[part 9 of 23: package /Cluster]
AUTOSAR XML (schema 4-3-0)
package /Cluster  (continued)
  can cluster E3V_EVCANFD: baudrate=500000, protocol-name=CAN, protocol-version=2.0, bus-off-recovery={bor-counter-l-1-to-l-2=1, bor-time-l-1=0.05, bor-time-l-2=0.2}, can-fd-baudrate=2000000  (continued)
    can physical channel CHNL: comm-connectors=CN_E3V_EVCANFD  (continued)
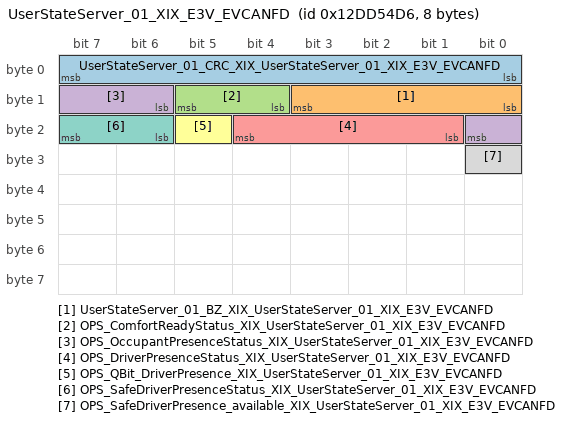
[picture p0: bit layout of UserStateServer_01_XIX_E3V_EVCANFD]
      frame UserStateServer_01_XIX_E3V_EVCANFD: id 0x12DD54D6, to Klima, frame-length=8, can-addressing-mode=EXTENDED, can-frame-rx-behavior=CAN-FD, can-frame-tx-behavior=CAN-FD
        pdu UserStateServer_01_XIX_E3V_EVCANFD: length=8, minimum-delay=0.01, transmission-mode-true-timing={cyclic-timing={time-offset=0.0, time-period=0.1}, event-controlled-timing={number-of-repetitions=5, repetition-period=0.01}}, unused-bit-pattern=0
          signal UserStateServer_01_CRC_XIX_UserStateServer_01_XIX_E3V_EVCANFD: start 0, 8 bit, little-endian, data-type-policy=OVERRIDE, i-signal-type=PRIMITIVE, base-type=BT_UserStateServer_01_CRC, compu {phys=raw for raw 0..255}, range phys 0..255, raw 0..255, transfer-property=PENDING  # Für MLB: Berechnung siehe Lastenheft "Kommunikationsabsicherung für FlexRay und CAN" Ab MQB und MLBevo: Berechnung siehe Lastenheft "End-to-End Kommunikationsabsicherung" Endwerte siehe Begleitdokument "S-PDU Kennungsfolgen"
          signal UserStateServer_01_BZ_XIX_UserStateServer_01_XIX_E3V_EVCANFD: start 8, 4 bit, little-endian, data-type-policy=OVERRIDE, i-signal-type=PRIMITIVE, base-type=BT_UserStateServer_01_BZ, compu {phys=raw for raw 0..15}, range phys 0..15, raw 0..15, transfer-property=PENDING  # 4bit Botschaftszähler, wird mit jeder Sendebotschaft inkrementiert
          signal OPS_ComfortReadyStatus_XIX_UserStateServer_01_XIX_E3V_EVCANFD: start 12, 2 bit, little-endian, data-type-policy=OVERRIDE, i-signal-type=PRIMITIVE, init-value=0, base-type=BT_OPS_ComfortReadyStatus, invalid-value=Invalid_OPS_ComfortReadyStatus_XIX_UserStateServer_01_XIX_E3V_EVCANFD:3, compu {0=Cx0_Init (CM_OPS_ComfortReadyStatus_Cx0_Init), 1=Cx1_aktiv (CM_OPS_ComfortReadyStatus_Cx1_aktiv), 2=Cx2_inaktiv (CM_OPS_ComfortReadyStatus_Cx2_inaktiv), 3=Cx3_Fehler (CM_OPS_ComfortReadyStatus_Cx3_Fehler)}, range raw 0..3, transfer-property=TRIGGERED-ON-CHANGE, to Klima(timeout 1 s)  # Das Signal wird durch den Basisdienst User State Server (Technikvariante: OccupantPresenceService) erzeugt und bildet einen neuen Zustand, bestehend aus einer Verknüpfung der Fahreranwesenheit (Fahrer abwesend / Fahrer anwesend) und der Klemmensteuerung (Klemme15/KlemmeS).Wird u.a. für das neue MEB Einstiegs-/Ausstiegskonzept verwendet.
          signal OPS_OccupantPresenceStatus_XIX_UserStateServer_01_XIX_E3V_EVCANFD: start 14, 3 bit, little-endian, data-type-policy=OVERRIDE, i-signal-type=PRIMITIVE, init-value=0, base-type=BT_OPS_OccupantPresenceStatus, invalid-value=Invalid_OPS_OccupantPresenceStatus_XIX_UserStateServer_01_XIX_E3V_EVCANFD:7, compu {0=Cx0_Init (CM_OPS_OccupantPresenceStatus_Cx0_Init), 1=Cx1_OccupantAbsent (CM_OPS_OccupantPresenceStatus_Cx1_OccupantAbsent), 2=Cx2_reserviert (CM_OPS_OccupantPresenceStatus_Cx2_reserviert), 3=Cx3_OccupantEntryExit (CM_OPS_OccupantPresenceStatus_Cx3_OccupantEntryExit), 4=Cx4_reserviert (CM_OPS_OccupantPresenceStatus_Cx4_reserviert), 5=Cx5_OccupantPresent (CM_OPS_OccupantPresenceStatus_Cx5_OccupantPresent), 6=Cx6_OccupantPresentVerified (CM_OPS_OccupantPresenceStatus_Cx6_OccupantPresentVerified), 7=Cx7_Fehler (CM_OPS_OccupantPresenceStatus_Cx7_Fehler)}, range raw 0..7, transfer-property=TRIGGERED-ON-CHANGE, to Klima(timeout 1 s)  # Das Signal wird durch den Basisdienst User State Server (Service: OccupantPresenceService) erzeugt und bildet die Anwesenheit und Abwesenheit aller Insassen im Fahrzeug ab.
          signal OPS_DriverPresenceStatus_XIX_UserStateServer_01_XIX_E3V_EVCANFD: start 17, 4 bit, little-endian, data-type-policy=OVERRIDE, i-signal-type=PRIMITIVE, init-value=0, base-type=BT_OPS_DriverPresenceStatus, invalid-value=Invalid_OPS_DriverPresenceStatus_XIX_UserStateServer_01_XIX_E3V_EVCANFD:15, compu {0=Cx0_Init (CM_OPS_DriverPresenceStatus_Cx0_Init), 1=Cx1_reserviert (CM_OPS_DriverPresenceStatus_Cx1_reserviert), 2=Cx2_DriverAbsent (CM_OPS_DriverPresenceStatus_Cx2_DriverAbsent), 3=Cx3_reserviert (CM_OPS_DriverPresenceStatus_Cx3_reserviert), 4=Cx4_DriverEntry (CM_OPS_DriverPresenceStatus_Cx4_DriverEntry), 5=Cx5_reserviert (CM_OPS_DriverPresenceStatus_Cx5_reserviert), 6=Cx6_DriverPresent (CM_OPS_DriverPresenceStatus_Cx6_DriverPresent), 7=Cx7_reserviert (CM_OPS_DriverPresenceStatus_Cx7_reserviert), 8=Cx8_DriverPresentVerified (CM_OPS_DriverPresenceStatus_Cx8_DriverPresentVerified), 9=Cx9_reserviert (CM_OPS_DriverPresenceStatus_Cx9_reserviert), 10=Cxa_reserviert (CM_OPS_DriverPresenceStatus_Cxa_reserviert), 11=Cxb_DriverExitIntent (CM_OPS_DriverPresenceStatus_Cxb_DriverExitIntent), 12=Cxc_reserviert (CM_OPS_DriverPresenceStatus_Cxc_reserviert), 13=Cxd_DriverExit (CM_OPS_DriverPresenceStatus_Cxd_DriverExit), 14=Cxe_reserviert (CM_OPS_DriverPresenceStatus_Cxe_reserviert), 15=Cxf_Fehler (CM_OPS_DriverPresenceStatus_Cxf_Fehler)}, range raw 0..15, transfer-property=TRIGGERED-ON-CHANGE, to Klima(timeout 1 s)  # Das Signal wird durch den Basisdienst User State Server (Service: OccupantPresenceService) erzeugt und bildet die Fahrerzustände im Fahrzeug ab.
          signal OPS_QBit_DriverPresence_XIX_UserStateServer_01_XIX_E3V_EVCANFD: start 21, 1 bit, little-endian, data-type-policy=OVERRIDE, i-signal-type=PRIMITIVE, init-value=1, base-type=BT_OPS_QBit_DriverPresence, compu {0=Cx0_gueltiger_Wert (CM_OPS_QBit_DriverPresence_Cx0_gueltiger_Wert), 1=Cx1_Ersatz_Init_oder_Fehlerwert (CM_OPS_QBit_DriverPresence_Cx1_Ersatz_Init_oder_Fehlerwert)}, range raw 0..1, transfer-property=TRIGGERED-ON-CHANGE, to Klima(timeout 1 s)  # Das Signal wird durch den Basisdienst User State Server (Service: OccupantPresenceService) erzeugt und signalisiert die Qualität der Fahrerzustände.
          signal OPS_SafeDriverPresenceStatus_XIX_UserStateServer_01_XIX_E3V_EVCANFD: start 22, 2 bit, little-endian, data-type-policy=OVERRIDE, i-signal-type=PRIMITIVE, init-value=0, base-type=BT_OPS_SafeDriverPresenceStatus, invalid-value=Invalid_OPS_SafeDriverPresenceStatus_XIX_UserStateServer_01_XIX_E3V_EVCANFD:3, compu {0=Cx0_Init (CM_OPS_SafeDriverPresenceStatus_Cx0_Init), 1=Cx1_Driver_Safe_Present (CM_OPS_SafeDriverPresenceStatus_Cx1_Driver_Safe_Present), 2=Cx2_Driver_Not_Safe_Present (CM_OPS_SafeDriverPresenceStatus_Cx2_Driver_Not_Safe_Present), 3=Cx3_Fehler (CM_OPS_SafeDriverPresenceStatus_Cx3_Fehler)}, range raw 0..3, transfer-property=TRIGGERED-ON-CHANGE  # Signalisierung einer sicheren Fahreranwesenheit nach ASIL B
          signal OPS_SafeDriverPresence_available_XIX_UserStateServer_01_XIX_E3V_EVCANFD: start 24, 1 bit, little-endian, data-type-policy=OVERRIDE, i-signal-type=PRIMITIVE, init-value=0, base-type=BT_OPS_SafeDriverPresence_available, compu {0=Cx0_Verfuegbar (CM_OPS_SafeDriverPresence_available_Cx0_Verfuegbar), 1=Cx1_Verfuegbar_eingeschr_Performance (CM_OPS_SafeDriverPresence_available_Cx1_Verfuegbar_eingeschr_Performance)}, range raw 0..1, transfer-property=TRIGGERED-ON-CHANGE  # Das Signal signalisiert inwiefern alle vorgesehene Sensoren für die Anwesenheit verwendet werden oder möglichweise bestimmte Sensoren nicht verfügbar sind. In beiden Fällen wird eine Anwesenheit berechnet, jedoch bei Ausfall bestimmter Sensoren kann zu bestimmten Einschränkungen führen. Das Signal wird funktional und ohne ASIL Güte bedient.
      frame VIN_01_XIX_E3V_EVCANFD: id 0x6B4, to Klima, frame-length=8, can-addressing-mode=STANDARD, can-frame-rx-behavior=CAN-FD, can-frame-tx-behavior=CAN-FD
        multiplexed i pdu VIN_01_XIX_E3V_EVCANFD:
          length=8
          dynamic-part{segment-position{segment-byte-order=little-endian, segment-length=64, segment-position=0}, dynamic-part-alternatives=[{i-pdu=VIN_01_Mx00_XIX_E3V_EVCANFD, initial-dynamic-part=true, selector-field-code=0}, {i-pdu=VIN_01_Mx01_XIX_E3V_EVCANFD, initial-dynamic-part=false, selector-field-code=1}, {i-pdu=VIN_01_Mx02_XIX_E3V_EVCANFD, initial-dynamic-part=false, selector-field-code=2}]}
          selector-field-byte-order=little-endian
          selector-field-length=2
          selector-field-start-position=0
          trigger-mode=DYNAMIC-PART-TRIGGER
          unused-bit-pattern=0
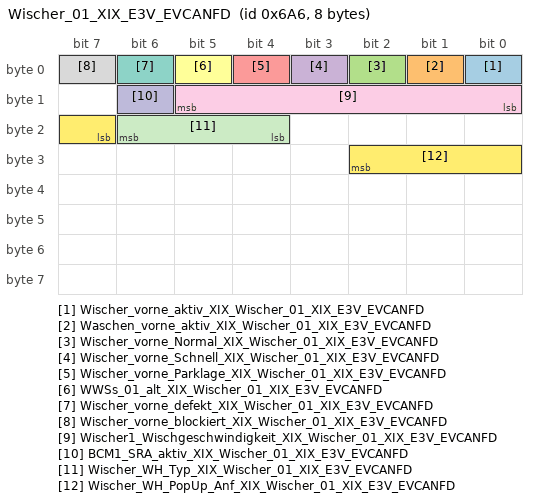
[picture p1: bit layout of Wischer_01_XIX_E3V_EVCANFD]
      frame Wischer_01_XIX_E3V_EVCANFD: id 0x6A6, to Klima, frame-length=8, can-addressing-mode=STANDARD, can-frame-rx-behavior=CAN-FD, can-frame-tx-behavior=CAN-FD
        pdu Wischer_01_XIX_E3V_EVCANFD: length=8, minimum-delay=0.05, transmission-mode-true-timing={cyclic-timing={time-offset=0.0, time-period=1.0}, event-controlled-timing={number-of-repetitions=0, repetition-period=0.0}}, unused-bit-pattern=0  # MLBevo
          signal Wischer_vorne_aktiv_XIX_Wischer_01_XIX_E3V_EVCANFD: start 0, 1 bit, little-endian, data-type-policy=OVERRIDE, i-signal-type=PRIMITIVE, init-value=0, base-type=BT_Wischer_vorne_aktiv, compu {0=Cx0_Init (CM_Wischer_vorne_aktiv_Cx0_Init), 1=Cx1_Wischer_vorne_laeuft (CM_Wischer_vorne_aktiv_Cx1_Wischer_vorne_laeuft)}, range raw 0..1, transfer-property=TRIGGERED-ON-CHANGE-WITHOUT-REPETITION, to Klima(timeout 5 s)  # Status: Wischer vorne
          signal Waschen_vorne_aktiv_XIX_Wischer_01_XIX_E3V_EVCANFD: start 1, 1 bit, little-endian, data-type-policy=OVERRIDE, i-signal-type=PRIMITIVE, init-value=0, base-type=BT_Waschen_vorne_aktiv, compu {0=Cx0_inaktiv (CM_Waschen_vorne_aktiv_Cx0_inaktiv), 1=Cx1_Waschen_aktiv (CM_Waschen_vorne_aktiv_Cx1_Waschen_aktiv)}, range raw 0..1, transfer-property=TRIGGERED-ON-CHANGE-WITHOUT-REPETITION, to Klima(timeout 5 s)  # Status: Waschen vorne aktiv
          signal Wischer_vorne_Normal_XIX_Wischer_01_XIX_E3V_EVCANFD: start 2, 1 bit, little-endian, data-type-policy=OVERRIDE, i-signal-type=PRIMITIVE, init-value=0, base-type=BT_Wischer_vorne_Normal, compu {1=Cx1_Wischer_Front_normal_aktiv (CM_Wischer_vorne_Normal_Cx1_Wischer_Front_normal_aktiv) (Wischer Front normal aktiv)}, range raw 1, transfer-property=TRIGGERED-ON-CHANGE-WITHOUT-REPETITION  # Wischer Front normal aktiv
          signal Wischer_vorne_Schnell_XIX_Wischer_01_XIX_E3V_EVCANFD: start 3, 1 bit, little-endian, data-type-policy=OVERRIDE, i-signal-type=PRIMITIVE, init-value=0, base-type=BT_Wischer_vorne_Schnell, compu {1=Cx1_Wischer_vorne_schnell_aktiv (CM_Wischer_vorne_Schnell_Cx1_Wischer_vorne_schnell_aktiv) (Wischer vorne schnell aktiv)}, range raw 1, transfer-property=TRIGGERED-ON-CHANGE-WITHOUT-REPETITION  # Wischer vorne schnell aktiv
          signal Wischer_vorne_Parklage_XIX_Wischer_01_XIX_E3V_EVCANFD: start 4, 1 bit, little-endian, data-type-policy=OVERRIDE, i-signal-type=PRIMITIVE, init-value=1, base-type=BT_Wischer_vorne_Parklage, compu {0=Cx0_Wischer_Front_nicht_in_Parklage (CM_Wischer_vorne_Parklage_Cx0_Wischer_Front_nicht_in_Parklage), 1=Cx1_Wischer_Front_in_Parklage_Initialzustand (CM_Wischer_vorne_Parklage_Cx1_Wischer_Front_in_Parklage_Initialzustand) (Wischer_Front_in_Parklage__Initialzustand)}, range raw 0..1, transfer-property=TRIGGERED-ON-CHANGE-WITHOUT-REPETITION  # Wischer Front in Parklage
          signal WWSs_01_alt_XIX_Wischer_01_XIX_E3V_EVCANFD: start 5, 1 bit, little-endian, data-type-policy=OVERRIDE, i-signal-type=PRIMITIVE, init-value=1, base-type=BT_WWSs_01_alt, compu {0=Cx0_aktuell (CM_WWSs_01_alt_Cx0_aktuell), 1=Cx1_veraltet (CM_WWSs_01_alt_Cx1_veraltet)}, range raw 0..1, transfer-property=PENDING  # Veraltet Bit für die LIN-Botschaft WWSs_01. Betroffene Signale: Wischer_vorne_aktiv
          signal Wischer_vorne_defekt_XIX_Wischer_01_XIX_E3V_EVCANFD: start 6, 1 bit, little-endian, data-type-policy=OVERRIDE, i-signal-type=PRIMITIVE, init-value=0, base-type=BT_Wischer_vorne_defekt, compu {0=Cx0_Init (CM_Wischer_vorne_defekt_Cx0_Init), 1=Cx1_Wischer_vorne_defekt (CM_Wischer_vorne_defekt_Cx1_Wischer_vorne_defekt) (Wischer vorne defekt)}, range raw 0..1, transfer-property=TRIGGERED-ON-CHANGE-WITHOUT-REPETITION, to Klima(timeout 5 s)  # Fehlerstatus Wischer vorne (Anzeige im Kombi)
          signal Wischer_vorne_blockiert_XIX_Wischer_01_XIX_E3V_EVCANFD: start 7, 1 bit, little-endian, data-type-policy=OVERRIDE, i-signal-type=PRIMITIVE, init-value=0, base-type=BT_Wischer_vorne_blockiert, compu {1=Cx1_Wischer_vorne_blockiert (CM_Wischer_vorne_blockiert_Cx1_Wischer_vorne_blockiert) (Wischer vorne blockiert)}, range raw 1, transfer-property=TRIGGERED-ON-CHANGE-WITHOUT-REPETITION  # Blockade Wischer vorne (z.B. durch Schnee)
          signal Wischer1_Wischgeschwindigkeit_XIX_Wischer_01_XIX_E3V_EVCANFD: start 8, 6 bit, little-endian, data-type-policy=OVERRIDE, i-signal-type=PRIMITIVE, init-value=62, base-type=BT_Wischer1_Wischgeschwindigkeit, invalid-value=Invalid_Wischer1_Wischgeschwindigkeit_XIX_Wischer_01_XIX_E3V_EVCANFD:63, compu {0=Cx0_0_U_min (CM_Wischer1_Wischgeschwindigkeit_Cx0_0_U_min) (0 U/min), phys=raw+9 for raw 1..61, 62=Cx3e_Init (CM_Wischer1_Wischgeschwindigkeit_Cx3e_Init), 63=Cx3f_Fehler (CM_Wischer1_Wischgeschwindigkeit_Cx3f_Fehler); unit Unit_MinutInver}, range phys 10..70 Unit_MinutInver, raw 0..63, unit=Unit_MinutInver, transfer-property=PENDING, to Klima(timeout 5 s)  # aktuelle, durch Sensorik gemessene Wischgeschwindigkeit
          signal BCM1_SRA_aktiv_XIX_Wischer_01_XIX_E3V_EVCANFD: start 14, 1 bit, little-endian, data-type-policy=OVERRIDE, i-signal-type=PRIMITIVE, init-value=0, base-type=BT_BCM1_SRA_aktiv, compu {0=Cx0_nicht_aktiv (CM_BCM1_SRA_aktiv_Cx0_nicht_aktiv) (nicht aktiv), 1=Cx1_aktiv (CM_BCM1_SRA_aktiv_Cx1_aktiv)}, range raw 0..1, transfer-property=TRIGGERED-ON-CHANGE-WITHOUT-REPETITION  # Status Scheinwerferreinigungsanlage
          signal Wischer_WH_Typ_XIX_Wischer_01_XIX_E3V_EVCANFD: start 20, 3 bit, little-endian, data-type-policy=OVERRIDE, i-signal-type=PRIMITIVE, init-value=0, base-type=BT_Wischer_WH_Typ, compu {0=Cx0_Lenkstockschalter_0_Int_Stufen (CM_Wischer_WH_Typ_Cx0_Lenkstockschalter_0_Int_Stufen), 1=Cx1_Lenkstockschalter_2_Int_Stufen (CM_Wischer_WH_Typ_Cx1_Lenkstockschalter_2_Int_Stufen), 2=Cx2_Lenkstockschalter_4_Int_Stufen (CM_Wischer_WH_Typ_Cx2_Lenkstockschalter_4_Int_Stufen)}, range raw 0..2, transfer-property=PENDING  # Signal beinhaltet Lenkstockschaltertyp für grafische Anzeige im Kombi zur Wischerfunktion
          signal Wischer_WH_PopUp_Anf_XIX_Wischer_01_XIX_E3V_EVCANFD: start 23, 4 bit, little-endian, data-type-policy=OVERRIDE, i-signal-type=PRIMITIVE, init-value=0, base-type=BT_Wischer_WH_PopUp_Anf, compu {0=Cx0_keine_Anzeige (CM_Wischer_WH_PopUp_Anf_Cx0_keine_Anzeige), 1=Cx1_Intervallstufe_1_aktiv (CM_Wischer_WH_PopUp_Anf_Cx1_Intervallstufe_1_aktiv), 2=Cx2_Intervallstufe_2_aktiv (CM_Wischer_WH_PopUp_Anf_Cx2_Intervallstufe_2_aktiv), 3=Cx3_Intervallstufe_3_aktiv (CM_Wischer_WH_PopUp_Anf_Cx3_Intervallstufe_3_aktiv), 4=Cx4_Intervallstufe_4_aktiv (CM_Wischer_WH_PopUp_Anf_Cx4_Intervallstufe_4_aktiv), 5=Cx5_Regensensorstufe_1_aktiv (CM_Wischer_WH_PopUp_Anf_Cx5_Regensensorstufe_1_aktiv), 6=Cx6_Regensensorstufe_2_aktiv (CM_Wischer_WH_PopUp_Anf_Cx6_Regensensorstufe_2_aktiv), 7=Cx7_Regensensorstufe_3_aktiv (CM_Wischer_WH_PopUp_Anf_Cx7_Regensensorstufe_3_aktiv), 8=Cx8_Regensensorstufe_4_aktiv (CM_Wischer_WH_PopUp_Anf_Cx8_Regensensorstufe_4_aktiv), 9=Cx9_Wischerstufe_1_aktiv (CM_Wischer_WH_PopUp_Anf_Cx9_Wischerstufe_1_aktiv), 10=Cxa_Wischerstufe_2_aktiv (CM_Wischer_WH_PopUp_Anf_Cxa_Wischerstufe_2_aktiv), 11=Cxb_Tippwischen_aktiv (CM_Wischer_WH_PopUp_Anf_Cxb_Tippwischen_aktiv), 12=Cxc_Heckwischen_aktiv (CM_Wischer_WH_PopUp_Anf_Cxc_Heckwischen_aktiv)}, range raw 0..12, transfer-property=TRIGGERED-ON-CHANGE-WITHOUT-REPETITION  # Anzeige von Wischerstufen im Kombi.
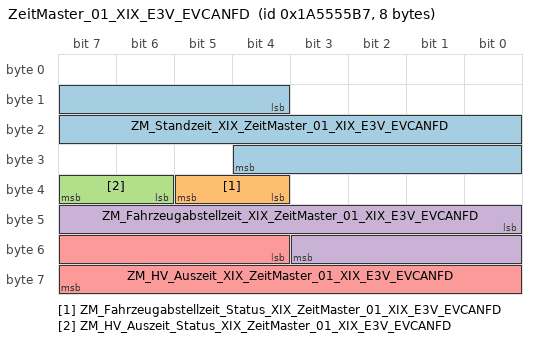
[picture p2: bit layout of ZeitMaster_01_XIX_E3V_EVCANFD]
      frame ZeitMaster_01_XIX_E3V_EVCANFD: id 0x1A5555B7, to Klima, frame-length=8, can-addressing-mode=EXTENDED, can-frame-rx-behavior=CAN-FD, can-frame-tx-behavior=CAN-FD
        pdu ZeitMaster_01_XIX_E3V_EVCANFD: length=8, transmission-mode-true-timing=cyclic-timing={time-offset=0.0, time-period=1.0}, unused-bit-pattern=0
          signal ZM_Standzeit_XIX_ZeitMaster_01_XIX_E3V_EVCANFD: start 12, 17 bit, little-endian, data-type-policy=OVERRIDE, i-signal-type=PRIMITIVE, init-value=131070, base-type=BT_ZM_Standzeit, invalid-value=Invalid_ZM_Standzeit_XIX_ZeitMaster_01_XIX_E3V_EVCANFD:131071, compu {phys=raw for raw 0..131068, 131069=Cx1fffd_nicht_verfuegbar (CM_ZM_Standzeit_Cx1fffd_nicht_verfuegbar), 131070=Cx1fffe_Init (CM_ZM_Standzeit_Cx1fffe_Init), 131071=Cx1ffff_Fehler (CM_ZM_Standzeit_Cx1ffff_Fehler); unit Unit_Secon}, range phys 0..131068 Unit_Secon, raw 0..131071, unit=Unit_Secon, transfer-property=PENDING, to Klima(timeout 5 s)  # Standzeit des Fahrzeugs
          signal ZM_Fahrzeugabstellzeit_Status_XIX_ZeitMaster_01_XIX_E3V_EVCANFD: start 36, 2 bit, little-endian, data-type-policy=OVERRIDE, i-signal-type=PRIMITIVE, init-value=0, base-type=BT_ZM_Fahrzeugabstellzeit_Status, compu {0=Cx0_Abstellzeit_nicht_berechnet (CM_ZM_Fahrzeugabstellzeit_Status_Cx0_Abstellzeit_nicht_berechnet), 1=Cx1_Abstellzeit_berechnet (CM_ZM_Fahrzeugabstellzeit_Status_Cx1_Abstellzeit_berechnet), 2=Cx2_Abstellzeit_Minimalwert (CM_ZM_Fahrzeugabstellzeit_Status_Cx2_Abstellzeit_Minimalwert), 3=Cx3_Abstellzeit_ungueltig (CM_ZM_Fahrzeugabstellzeit_Status_Cx3_Abstellzeit_ungueltig)}, range raw 0..3, transfer-property=PENDING  # Status Fahrzeugabstellzeit
          signal ZM_HV_Auszeit_Status_XIX_ZeitMaster_01_XIX_E3V_EVCANFD: start 38, 2 bit, little-endian, data-type-policy=OVERRIDE, i-signal-type=PRIMITIVE, init-value=0, base-type=BT_ZM_HV_Auszeit_Status, compu {0=Cx0_nicht_berechnet (CM_ZM_HV_Auszeit_Status_Cx0_nicht_berechnet), 1=Cx1_berechnet (CM_ZM_HV_Auszeit_Status_Cx1_berechnet), 2=Cx2_Minimalwert (CM_ZM_HV_Auszeit_Status_Cx2_Minimalwert), 3=Cx3_ungueltig (CM_ZM_HV_Auszeit_Status_Cx3_ungueltig)}, range raw 0..3, transfer-property=PENDING  # Status HV-Auszeit
          signal ZM_Fahrzeugabstellzeit_XIX_ZeitMaster_01_XIX_E3V_EVCANFD: start 40, 12 bit, little-endian, data-type-policy=OVERRIDE, i-signal-type=PRIMITIVE, init-value=4094, base-type=BT_ZM_Fahrzeugabstellzeit, invalid-value=Invalid_ZM_Fahrzeugabstellzeit_XIX_ZeitMaster_01_XIX_E3V_EVCANFD:4095, compu {phys=raw*4 for raw 0..4093, 4094=Cxffe_Init (CM_ZM_Fahrzeugabstellzeit_Cxffe_Init), 4095=Cxfff_Fehler (CM_ZM_Fahrzeugabstellzeit_Cxfff_Fehler); unit Unit_Minut}, range phys 0..16372 Unit_Minut, raw 0..4095, unit=Unit_Minut, transfer-property=PENDING  # Zeit seit letzter Fahrbereitschaft
          signal ZM_HV_Auszeit_XIX_ZeitMaster_01_XIX_E3V_EVCANFD: start 52, 12 bit, little-endian, data-type-policy=OVERRIDE, i-signal-type=PRIMITIVE, init-value=4094, base-type=BT_ZM_HV_Auszeit, invalid-value=Invalid_ZM_HV_Auszeit_XIX_ZeitMaster_01_XIX_E3V_EVCANFD:4095, compu {phys=raw*4 for raw 0..4093, 4094=Cxffe_Init (CM_ZM_HV_Auszeit_Cxffe_Init), 4095=Cxfff_Fehler (CM_ZM_HV_Auszeit_Cxfff_Fehler); unit Unit_Minut}, range phys 0..16372 Unit_Minut, raw 0..4095, unit=Unit_Minut, transfer-property=PENDING  # Zeit seit letzter Hochvoltaktivität
      frame ZV_02_XIX_E3V_EVCANFD: id 0x583, to Klima, frame-length=8, can-addressing-mode=STANDARD, can-frame-rx-behavior=CAN-FD, can-frame-tx-behavior=CAN-FD
        pdu ZV_02_XIX_E3V_EVCANFD: length=8, minimum-delay=0.02, transmission-mode-false-timing={cyclic-timing={time-offset=0.0, time-period=0.2}, event-controlled-timing={number-of-repetitions=3, repetition-period=0.05}}, transmission-mode-true-timing={cyclic-timing={time-offset=0.0, time-period=0.05}, event-controlled-timing={number-of-repetitions=0, repetition-period=0.0}}, unused-bit-pattern=0
          transmission-mode-conditions:
            {data-filter={data-filter-type=MASKED-NEW-DIFFERS-X, mask=1, x=0}, i-signal-in-i-pdu=ZV_verriegeln_Anf}
            {data-filter={data-filter-type=MASKED-NEW-DIFFERS-X, mask=1, x=0}, i-signal-in-i-pdu=ZV_Anf_Challenge_Auth}
            {data-filter={data-filter-type=MASKED-NEW-DIFFERS-X, mask=1, x=0}, i-signal-in-i-pdu=ZV_eRWK_Umfeld_Pruefung}
            {data-filter={data-filter-type=MASKED-NEW-DIFFERS-X, mask=1, x=0}, i-signal-in-i-pdu=VIP_Sensor_STSG_HFS_betaetigt}
            {data-filter={data-filter-type=MASKED-NEW-DIFFERS-X, mask=1, x=0}, i-signal-in-i-pdu=VIP_Sensor_STSG_HBFS_betaetigt}
            {data-filter={data-filter-type=MASKED-NEW-DIFFERS-X, mask=1, x=0}, i-signal-in-i-pdu=FFB_HDF_Taste}
            {data-filter={data-filter-type=MASKED-NEW-DIFFERS-X, mask=1, x=0}, i-signal-in-i-pdu=FFB_Panik_Taste}
            {data-filter={data-filter-type=MASKED-NEW-DIFFERS-X, mask=1, x=0}, i-signal-in-i-pdu=FFB_Auf_Taste}
            {data-filter={data-filter-type=MASKED-NEW-DIFFERS-X, mask=1, x=0}, i-signal-in-i-pdu=FFB_Zu_Taste}
            {data-filter={data-filter-type=MASKED-NEW-DIFFERS-X, mask=1, x=0}, i-signal-in-i-pdu=FFB_CarFinder}
            {data-filter={data-filter-type=MASKED-NEW-DIFFERS-X, mask=1, x=0}, i-signal-in-i-pdu=FFB_Komfortoeffnen}
            {data-filter={data-filter-type=MASKED-NEW-DIFFERS-X, mask=1, x=0}, i-signal-in-i-pdu=FFB_Komfortschliessen}
            {data-filter={data-filter-type=MASKED-NEW-DIFFERS-X, mask=1, x=0}, i-signal-in-i-pdu=FBS_IDG_in_Reichweite}
          signal ZV_verriegeln_Anf_XIX_ZV_02_XIX_E3V_EVCANFD: start 0, 1 bit, little-endian, data-type-policy=OVERRIDE, i-signal-type=PRIMITIVE, init-value=0, base-type=BT_ZV_verriegeln_Anf, compu {0=Cx0_nicht_betaetigt (CM_ZV_verriegeln_Anf_Cx0_nicht_betaetigt), 1=Cx1_betaetigt (CM_ZV_verriegeln_Anf_Cx1_betaetigt)}, range raw 0..1, transfer-property=PENDING  # Gesammelte externe ZV-Verriegelungsanforderung des Kunden (z. B. zur Aktivierung der Anzeige des Ladezustands über Aussenlicht).
          signal ZV_STSG_HFS_Anf_XIX_ZV_02_XIX_E3V_EVCANFD: start 1, 1 bit, little-endian, data-type-policy=OVERRIDE, i-signal-type=PRIMITIVE, init-value=0, base-type=BT_ZV_STSG_HFS_Anf, compu {0=Cx0_keine_Anforderung (CM_ZV_STSG_HFS_Anf_Cx0_keine_Anforderung), 1=Cx1_Anforderung (CM_ZV_STSG_HFS_Anf_Cx1_Anforderung)}, range raw 0..1, transfer-property=TRIGGERED-ON-CHANGE-WITHOUT-REPETITION  # Die ZV fordert einen Lauf bzw. Stopp der Schiebetür an.
          signal ZV_STSG_HBFS_Anf_XIX_ZV_02_XIX_E3V_EVCANFD: start 2, 1 bit, little-endian, data-type-policy=OVERRIDE, i-signal-type=PRIMITIVE, init-value=0, base-type=BT_ZV_STSG_HBFS_Anf, compu {0=Cx0_keine_Anforderung (CM_ZV_STSG_HBFS_Anf_Cx0_keine_Anforderung), 1=Cx1_Anforderung (CM_ZV_STSG_HBFS_Anf_Cx1_Anforderung)}, range raw 0..1, transfer-property=TRIGGERED-ON-CHANGE-WITHOUT-REPETITION  # Die ZV fordert einen Lauf bzw. Stopp der Schiebetür an.
          signal ZV_Anf_Challenge_Auth_XIX_ZV_02_XIX_E3V_EVCANFD: start 3, 1 bit, little-endian, data-type-policy=OVERRIDE, i-signal-type=PRIMITIVE, init-value=0, base-type=BT_ZV_Anf_Challenge_Auth, compu {0=Cx0_nicht_aktiv (CM_ZV_Anf_Challenge_Auth_Cx0_nicht_aktiv), 1=Cx1_aktiv (CM_ZV_Anf_Challenge_Auth_Cx1_aktiv)}, range raw 0..1, transfer-property=PENDING  # Anforderung an alle beteiligten Steuergeräte die Challenge an den ZV-Master zu senden.
          signal ZV_eRWK_Umfeld_Pruefung_XIX_ZV_02_XIX_E3V_EVCANFD: start 6, 1 bit, little-endian, data-type-policy=OVERRIDE, i-signal-type=PRIMITIVE, init-value=0, base-type=BT_ZV_eRWK_Umfeld_Pruefung, compu {0=Cx0_nicht_aktiv (CM_ZV_eRWK_Umfeld_Pruefung_Cx0_nicht_aktiv), 1=Cx1_aktiv (CM_ZV_eRWK_Umfeld_Pruefung_Cx1_aktiv)}, range raw 0..1, transfer-property=PENDING  # Anforderung an PDC/PLA im eRWK-Modus eine Umfeldprüfung durchzuführen
          signal VIP_Sensor_STSG_HFS_betaetigt_XIX_ZV_02_XIX_E3V_EVCANFD: start 10, 1 bit, little-endian, data-type-policy=OVERRIDE, i-signal-type=PRIMITIVE, init-value=0, base-type=BT_VIP_Sensor_STSG_HFS_betaetigt, compu {0=Cx0_keine_VIP_Anforderung_STSG_HFS (CM_VIP_Sensor_STSG_HFS_betaetigt_Cx0_keine_VIP_Anforderung_STSG_HFS), 1=Cx1_VIP_Anforderung_STSG_HFS (CM_VIP_Sensor_STSG_HFS_betaetigt_Cx1_VIP_Anforderung_STSG_HFS)}, range raw 0..1, transfer-property=PENDING  # Schiebetürlauf HFS wurde durch VIP angefordert und als berechtigt eingestuft.
          signal VIP_Sensor_STSG_HBFS_betaetigt_XIX_ZV_02_XIX_E3V_EVCANFD: start 11, 1 bit, little-endian, data-type-policy=OVERRIDE, i-signal-type=PRIMITIVE, init-value=0, base-type=BT_VIP_Sensor_STSG_HBFS_betaetigt, compu {0=Cx0_keine_VIP_Anforderung_STSG_HBFS (CM_VIP_Sensor_STSG_HBFS_betaetigt_Cx0_keine_VIP_Anforderung_STSG_HBFS), 1=Cx1_VIP_Anforderung_STSG_HBFS (CM_VIP_Sensor_STSG_HBFS_betaetigt_Cx1_VIP_Anforderung_STSG_HBFS)}, range raw 0..1, transfer-property=PENDING  # Schiebetürlauf HBFS wurde durch VIP angefordert und als berechtigt eingestuft.
          signal BCM_FH_Freigabe_XIX_ZV_02_XIX_E3V_EVCANFD: start 12, 1 bit, little-endian, data-type-policy=OVERRIDE, i-signal-type=PRIMITIVE, init-value=0, base-type=BT_BCM_FH_Freigabe, compu {1=Cx1_Funktionsfreigabe_Fensterheber (CM_BCM_FH_Freigabe_Cx1_Funktionsfreigabe_Fensterheber) (Funktionsfreigabe Fensterheber)}, range raw 1, transfer-property=TRIGGERED-ON-CHANGE-WITHOUT-REPETITION  # Funktionsfreigabe Fensterheber
          signal BCM_Komfortfkt_Freigabe_XIX_ZV_02_XIX_E3V_EVCANFD: start 13, 1 bit, little-endian, data-type-policy=OVERRIDE, i-signal-type=PRIMITIVE, init-value=0, base-type=BT_BCM_Komfortfkt_Freigabe, compu {0=Cx0_Komfortfunktion_gesperrt (CM_BCM_Komfortfkt_Freigabe_Cx0_Komfortfunktion_gesperrt) (Komfortfunktion gesperrt), 1=Cx1_globale_Freigabe_der_Komfortfunktion_erteilt (CM_BCM_Komfortfkt_Freigabe_Cx1_globale_Freigabe_der_Komfortfunktion_erteilt) (globale Freigabe der Komfortfunktion erteilt)}, range raw 0..1, transfer-property=TRIGGERED-ON-CHANGE-WITHOUT-REPETITION  # globale Freigabe der Komfortfunktion
          signal BCM_HSK_Freigabe_XIX_ZV_02_XIX_E3V_EVCANFD: start 14, 1 bit, little-endian, data-type-policy=OVERRIDE, i-signal-type=PRIMITIVE, init-value=0, base-type=BT_BCM_HSK_Freigabe, compu {0=Cx0_erlauben (CM_BCM_HSK_Freigabe_Cx0_erlauben), 1=Cx1_sperren (CM_BCM_HSK_Freigabe_Cx1_sperren)}, range raw 0..1, transfer-property=TRIGGERED-ON-CHANGE-WITHOUT-REPETITION  # Handschuhkastenfreigabe
          signal BCM_Verdeck_Freigabe_XIX_ZV_02_XIX_E3V_EVCANFD: start 15, 1 bit, little-endian, data-type-policy=OVERRIDE, i-signal-type=PRIMITIVE, init-value=0, base-type=BT_BCM_Verdeck_Freigabe, compu {0=Cx0_Verdeckbetrieb_nicht_erlaubt (CM_BCM_Verdeck_Freigabe_Cx0_Verdeckbetrieb_nicht_erlaubt) (Verdeckbetrieb nicht erlaubt), 1=Cx1_Verdeckbetrieb_erlaubt (CM_BCM_Verdeck_Freigabe_Cx1_Verdeckbetrieb_erlaubt) (Verdeckbetrieb erlaubt)}, range raw 0..1, transfer-property=TRIGGERED-ON-CHANGE-WITHOUT-REPETITION  # Freigabe Verdeckbetrieb
          signal ZV_verriegelt_intern_ist_XIX_ZV_02_XIX_E3V_EVCANFD: start 16, 1 bit, little-endian, data-type-policy=OVERRIDE, i-signal-type=PRIMITIVE, init-value=0, base-type=BT_ZV_verriegelt_intern_ist, compu {1=Cx1_Fahrzeug_innen_verriegelt_Istzustand (CM_ZV_verriegelt_intern_ist_Cx1_Fahrzeug_innen_verriegelt_Istzustand) (Fahrzeug innen verriegelt; Istzustand)}, range raw 1, transfer-property=TRIGGERED-ON-CHANGE-WITHOUT-REPETITION, to Klima(timeout 2 s)  # Istzustand: Verriegelung Fahrzeug innen
          signal ZV_verriegelt_extern_ist_XIX_ZV_02_XIX_E3V_EVCANFD: start 17, 1 bit, little-endian, data-type-policy=OVERRIDE, i-signal-type=PRIMITIVE, init-value=0, base-type=BT_ZV_verriegelt_extern_ist, compu {1=Cx1_Fahrzeug_aussen_verriegelt_Istzustand (CM_ZV_verriegelt_extern_ist_Cx1_Fahrzeug_aussen_verriegelt_Istzustand)}, range raw 1, transfer-property=TRIGGERED-ON-CHANGE-WITHOUT-REPETITION, to Klima(timeout 2 s)  # Istzustand: Verriegelung Fahrzeug aussen
          signal ZV_verriegelt_intern_soll_XIX_ZV_02_XIX_E3V_EVCANFD: start 18, 1 bit, little-endian, data-type-policy=OVERRIDE, i-signal-type=PRIMITIVE, init-value=0, base-type=BT_ZV_verriegelt_intern_soll, compu {1=Cx1_Fahrzeug_verriegelt_intern_Sollzusstand (CM_ZV_verriegelt_intern_soll_Cx1_Fahrzeug_verriegelt_intern_Sollzusstand) (Fahrzeug verriegelt intern; Sollzusstand)}, range raw 1, transfer-property=TRIGGERED-ON-CHANGE-WITHOUT-REPETITION, to Klima(timeout 2 s)  # Sollzustand: Verriegelung Fahrzeug innen
          signal ZV_verriegelt_extern_soll_XIX_ZV_02_XIX_E3V_EVCANFD: start 19, 1 bit, little-endian, data-type-policy=OVERRIDE, i-signal-type=PRIMITIVE, init-value=0, base-type=BT_ZV_verriegelt_extern_soll, compu {1=Cx1_Fahrzeug_verriegelt_extern_Sollzusstand (CM_ZV_verriegelt_extern_soll_Cx1_Fahrzeug_verriegelt_extern_Sollzusstand) (Fahrzeug verriegelt extern; Sollzusstand)}, range raw 1, transfer-property=TRIGGERED-ON-CHANGE-WITHOUT-REPETITION, to Klima(timeout 2 s)  # Sollzustand: Verriegelung Fahrzeug aussen
          signal ZV_gesafet_extern_ist_XIX_ZV_02_XIX_E3V_EVCANFD: start 20, 1 bit, little-endian, data-type-policy=OVERRIDE, i-signal-type=PRIMITIVE, init-value=0, base-type=BT_ZV_gesafet_extern_ist, compu {1=Cx1_Fahrzeug_aussen_gesafet_Istzustand (CM_ZV_gesafet_extern_ist_Cx1_Fahrzeug_aussen_gesafet_Istzustand) (Fahrzeug aussen gesafet; Istzustand)}, range raw 1, transfer-property=TRIGGERED-ON-CHANGE-WITHOUT-REPETITION, to Klima(timeout 2 s)  # Istzustand: Fahrzeug aussen gesafet
          signal ZV_gesafet_extern_soll_XIX_ZV_02_XIX_E3V_EVCANFD: start 21, 1 bit, little-endian, data-type-policy=OVERRIDE, i-signal-type=PRIMITIVE, init-value=0, base-type=BT_ZV_gesafet_extern_soll, compu {1=Cx1_Fahrzeug_aussen_gesafet_Sollzustand (CM_ZV_gesafet_extern_soll_Cx1_Fahrzeug_aussen_gesafet_Sollzustand)}, range raw 1, transfer-property=TRIGGERED-ON-CHANGE-WITHOUT-REPETITION  # Sollzustand: Fahrzeug gesafet extern
          signal ZV_Einzeltuerentriegelung_XIX_ZV_02_XIX_E3V_EVCANFD: start 22, 1 bit, little-endian, data-type-policy=OVERRIDE, i-signal-type=PRIMITIVE, init-value=0, base-type=BT_ZV_Einzeltuerentriegelung, compu {1=Cx1_Fahrzeug_an_Einzeltuer_entriegelt (CM_ZV_Einzeltuerentriegelung_Cx1_Fahrzeug_an_Einzeltuer_entriegelt) (Fahrzeug an Einzeltuer entriegelt)}, range raw 1, transfer-property=TRIGGERED-ON-CHANGE-WITHOUT-REPETITION  # Einzeltürentriegelung ZV
          signal ZV_Heckeinzelentriegelung_XIX_ZV_02_XIX_E3V_EVCANFD: start 23, 1 bit, little-endian, data-type-policy=OVERRIDE, i-signal-type=PRIMITIVE, init-value=0, base-type=BT_ZV_Heckeinzelentriegelung, compu {1=Cx1_Heckdeckeleinzelentriegelung (CM_ZV_Heckeinzelentriegelung_Cx1_Heckdeckeleinzelentriegelung)}, range raw 1, transfer-property=TRIGGERED-ON-CHANGE-WITHOUT-REPETITION  # Heckdeckeleinzelentriegelung
          signal ZV_FT_offen_XIX_ZV_02_XIX_E3V_EVCANFD: start 24, 1 bit, little-endian, data-type-policy=OVERRIDE, i-signal-type=PRIMITIVE, init-value=0, base-type=BT_ZV_FT_offen, compu {0=Cx0_FT_geschlossen (CM_ZV_FT_offen_Cx0_FT_geschlossen), 1=Cx1_FT_geoeffnet (CM_ZV_FT_offen_Cx1_FT_geoeffnet)}, range raw 0..1, transfer-property=TRIGGERED-ON-CHANGE-WITHOUT-REPETITION, to Klima(timeout 2 s)  # gespiegeltes Bit FT_Tuer_geoeffnet TSG_FT_1 Botschaft
          signal ZV_BT_offen_XIX_ZV_02_XIX_E3V_EVCANFD: start 25, 1 bit, little-endian, data-type-policy=OVERRIDE, i-signal-type=PRIMITIVE, init-value=0, base-type=BT_ZV_BT_offen, compu {0=Cx0_BT_geschlossen (CM_ZV_BT_offen_Cx0_BT_geschlossen), 1=Cx1_BT_geoeffnet (CM_ZV_BT_offen_Cx1_BT_geoeffnet)}, range raw 0..1, transfer-property=TRIGGERED-ON-CHANGE-WITHOUT-REPETITION, to Klima(timeout 2 s)  # gespiegeltes Bit BT_Tuer_geoeffnet TSG_BT_1 Botschaft
          signal ZV_HFS_offen_XIX_ZV_02_XIX_E3V_EVCANFD: start 26, 1 bit, little-endian, data-type-policy=OVERRIDE, i-signal-type=PRIMITIVE, init-value=0, base-type=BT_ZV_HFS_offen, compu {0=Cx0_geschlossen (CM_ZV_HFS_offen_Cx0_geschlossen), 1=Cx1_offen (CM_ZV_HFS_offen_Cx1_offen)}, range raw 0..1, transfer-property=TRIGGERED-ON-CHANGE-WITHOUT-REPETITION, to Klima(timeout 2 s)  # gespiegeltes Bit HFS_Tuer_geoeffnet TSG_HFS_1 Botschaft
          signal ZV_HBFS_offen_XIX_ZV_02_XIX_E3V_EVCANFD: start 27, 1 bit, little-endian, data-type-policy=OVERRIDE, i-signal-type=PRIMITIVE, init-value=0, base-type=BT_ZV_HBFS_offen, compu {0=Cx0_geschlossen (CM_ZV_HBFS_offen_Cx0_geschlossen), 1=Cx1_offen (CM_ZV_HBFS_offen_Cx1_offen)}, range raw 0..1, transfer-property=TRIGGERED-ON-CHANGE-WITHOUT-REPETITION, to Klima(timeout 2 s)  # gespiegeltes Bit HBFS_Tuer_geoeffnet TSG_HBFS_1 Botschaft
          signal ZV_HD_offen_XIX_ZV_02_XIX_E3V_EVCANFD: start 28, 1 bit, little-endian, data-type-policy=OVERRIDE, i-signal-type=PRIMITIVE, init-value=0, base-type=BT_ZV_HD_offen, compu {1=Cx1_Heckdeckel_auf (CM_ZV_HD_offen_Cx1_Heckdeckel_auf)}, range raw 1, transfer-property=TRIGGERED-ON-CHANGE-WITHOUT-REPETITION, to Klima(timeout 2 s)  # Status Heckdeckel
          signal ZV_HS_offen_XIX_ZV_02_XIX_E3V_EVCANFD: start 29, 1 bit, little-endian, data-type-policy=OVERRIDE, i-signal-type=PRIMITIVE, init-value=0, base-type=BT_ZV_HS_offen, compu {0=Cx0_Heckscheibe_geschlossen (CM_ZV_HS_offen_Cx0_Heckscheibe_geschlossen), 1=Cx1_Heckscheibe_auf (CM_ZV_HS_offen_Cx1_Heckscheibe_auf) (Heckscheibe auf)}, range raw 0..1, transfer-property=TRIGGERED-ON-CHANGE-WITHOUT-REPETITION  # Status Heckscheibe
          signal IRUE_aktiv_XIX_ZV_02_XIX_E3V_EVCANFD: start 30, 1 bit, little-endian, data-type-policy=OVERRIDE, i-signal-type=PRIMITIVE, init-value=0, base-type=BT_IRUE_aktiv, compu {0=Cx0_unscharf (CM_IRUE_aktiv_Cx0_unscharf), 1=Cx1_scharf (CM_IRUE_aktiv_Cx1_scharf)}, range raw 0..1, transfer-property=TRIGGERED-ON-CHANGE-WITHOUT-REPETITION  # Status Innenraumüberwachung
          signal DWA_aktiv_XIX_ZV_02_XIX_E3V_EVCANFD: start 31, 1 bit, little-endian, data-type-policy=OVERRIDE, i-signal-type=PRIMITIVE, init-value=0, base-type=BT_DWA_aktiv, compu {0=Cx0_unscharf (CM_DWA_aktiv_Cx0_unscharf), 1=Cx1_scharf (CM_DWA_aktiv_Cx1_scharf)}, range raw 0..1, transfer-property=TRIGGERED-ON-CHANGE-WITHOUT-REPETITION  # Status DWA aktiv
          signal FFB_HDF_Taste_XIX_ZV_02_XIX_E3V_EVCANFD: start 34, 1 bit, little-endian, data-type-policy=OVERRIDE, i-signal-type=PRIMITIVE, init-value=0, base-type=BT_FFB_HDF_Taste, compu {0=Cx0_Taste_nicht_betaetigt (CM_FFB_HDF_Taste_Cx0_Taste_nicht_betaetigt), 1=Cx1_HDF_Taste_am_Funkschluessel_betaetigt (CM_FFB_HDF_Taste_Cx1_HDF_Taste_am_Funkschluessel_betaetigt)}, range raw 0..1, transfer-property=PENDING  # HDF Taste am Funkschluessel
          signal FFB_Panik_Taste_XIX_ZV_02_XIX_E3V_EVCANFD: start 35, 1 bit, little-endian, data-type-policy=OVERRIDE, i-signal-type=PRIMITIVE, init-value=0, base-type=BT_FFB_Panik_Taste, compu {0=Cx0_Taste_nicht_betaetigt (CM_FFB_Panik_Taste_Cx0_Taste_nicht_betaetigt), 1=Cx1_Panik_Taste_am_Funkschluessel_betaetigt (CM_FFB_Panik_Taste_Cx1_Panik_Taste_am_Funkschluessel_betaetigt)}, range raw 0..1, transfer-property=PENDING  # Panik Taste Funkschluessel
          signal FFB_Auf_Taste_XIX_ZV_02_XIX_E3V_EVCANFD: start 36, 1 bit, little-endian, data-type-policy=OVERRIDE, i-signal-type=PRIMITIVE, init-value=0, base-type=BT_FFB_Auf_Taste, compu {0=Cx0_Taste_nicht_betaetigt (CM_FFB_Auf_Taste_Cx0_Taste_nicht_betaetigt), 1=Cx1_Oeffnentaste_betaetigt (CM_FFB_Auf_Taste_Cx1_Oeffnentaste_betaetigt)}, range raw 0..1, transfer-property=PENDING  # Auf-Taste Funkschluessel
          signal FFB_Zu_Taste_XIX_ZV_02_XIX_E3V_EVCANFD: start 37, 1 bit, little-endian, data-type-policy=OVERRIDE, i-signal-type=PRIMITIVE, init-value=0, base-type=BT_FFB_Zu_Taste, compu {0=Cx0_Taste_nicht_betaetigt (CM_FFB_Zu_Taste_Cx0_Taste_nicht_betaetigt), 1=Cx1_Zu_Taste_am_Funkschluessel_betaetigt (CM_FFB_Zu_Taste_Cx1_Zu_Taste_am_Funkschluessel_betaetigt)}, range raw 0..1, transfer-property=PENDING  # Zu-Taste Funkschluessel
          signal FFB_CarFinder_XIX_ZV_02_XIX_E3V_EVCANFD: start 38, 1 bit, little-endian, data-type-policy=OVERRIDE, i-signal-type=PRIMITIVE, init-value=0, base-type=BT_FFB_CarFinder, compu {0=Cx0_nicht_aktiv (CM_FFB_CarFinder_Cx0_nicht_aktiv) (nicht aktiv), 1=Cx1_aktiv (CM_FFB_CarFinder_Cx1_aktiv)}, range raw 0..1, transfer-property=PENDING  # Car Finder Funktion (Blinken ohne zu entriegeln)
          signal FFB_Komfortoeffnen_XIX_ZV_02_XIX_E3V_EVCANFD: start 39, 1 bit, little-endian, data-type-policy=OVERRIDE, i-signal-type=PRIMITIVE, init-value=0, base-type=BT_FFB_Komfortoeffnen, compu {0=Cx0_kein_Komfortoeffnen_empfangen (CM_FFB_Komfortoeffnen_Cx0_kein_Komfortoeffnen_empfangen), 1=Cx1_Komfortoeffnen_ueber_Funk_empfangen (CM_FFB_Komfortoeffnen_Cx1_Komfortoeffnen_ueber_Funk_empfangen) (Komfortoeffnen ueber Funk empfangen)}, range raw 0..1, transfer-property=PENDING  # Komfortoeffnen Funk
          signal FFB_Komfortschliessen_XIX_ZV_02_XIX_E3V_EVCANFD: start 40, 1 bit, little-endian, data-type-policy=OVERRIDE, i-signal-type=PRIMITIVE, init-value=0, base-type=BT_FFB_Komfortschliessen, compu {0=Cx0_kein_Komfortschliessen_empfangen (CM_FFB_Komfortschliessen_Cx0_kein_Komfortschliessen_empfangen), 1=Cx1_Komfortschliessen_ueber_Funk_empfangen (CM_FFB_Komfortschliessen_Cx1_Komfortschliessen_ueber_Funk_empfangen) (Komfortschliessen ueber Funk empfangen)}, range raw 0..1, transfer-property=PENDING  # Komfortschliessen Funk
          signal FBS_IDG_in_Reichweite_XIX_ZV_02_XIX_E3V_EVCANFD: start 41, 1 bit, little-endian, data-type-policy=OVERRIDE, i-signal-type=PRIMITIVE, init-value=0, base-type=BT_FBS_IDG_in_Reichweite, compu {0=Cx0_ausser_Reichweite_bzw_nicht_ermittelbar (CM_FBS_IDG_in_Reichweite_Cx0_ausser_Reichweite_bzw_nicht_ermittelbar), 1=Cx1_innerhalb_Reichweite (CM_FBS_IDG_in_Reichweite_Cx1_innerhalb_Reichweite)}, range raw 0..1, transfer-property=PENDING  # Für elektrisch betätigte Türen und Klappen muss für eine Betätigung über Funk eine Reichweitenbegrenzung eingeführt werden. Diese Bit zeigt an, dass sich der Funkschlüssel innerhalb der geforderten Reichweite befindet
          signal ZV_Schluessel_Zugang_XIX_ZV_02_XIX_E3V_EVCANFD: start 42, 4 bit, little-endian, data-type-policy=OVERRIDE, i-signal-type=PRIMITIVE, init-value=0, base-type=BT_ZV_Schluessel_Zugang, compu {0=Cx0_kein_auth_Schluessel_erkannt (CM_ZV_Schluessel_Zugang_Cx0_kein_auth_Schluessel_erkannt), 1=Cx1_aktive_Funkschluessel_Nr_01 (CM_ZV_Schluessel_Zugang_Cx1_aktive_Funkschluessel_Nr_01), 2=Cx2_aktive_Funkschluessel_Nr_02 (CM_ZV_Schluessel_Zugang_Cx2_aktive_Funkschluessel_Nr_02), 3=Cx3_aktive_Funkschluessel_Nr_03 (CM_ZV_Schluessel_Zugang_Cx3_aktive_Funkschluessel_Nr_03), 4=Cx4_aktive_Funkschluessel_Nr_04 (CM_ZV_Schluessel_Zugang_Cx4_aktive_Funkschluessel_Nr_04), 5=Cx5_aktive_Funkschluessel_Nr_05 (CM_ZV_Schluessel_Zugang_Cx5_aktive_Funkschluessel_Nr_05), 6=Cx6_aktive_Funkschluessel_Nr_06 (CM_ZV_Schluessel_Zugang_Cx6_aktive_Funkschluessel_Nr_06), 7=Cx7_aktive_Funkschluessel_Nr_07 (CM_ZV_Schluessel_Zugang_Cx7_aktive_Funkschluessel_Nr_07), 8=Cx8_aktive_Funkschluessel_Nr_08 (CM_ZV_Schluessel_Zugang_Cx8_aktive_Funkschluessel_Nr_08), 9=Cx9_aktive_SmartDevice_Nr_09 (CM_ZV_Schluessel_Zugang_Cx9_aktive_SmartDevice_Nr_09), 10=Cxa_ungueltig_10 (CM_ZV_Schluessel_Zugang_Cxa_ungueltig_10), 11=Cxb_ungueltig_11 (CM_ZV_Schluessel_Zugang_Cxb_ungueltig_11), 12=Cxc_ungueltig_12 (CM_ZV_Schluessel_Zugang_Cxc_ungueltig_12), 13=Cxd_ungueltig_13 (CM_ZV_Schluessel_Zugang_Cxd_ungueltig_13), 14=Cxe_ungueltig_14 (CM_ZV_Schluessel_Zugang_Cxe_ungueltig_14), 15=Cxf_ungueltig_15 (CM_ZV_Schluessel_Zugang_Cxf_ungueltig_15)}, range raw 0..15, transfer-property=TRIGGERED-ON-CHANGE-WITHOUT-REPETITION, to Klima(timeout 2 s)  # aktuelle Funkschlüsselnummer
          signal ZV_SafeFunktion_aktiv_XIX_ZV_02_XIX_E3V_EVCANFD: start 46, 1 bit, little-endian, data-type-policy=OVERRIDE, i-signal-type=PRIMITIVE, init-value=0, base-type=BT_ZV_SafeFunktion_aktiv, compu {0=Cx0_inaktiv (CM_ZV_SafeFunktion_aktiv_Cx0_inaktiv), 1=Cx1_aktiv (CM_ZV_SafeFunktion_aktiv_Cx1_aktiv)}, range raw 0..1, transfer-property=TRIGGERED-ON-CHANGE-WITHOUT-REPETITION  # Statusübermittlung ob die Safe Funktion im Fzg. aktiv ist. Das Kombi benötigt das Signal, um den Text Safelock aktiv anzuzeigen.
          signal FBS_Warn_Schluessel_Batt_XIX_ZV_02_XIX_E3V_EVCANFD: start 47, 1 bit, little-endian, data-type-policy=OVERRIDE, i-signal-type=PRIMITIVE, init-value=0, base-type=BT_FBS_Warn_Schluessel_Batt, compu {0=Cx0_i_O (CM_FBS_Warn_Schluessel_Batt_Cx0_i_O) (i.O.), 1=Cx1_defekt (CM_FBS_Warn_Schluessel_Batt_Cx1_defekt)}, range raw 0..1, transfer-property=TRIGGERED-ON-CHANGE-WITHOUT-REPETITION  # Kombi Prio Warnung Schluessel Batterie "Bitte Schlüsselbatterie wechseln!"
          signal ZV_Oeffnungsmodus_XIX_ZV_02_XIX_E3V_EVCANFD: start 48, 2 bit, little-endian, data-type-policy=OVERRIDE, i-signal-type=PRIMITIVE, init-value=0, base-type=BT_ZV_Oeffnungsmodus, compu {0=Cx0_globale_Oeffnung (CM_ZV_Oeffnungsmodus_Cx0_globale_Oeffnung), 1=Cx1_ZV_mit_Einzeltuerentr (CM_ZV_Oeffnungsmodus_Cx1_ZV_mit_Einzeltuerentr), 2=Cx2_ZV_individuell_selektiv (CM_ZV_Oeffnungsmodus_Cx2_ZV_individuell_selektiv), 3=Cx3_ZV_seitenselektiv (CM_ZV_Oeffnungsmodus_Cx3_ZV_seitenselektiv)}, range raw 0..3, transfer-property=TRIGGERED-ON-CHANGE-WITHOUT-REPETITION  # Konfigurierter Oeffnungsmodus fuer ZV: 0 = globale Oeffnung (alle Tueren) 1 = ZV mit Einzeltuerentriegelung (FFB - nur Fahrertuer, Kessy - nur bediente Tuer) 2 = ZV individuell selektive Oeffnung (FFB - Fahrerseite, Kessy - bediente Tuer + Fahrertuer) 3 = ZV seitenselektive Oeffnung
          signal ZV_ist_Zustand_verfuegbar_XIX_ZV_02_XIX_E3V_EVCANFD: start 54, 1 bit, little-endian, data-type-policy=OVERRIDE, i-signal-type=PRIMITIVE, init-value=0, base-type=BT_ZV_ist_Zustand_verfuegbar, compu {0=Cx0_nicht_verfuegbar (CM_ZV_ist_Zustand_verfuegbar_Cx0_nicht_verfuegbar), 1=Cx1_verfuegbar_alle_TSGs_am_Bus (CM_ZV_ist_Zustand_verfuegbar_Cx1_verfuegbar_alle_TSGs_am_Bus)}, range raw 0..1, transfer-property=TRIGGERED-ON-CHANGE-WITHOUT-REPETITION  # Verfügbarkeit IST-Zustand ZV
          signal IRUE_Taster_Fkts_LED_XIX_ZV_02_XIX_E3V_EVCANFD: start 55, 1 bit, little-endian, data-type-policy=OVERRIDE, i-signal-type=PRIMITIVE, init-value=0, base-type=BT_IRUE_Taster_Fkts_LED, compu {0=Cx0_LED_aus (CM_IRUE_Taster_Fkts_LED_Cx0_LED_aus), 1=Cx1_LED_ein (CM_IRUE_Taster_Fkts_LED_Cx1_LED_ein)}, range raw 0..1, transfer-property=TRIGGERED-ON-CHANGE-WITHOUT-REPETITION  # Anforderung Funktions-LED IRUE-Taster (LED wird vom TSG angesteuert) MQB: Bei Verbau eines einzelnen Taster zur Deaktivierung von IRUE und NGS wird dieses Signal zur Ansteuerung der Funktions-LED gesendet.
          signal ZV_Tankklappe_offen_XIX_ZV_02_XIX_E3V_EVCANFD: start 56, 1 bit, little-endian, data-type-policy=OVERRIDE, i-signal-type=PRIMITIVE, init-value=0, base-type=BT_ZV_Tankklappe_offen, compu {0=Cx0_Tankklappe_geschlossen (CM_ZV_Tankklappe_offen_Cx0_Tankklappe_geschlossen), 1=Cx1_Tankklappe_offen (CM_ZV_Tankklappe_offen_Cx1_Tankklappe_offen)}, range raw 0..1, transfer-property=PENDING  # Öffnungsstatus der Tankklappe
          signal ZV_Rollo_auf_XIX_ZV_02_XIX_E3V_EVCANFD: start 57, 1 bit, little-endian, data-type-policy=OVERRIDE, i-signal-type=PRIMITIVE, init-value=0, base-type=BT_ZV_Rollo_auf, compu {0=Cx0_inaktiv (CM_ZV_Rollo_auf_Cx0_inaktiv), 1=Cx1_aktiv (CM_ZV_Rollo_auf_Cx1_aktiv)}, range raw 0..1, transfer-property=TRIGGERED-ON-CHANGE-WITHOUT-REPETITION  # Komfortöffnen des Dachrollos
          signal ZV_Rollo_zu_XIX_ZV_02_XIX_E3V_EVCANFD: start 58, 1 bit, little-endian, data-type-policy=OVERRIDE, i-signal-type=PRIMITIVE, init-value=0, base-type=BT_ZV_Rollo_zu, compu {0=Cx0_inaktiv (CM_ZV_Rollo_zu_Cx0_inaktiv), 1=Cx1_aktiv (CM_ZV_Rollo_zu_Cx1_aktiv)}, range raw 0..1, transfer-property=TRIGGERED-ON-CHANGE-WITHOUT-REPETITION  # Komfortschließen des Dachrollos
          signal ZV_SAD_auf_XIX_ZV_02_XIX_E3V_EVCANFD: start 59, 1 bit, little-endian, data-type-policy=OVERRIDE, i-signal-type=PRIMITIVE, init-value=0, base-type=BT_ZV_SAD_auf, compu {0=Cx0_inaktiv (CM_ZV_SAD_auf_Cx0_inaktiv), 1=Cx1_aktiv (CM_ZV_SAD_auf_Cx1_aktiv)}, range raw 0..1, transfer-property=TRIGGERED-ON-CHANGE-WITHOUT-REPETITION  # Komfortöffnen des Schiebeausstelldaches
          signal ZV_SAD_zu_XIX_ZV_02_XIX_E3V_EVCANFD: start 60, 1 bit, little-endian, data-type-policy=OVERRIDE, i-signal-type=PRIMITIVE, init-value=0, base-type=BT_ZV_SAD_zu, compu {0=Cx0_inaktiv (CM_ZV_SAD_zu_Cx0_inaktiv), 1=Cx1_aktiv (CM_ZV_SAD_zu_Cx1_aktiv)}, range raw 0..1, transfer-property=TRIGGERED-ON-CHANGE-WITHOUT-REPETITION  # Komfortschließen des Schiebeausstelldaches
          signal ZV_verriegelt_soll_XIX_ZV_02_XIX_E3V_EVCANFD: start 62, 2 bit, little-endian, data-type-policy=OVERRIDE, i-signal-type=PRIMITIVE, init-value=0, base-type=BT_ZV_verriegelt_soll, compu {0=Cx0_Init (CM_ZV_verriegelt_soll_Cx0_Init), 1=Cx1_nicht_verriegelt (CM_ZV_verriegelt_soll_Cx1_nicht_verriegelt), 2=Cx2_verriegelt (CM_ZV_verriegelt_soll_Cx2_verriegelt)}, range raw 0..2, transfer-property=TRIGGERED-ON-CHANGE-WITHOUT-REPETITION  # Fahrzeug Gesamtverriegelungsstatus Sollzustand für Ladestecker- und Ladeklappenverriegelung.
      pdu triggering PT_E3V_EVCANFD_XIX_TPCHType_CANFD_ISO_Diagnose_XIX_0x1C400046_XIX_0x1C420046_XIX_Physical: pdu=DCM_E3V_EVCANFD_XIX_TPCHType_CANFD_ISO_Diagnose_XIX_0x1C400046_XIX_0x1C420046_XIX_Physical, to Klima
      pdu triggering PT_E3V_EVCANFD_XIX_TPCHType_CANFD_ISO_Diagnose_XIX_0x1C410000_XIX_Functional: pdu=DCM_E3V_EVCANFD_XIX_TPCHType_CANFD_ISO_Diagnose_XIX_0x1C410000_XIX_Functional, to Klima
      pdu triggering PT_E3V_EVCANFD_XIX_TPCHType_CANFD_ISO_Diagnose_XIX_0x1C420046_XIX_0x1C400046_XIX_Physical: pdu=DCM_E3V_EVCANFD_XIX_TPCHType_CANFD_ISO_Diagnose_XIX_0x1C420046_XIX_0x1C400046_XIX_Physical, from Klima
      pdu triggering PT_E3V_EVCANFD_XIX_TPCHType_CANFD_OBDC_Diagnose_XIX_0x1C400246_XIX_0x1C420246_XIX_Physical: pdu=DCM_E3V_EVCANFD_XIX_TPCHType_CANFD_OBDC_Diagnose_XIX_0x1C400246_XIX_0x1C420246_XIX_Physical, to Klima
      pdu triggering PT_E3V_EVCANFD_XIX_TPCHType_CANFD_OBDC_Diagnose_XIX_0x1C410200_XIX_Functional: pdu=DCM_E3V_EVCANFD_XIX_TPCHType_CANFD_OBDC_Diagnose_XIX_0x1C410200_XIX_Functional, to Klima
      pdu triggering PT_E3V_EVCANFD_XIX_TPCHType_CANFD_OBDC_Diagnose_XIX_0x1C420246_XIX_0x1C400246_XIX_Physical: pdu=DCM_E3V_EVCANFD_XIX_TPCHType_CANFD_OBDC_Diagnose_XIX_0x1C420246_XIX_0x1C400246_XIX_Physical, from Klima
      pdu triggering PT_E3V_EVCANFD_XIX_TPCHType_CANHS_FoD_Master_XIX_0x17FC0346_XIX_0x17FE0346_XIX_Physical: pdu=CDD_E3V_EVCANFD_XIX_TPCHType_CANHS_FoD_Master_XIX_0x17FC0346_XIX_0x17FE0346_XIX_Physical, to Klima
      pdu triggering PT_E3V_EVCANFD_XIX_TPCHType_CANHS_FoD_Master_XIX_0x17FE0346_XIX_0x17FC0346_XIX_Physical: pdu=CDD_E3V_EVCANFD_XIX_TPCHType_CANHS_FoD_Master_XIX_0x17FE0346_XIX_0x17FC0346_XIX_Physical, from Klima
      pdu triggering PT_E3V_EVCANFD_XIX_TPCHType_CANHS_ISO_Diagnose_XIX_0x700_XIX_Functional: pdu=DCM_E3V_EVCANFD_XIX_TPCHType_CANHS_ISO_Diagnose_XIX_0x700_XIX_Functional, to Klima
      pdu triggering PT_E3V_EVCANFD_XIX_TPCHType_CANHS_ISO_Diagnose_XIX_0x746_XIX_0x7B0_XIX_Physical: pdu=DCM_E3V_EVCANFD_XIX_TPCHType_CANHS_ISO_Diagnose_XIX_0x746_XIX_0x7B0_XIX_Physical, to Klima
      pdu triggering PT_E3V_EVCANFD_XIX_TPCHType_CANHS_ISO_Diagnose_XIX_0x7B0_XIX_0x746_XIX_Physical: pdu=DCM_E3V_EVCANFD_XIX_TPCHType_CANHS_ISO_Diagnose_XIX_0x7B0_XIX_0x746_XIX_Physical, from Klima
      pdu triggering PT_E3V_EVCANFD_XIX_TPCHType_CANHS_OBDx_XIX_0x18DA0AF1_XIX_0x18DAF10A_XIX_Physical: pdu=DCM_E3V_EVCANFD_XIX_TPCHType_CANHS_OBDx_XIX_0x18DA0AF1_XIX_0x18DAF10A_XIX_Physical, to Klima
      pdu triggering PT_E3V_EVCANFD_XIX_TPCHType_CANHS_OBDx_XIX_0x18DAF10A_XIX_0x18DA0AF1_XIX_Physical: pdu=DCM_E3V_EVCANFD_XIX_TPCHType_CANHS_OBDx_XIX_0x18DAF10A_XIX_0x18DA0AF1_XIX_Physical, from Klima
      pdu triggering PT_E3V_EVCANFD_XIX_TPCHType_CANHS_OBDx_XIX_0x18DB33F1_XIX_Functional: pdu=DCM_E3V_EVCANFD_XIX_TPCHType_CANHS_OBDx_XIX_0x18DB33F1_XIX_Functional, to Klima
      pdu triggering PT_Klima_EV_10: pdu=Klima_EV_10_XIX_E3V_EVCANFD, from Klima
      pdu triggering PT_Motor_26_Mx00: pdu=Motor_26_Mx00_XIX_E3V_EVCANFD, to Klima
      pdu triggering PT_Motor_26_Mx01: pdu=Motor_26_Mx01_XIX_E3V_EVCANFD, to Klima
      pdu triggering PT_Motor_26_MxStatic: pdu=Motor_26_MxStatic_XIX_E3V_EVCANFD, to Klima
      pdu triggering PT_PSD_06_Mx{00..04}: pdu=PSD_06_Mx{00..04}_XIX_E3V_EVCANFD, to Klima
      pdu triggering PT_PSD_LR_01_Mx{00..03}: pdu=PSD_LR_01_Mx{00..03}_XIX_E3V_EVCANFD, to Klima
      pdu triggering PT_PSD_LR_01_MxStatic: pdu=PSD_LR_01_MxStatic_XIX_E3V_EVCANFD, to Klima
      pdu triggering PT_SOK_E3V_EVCANFD_XIX_TPCHType_CANHS_FoD_Master_XIX_0x17FC0346_XIX_0x17FE0346_XIX_Physical: pdu=SOK_E3V_EVCANFD_XIX_TPCHType_CANHS_FoD_Master_XIX_0x17FC0346_XIX_0x17FE0346_XIX_Physical, to Klima
      pdu triggering PT_SOK_E3V_EVCANFD_XIX_TPCHType_CANHS_FoD_Master_XIX_0x17FE0346_XIX_0x17FC0346_XIX_Physical: pdu=SOK_E3V_EVCANFD_XIX_TPCHType_CANHS_FoD_Master_XIX_0x17FE0346_XIX_0x17FC0346_XIX_Physical, from Klima
      pdu triggering PT_VIN_01_Mx{00..02}: pdu=VIN_01_Mx{00..02}_XIX_E3V_EVCANFD, to Klima
  7 x lin cluster, all with baudrate=19200, protocol-name=LIN, protocol-version=2.0:
    Klima_LIN2
      lin physical channel CHNL: comm-connectors=CN_Klima_LIN2
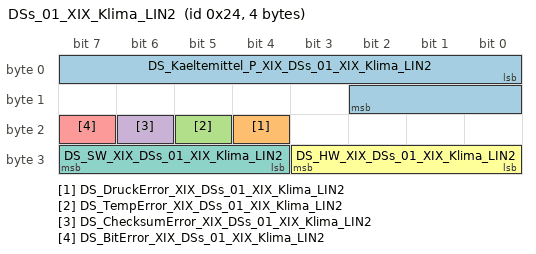
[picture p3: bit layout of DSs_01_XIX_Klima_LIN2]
        frame DSs_01_XIX_Klima_LIN2: id 0x24, to Klima, frame-length=4, lin-checksum=CLASSIC
          pdu DSs_01_XIX_Klima_LIN2: length=4, unused-bit-pattern=0
            signal DS_Kaeltemittel_P_XIX_DSs_01_XIX_Klima_LIN2: start 0, 11 bit, little-endian, data-type-policy=OVERRIDE, i-signal-type=PRIMITIVE, init-value=2046, base-type=BT_DS_Kaeltemittel_P, invalid-value=Invalid_DS_Kaeltemittel_P_XIX_DSs_01_XIX_Klima_LIN2:2047, compu {phys=raw*0.0161 for raw 0..2045, 2046=Cx7fe_Init (CM_DS_Kaeltemittel_P_Cx7fe_Init), 2047=Cx7ff_Fehler (CM_DS_Kaeltemittel_P_Cx7ff_Fehler); unit Unit_Bar}, range phys 0..32.9245 Unit_Bar, raw 0..2047, unit=Unit_Bar, transfer-property=PENDING, to Klima(timeout 3.5 s)  # Drucksensor Kältemittel Druck, das Signal wird bei Kl.15 AUS mit dem letzten empfangenen Wert gesendet
            signal DS_DruckError_XIX_DSs_01_XIX_Klima_LIN2: start 20, 1 bit, little-endian, data-type-policy=OVERRIDE, i-signal-type=PRIMITIVE, init-value=0, base-type=BT_DS_DruckError, invalid-value=Invalid_DS_DruckError_XIX_DSs_01_XIX_Klima_LIN2:1, compu {0=Cx0_normal (CM_DS_DruckError_Cx0_normal), 1=Cx1_Fehler (CM_DS_DruckError_Cx1_Fehler)}, range raw 0..1, transfer-property=PENDING, to Klima(timeout 3.5 s)
            signal DS_TempError_XIX_DSs_01_XIX_Klima_LIN2: start 21, 1 bit, little-endian, data-type-policy=OVERRIDE, i-signal-type=PRIMITIVE, init-value=0, base-type=BT_DS_TempError, invalid-value=Invalid_DS_TempError_XIX_DSs_01_XIX_Klima_LIN2:1, compu {0=Cx0_normal (CM_DS_TempError_Cx0_normal), 1=Cx1_Fehler (CM_DS_TempError_Cx1_Fehler)}, range raw 0..1, transfer-property=PENDING, to Klima(timeout 3.5 s)  # Wird dieser LIN1.3-Slave auf LIN2.0 umgestellt, so ist dieses Bit als ResponseError zu verwenden!
            signal DS_ChecksumError_XIX_DSs_01_XIX_Klima_LIN2: start 22, 1 bit, little-endian, data-type-policy=OVERRIDE, i-signal-type=PRIMITIVE, init-value=0, base-type=BT_DS_ChecksumError, invalid-value=Invalid_DS_ChecksumError_XIX_DSs_01_XIX_Klima_LIN2:1, compu {0=Cx0_normal (CM_DS_ChecksumError_Cx0_normal), 1=Cx1_Fehler (CM_DS_ChecksumError_Cx1_Fehler)}, range raw 0..1, transfer-property=PENDING, to Klima(timeout 3.5 s)
            signal DS_BitError_XIX_DSs_01_XIX_Klima_LIN2: start 23, 1 bit, little-endian, data-type-policy=OVERRIDE, i-signal-type=PRIMITIVE, init-value=0, base-type=BT_DS_BitError, invalid-value=Invalid_DS_BitError_XIX_DSs_01_XIX_Klima_LIN2:1, compu {0=Cx0_normal (CM_DS_BitError_Cx0_normal), 1=Cx1_Fehler (CM_DS_BitError_Cx1_Fehler)}, range raw 0..1, transfer-property=PENDING, to Klima(timeout 3.5 s)
            signal DS_HW_XIX_DSs_01_XIX_Klima_LIN2: start 24, 4 bit, little-endian, data-type-policy=OVERRIDE, i-signal-type=PRIMITIVE, init-value=0, base-type=BT_DS_HW, compu {phys=raw for raw 0..15}, range phys 0..15, raw 0..15, transfer-property=PENDING, to Klima(timeout 3.5 s)  # Drucksensor Hardware Version
            signal DS_SW_XIX_DSs_01_XIX_Klima_LIN2: start 28, 4 bit, little-endian, data-type-policy=OVERRIDE, i-signal-type=PRIMITIVE, init-value=0, base-type=BT_DS_SW, compu {phys=raw for raw 0..15}, range phys 0..15, raw 0..15, transfer-property=PENDING, to Klima(timeout 3.5 s)  # Drucksensor Sortware Version
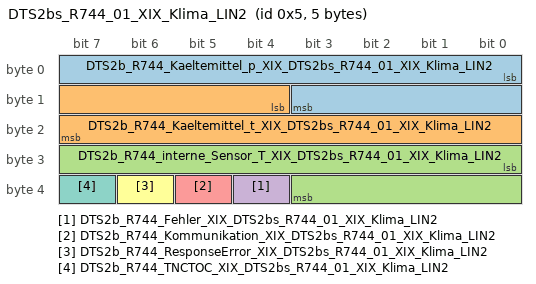
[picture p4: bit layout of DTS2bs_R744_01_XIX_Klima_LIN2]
        frame DTS2bs_R744_01_XIX_Klima_LIN2: id 0x5, to Klima, frame-length=5, lin-checksum=ENHANCED
          pdu DTS2bs_R744_01_XIX_Klima_LIN2: length=5, unused-bit-pattern=0
            signal DTS2b_R744_Kaeltemittel_p_XIX_DTS2bs_R744_01_XIX_Klima_LIN2: start 0, 12 bit, little-endian, data-type-policy=OVERRIDE, i-signal-type=PRIMITIVE, init-value=4094, base-type=BT_DTS2b_R744_Kaeltemittel_p, invalid-value=Invalid_DTS2b_R744_Kaeltemittel_p_XIX_DTS2bs_R744_01_XIX_Klima_LIN2:4095, compu {phys=raw*0.05000000075 for raw 0..3400, 4094=Cxffe_Init (CM_DTS2b_R744_Kaeltemittel_p_Cxffe_Init), 4095=Cxfff_Fehler (CM_DTS2b_R744_Kaeltemittel_p_Cxfff_Fehler); unit Unit_Bar}, range phys 0..170.0000025331974 Unit_Bar, raw 0..4095, unit=Unit_Bar, transfer-property=PENDING, to Klima(timeout 3.5 s)  # Kaeltemitteldruck absolut
            signal DTS2b_R744_Kaeltemittel_t_XIX_DTS2bs_R744_01_XIX_Klima_LIN2: start 12, 12 bit, little-endian, data-type-policy=OVERRIDE, i-signal-type=PRIMITIVE, init-value=4094, base-type=BT_DTS2b_R744_Kaeltemittel_t, invalid-value=Invalid_DTS2b_R744_Kaeltemittel_t_XIX_DTS2bs_R744_01_XIX_Klima_LIN2:4095, compu {phys=raw*0.1000000015-40 for raw 0..2200, 4094=Cxffe_Init (CM_DTS2b_R744_Kaeltemittel_t_Cxffe_Init), 4095=Cxfff_Fehler (CM_DTS2b_R744_Kaeltemittel_t_Cxfff_Fehler); unit Unit_DegreCelsi}, range phys -40..180.00000327825546 Unit_DegreCelsi, raw 0..4095, unit=Unit_DegreCelsi, transfer-property=PENDING, to Klima(timeout 3.5 s)  # Kältemitteltemperatur
            signal DTS2b_R744_interne_Sensor_T_XIX_DTS2bs_R744_01_XIX_Klima_LIN2: start 24, 12 bit, little-endian, data-type-policy=OVERRIDE, i-signal-type=PRIMITIVE, init-value=4094, base-type=BT_DTS2b_R744_interne_Sensor_T, invalid-value=Invalid_DTS2b_R744_interne_Sensor_T_XIX_DTS2bs_R744_01_XIX_Klima_LIN2:4095, compu {phys=raw*0.1000000015-40 for raw 0..1800, 4094=Cxffe_Init (CM_DTS2b_R744_interne_Sensor_T_Cxffe_Init), 4095=Cxfff_Fehler (CM_DTS2b_R744_interne_Sensor_T_Cxfff_Fehler); unit Unit_DegreCelsi}, range phys -40..140.00000268220901 Unit_DegreCelsi, raw 0..4095, unit=Unit_DegreCelsi, transfer-property=PENDING, to Klima(timeout 3.5 s)  # interne Sensor-Temperatur
            signal DTS2b_R744_Fehler_XIX_DTS2bs_R744_01_XIX_Klima_LIN2: start 36, 1 bit, little-endian, data-type-policy=OVERRIDE, i-signal-type=PRIMITIVE, init-value=0, base-type=BT_DTS2b_R744_Fehler, invalid-value=Invalid_DTS2b_R744_Fehler_XIX_DTS2bs_R744_01_XIX_Klima_LIN2:1, compu {0=Cx0_kein_Fehler (CM_DTS2b_R744_Fehler_Cx0_kein_Fehler), 1=Cx1_Fehler (CM_DTS2b_R744_Fehler_Cx1_Fehler)}, range raw 0..1, transfer-property=PENDING, to Klima(timeout 3.5 s)  # Interner Sensorfehler
            signal DTS2b_R744_Kommunikation_XIX_DTS2bs_R744_01_XIX_Klima_LIN2: start 37, 1 bit, little-endian, data-type-policy=OVERRIDE, i-signal-type=PRIMITIVE, init-value=0, base-type=BT_DTS2b_R744_Kommunikation, invalid-value=Invalid_DTS2b_R744_Kommunikation_XIX_DTS2bs_R744_01_XIX_Klima_LIN2:1, compu {0=Cx0_kein_Fehler (CM_DTS2b_R744_Kommunikation_Cx0_kein_Fehler), 1=Cx1_Fehler (CM_DTS2b_R744_Kommunikation_Cx1_Fehler)}, range raw 0..1, transfer-property=PENDING, to Klima(timeout 3.5 s)  # Checksummenfehler
            signal DTS2b_R744_ResponseError_XIX_DTS2bs_R744_01_XIX_Klima_LIN2: start 38, 1 bit, little-endian, data-type-policy=OVERRIDE, i-signal-type=PRIMITIVE, init-value=0, base-type=BT_DTS2b_R744_ResponseError, invalid-value=Invalid_DTS2b_R744_ResponseError_XIX_DTS2bs_R744_01_XIX_Klima_LIN2:1, compu {0=Cx0_normal (CM_DTS2b_R744_ResponseError_Cx0_normal), 1=Cx1_Fehler (CM_DTS2b_R744_ResponseError_Cx1_Fehler)}, range raw 0..1, transfer-property=PENDING, to Klima(timeout 3.5 s)  # siehe LIN2.0-Specification (Darf nicht über ein Fehlergueltigkeitsbit abgesichtert werden!)
            signal DTS2b_R744_TNCTOC_XIX_DTS2bs_R744_01_XIX_Klima_LIN2: start 39, 1 bit, little-endian, data-type-policy=OVERRIDE, i-signal-type=PRIMITIVE, init-value=1, base-type=BT_DTS2b_R744_TNCTOC, compu {0=Cx0_DTC_test_completed_this_operation_cylce (CM_DTS2b_R744_TNCTOC_Cx0_DTC_test_completed_this_operation_cylce), 1=Cx1_DTC_test_not_completed_this_operation_cylce (CM_DTS2b_R744_TNCTOC_Cx1_DTC_test_not_completed_this_operation_cylce)}, range raw 0..1, transfer-property=PENDING, to Klima(timeout 3.5 s)  # testNotCompletedThisOperationCycle (TNCTOC)
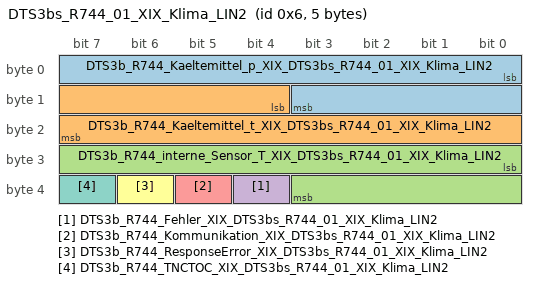
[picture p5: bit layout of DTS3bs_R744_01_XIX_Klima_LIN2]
        frame DTS3bs_R744_01_XIX_Klima_LIN2: id 0x6, to Klima, frame-length=5, lin-checksum=ENHANCED
          pdu DTS3bs_R744_01_XIX_Klima_LIN2: length=5, unused-bit-pattern=0
            signal DTS3b_R744_Kaeltemittel_p_XIX_DTS3bs_R744_01_XIX_Klima_LIN2: start 0, 12 bit, little-endian, data-type-policy=OVERRIDE, i-signal-type=PRIMITIVE, init-value=4094, base-type=BT_DTS3b_R744_Kaeltemittel_p, invalid-value=Invalid_DTS3b_R744_Kaeltemittel_p_XIX_DTS3bs_R744_01_XIX_Klima_LIN2:4095, compu {phys=raw*0.05000000075 for raw 0..3400, 4094=Cxffe_Init (CM_DTS3b_R744_Kaeltemittel_p_Cxffe_Init), 4095=Cxfff_Fehler (CM_DTS3b_R744_Kaeltemittel_p_Cxfff_Fehler); unit Unit_Bar}, range phys 0..170.0000025331974 Unit_Bar, raw 0..4095, unit=Unit_Bar, transfer-property=PENDING, to Klima(timeout 3.5 s)  # Kaeltemitteldruck absolut
            signal DTS3b_R744_Kaeltemittel_t_XIX_DTS3bs_R744_01_XIX_Klima_LIN2: start 12, 12 bit, little-endian, data-type-policy=OVERRIDE, i-signal-type=PRIMITIVE, init-value=4094, base-type=BT_DTS3b_R744_Kaeltemittel_t, invalid-value=Invalid_DTS3b_R744_Kaeltemittel_t_XIX_DTS3bs_R744_01_XIX_Klima_LIN2:4095, compu {phys=raw*0.1000000015-40 for raw 0..2200, 4094=Cxffe_Init (CM_DTS3b_R744_Kaeltemittel_t_Cxffe_Init), 4095=Cxfff_Fehler (CM_DTS3b_R744_Kaeltemittel_t_Cxfff_Fehler); unit Unit_DegreCelsi}, range phys -40..180.00000327825546 Unit_DegreCelsi, raw 0..4095, unit=Unit_DegreCelsi, transfer-property=PENDING, to Klima(timeout 3.5 s)  # Kältemitteltemperatur
            signal DTS3b_R744_interne_Sensor_T_XIX_DTS3bs_R744_01_XIX_Klima_LIN2: start 24, 12 bit, little-endian, data-type-policy=OVERRIDE, i-signal-type=PRIMITIVE, init-value=4094, base-type=BT_DTS3b_R744_interne_Sensor_T, invalid-value=Invalid_DTS3b_R744_interne_Sensor_T_XIX_DTS3bs_R744_01_XIX_Klima_LIN2:4095, compu {phys=raw*0.1000000015-40 for raw 0..1800, 4094=Cxffe_Init (CM_DTS3b_R744_interne_Sensor_T_Cxffe_Init), 4095=Cxfff_Fehler (CM_DTS3b_R744_interne_Sensor_T_Cxfff_Fehler); unit Unit_DegreCelsi}, range phys -40..140.00000268220901 Unit_DegreCelsi, raw 0..4095, unit=Unit_DegreCelsi, transfer-property=PENDING, to Klima(timeout 3.5 s)  # interne Sensor-Temperatur
            signal DTS3b_R744_Fehler_XIX_DTS3bs_R744_01_XIX_Klima_LIN2: start 36, 1 bit, little-endian, data-type-policy=OVERRIDE, i-signal-type=PRIMITIVE, init-value=0, base-type=BT_DTS3b_R744_Fehler, invalid-value=Invalid_DTS3b_R744_Fehler_XIX_DTS3bs_R744_01_XIX_Klima_LIN2:1, compu {0=Cx0_kein_Fehler (CM_DTS3b_R744_Fehler_Cx0_kein_Fehler), 1=Cx1_Fehler (CM_DTS3b_R744_Fehler_Cx1_Fehler)}, range raw 0..1, transfer-property=PENDING, to Klima(timeout 3.5 s)  # Interner Sensorfehler
            signal DTS3b_R744_Kommunikation_XIX_DTS3bs_R744_01_XIX_Klima_LIN2: start 37, 1 bit, little-endian, data-type-policy=OVERRIDE, i-signal-type=PRIMITIVE, init-value=0, base-type=BT_DTS3b_R744_Kommunikation, invalid-value=Invalid_DTS3b_R744_Kommunikation_XIX_DTS3bs_R744_01_XIX_Klima_LIN2:1, compu {0=Cx0_kein_Fehler (CM_DTS3b_R744_Kommunikation_Cx0_kein_Fehler), 1=Cx1_Fehler (CM_DTS3b_R744_Kommunikation_Cx1_Fehler)}, range raw 0..1, transfer-property=PENDING, to Klima(timeout 3.5 s)  # Checksummenfehler
            signal DTS3b_R744_ResponseError_XIX_DTS3bs_R744_01_XIX_Klima_LIN2: start 38, 1 bit, little-endian, data-type-policy=OVERRIDE, i-signal-type=PRIMITIVE, init-value=0, base-type=BT_DTS3b_R744_ResponseError, invalid-value=Invalid_DTS3b_R744_ResponseError_XIX_DTS3bs_R744_01_XIX_Klima_LIN2:1, compu {0=Cx0_normal (CM_DTS3b_R744_ResponseError_Cx0_normal), 1=Cx1_Fehler (CM_DTS3b_R744_ResponseError_Cx1_Fehler)}, range raw 0..1, transfer-property=PENDING, to Klima(timeout 3.5 s)  # siehe LIN2.0-Specification (Darf nicht über ein Fehlergueltigkeitsbit abgesichtert werden!)
            signal DTS3b_R744_TNCTOC_XIX_DTS3bs_R744_01_XIX_Klima_LIN2: start 39, 1 bit, little-endian, data-type-policy=OVERRIDE, i-signal-type=PRIMITIVE, init-value=1, base-type=BT_DTS3b_R744_TNCTOC, compu {0=Cx0_DTC_test_completed_this_operation_cylce (CM_DTS3b_R744_TNCTOC_Cx0_DTC_test_completed_this_operation_cylce), 1=Cx1_DTC_test_not_completed_this_operation_cylce (CM_DTS3b_R744_TNCTOC_Cx1_DTC_test_not_completed_this_operation_cylce)}, range raw 0..1, transfer-property=PENDING, to Klima(timeout 3.5 s)  # testNotCompletedThisOperationCycle (TNCTOC)
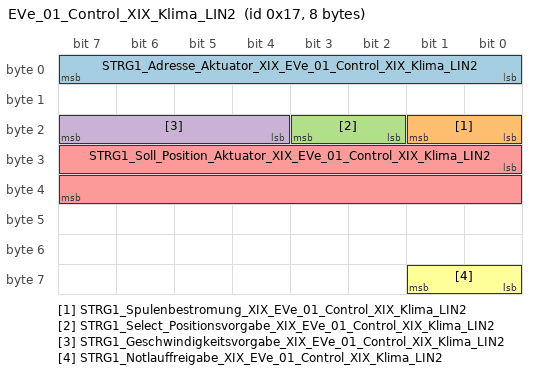
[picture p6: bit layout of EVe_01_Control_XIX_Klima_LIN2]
        frame EVe_01_Control_XIX_Klima_LIN2: id 0x17, from Klima, frame-length=8, lin-checksum=ENHANCED
          pdu EVe_01_Control_XIX_Klima_LIN2: length=8, unused-bit-pattern=0
            signal STRG1_Adresse_Aktuator_XIX_EVe_01_Control_XIX_Klima_LIN2: start 0, 8 bit, little-endian, data-type-policy=OVERRIDE, i-signal-type=PRIMITIVE, base-type=BT_STRG1_Adresse_Aktuator, invalid-value=Invalid_STRG1_Adresse_Aktuator_XIX_EVe_01_Control_XIX_Klima_LIN2:255, compu {phys=raw for raw 0..254, 127=Cx7f_Broadcast (CM_STRG1_Adresse_Aktuator_Cx7f_Broadcast), 255=Cxff_Fehler (CM_STRG1_Adresse_Aktuator_Cxff_Fehler); unit Unit_None}, range phys 0..254 Unit_None, raw 0..255, unit=Unit_None, transfer-property=PENDING  # Zielempfängerauswahl, Steuerungsbotschaft für Aktuatoren
            signal STRG1_Spulenbestromung_XIX_EVe_01_Control_XIX_Klima_LIN2: start 16, 2 bit, little-endian, data-type-policy=OVERRIDE, i-signal-type=PRIMITIVE, base-type=BT_STRG1_Spulenbestromung, invalid-value=Invalid_STRG1_Spulenbestromung_XIX_EVe_01_Control_XIX_Klima_LIN2:3, compu {0=Cx0_Motorspulen_unbestromt (CM_STRG1_Spulenbestromung_Cx0_Motorspulen_unbestromt), 1=Cx1_Motorspulen_bestromt (CM_STRG1_Spulenbestromung_Cx1_Motorspulen_bestromt), 2=Cx2_reserviert (CM_STRG1_Spulenbestromung_Cx2_reserviert), 3=Cx3_Fehler (CM_STRG1_Spulenbestromung_Cx3_Fehler)}, range raw 0..3, transfer-property=PENDING  # Spulenbestromungszustandsvorgabe, Steuerungsbotschaft für Aktuatoren
            signal STRG1_Select_Positionsvorgabe_XIX_EVe_01_Control_XIX_Klima_LIN2: start 18, 2 bit, little-endian, data-type-policy=OVERRIDE, i-signal-type=PRIMITIVE, init-value=2, base-type=BT_STRG1_Select_Positionsvorgabe, invalid-value=Invalid_STRG1_Select_Positionsvorgabe_XIX_EVe_01_Control_XIX_Klima_LIN2:3, compu {0=Cx0_Soll_Position_gueltig (CM_STRG1_Select_Positionsvorgabe_Cx0_Soll_Position_gueltig), 1=Cx1_Start_Position_gueltig (CM_STRG1_Select_Positionsvorgabe_Cx1_Start_Position_gueltig), 2=Cx2_keine_Positionsvorgabe_gueltig (CM_STRG1_Select_Positionsvorgabe_Cx2_keine_Positionsvorgabe_gueltig), 3=Cx3_Fehler (CM_STRG1_Select_Positionsvorgabe_Cx3_Fehler)}, range raw 0..3, transfer-property=PENDING  # Vorgabe der Gültigkeit der Positionsvorgaben, Steuerungsbotschaft für Aktuatoren
            signal STRG1_Geschwindigkeitsvorgabe_XIX_EVe_01_Control_XIX_Klima_LIN2: start 20, 4 bit, little-endian, data-type-policy=OVERRIDE, i-signal-type=PRIMITIVE, base-type=BT_STRG1_Geschwindigkeitsvorgabe, invalid-value=Invalid_STRG1_Geschwindigkeitsvorgabe_XIX_EVe_01_Control_XIX_Klima_LIN2:15, compu {0=Cx0_reserviert (CM_STRG1_Geschwindigkeitsvorgabe_Cx0_reserviert), 1=Cx1_Geschwindigkeitsstufe_1 (CM_STRG1_Geschwindigkeitsvorgabe_Cx1_Geschwindigkeitsstufe_1), 2=Cx2_Geschwindigkeitsstufe_2 (CM_STRG1_Geschwindigkeitsvorgabe_Cx2_Geschwindigkeitsstufe_2), 3=Cx3_Geschwindigkeitsstufe_3 (CM_STRG1_Geschwindigkeitsvorgabe_Cx3_Geschwindigkeitsstufe_3), 4=Cx4_Geschwindigkeitsstufe_4 (CM_STRG1_Geschwindigkeitsvorgabe_Cx4_Geschwindigkeitsstufe_4), 5=Cx5_Autospeed (CM_STRG1_Geschwindigkeitsvorgabe_Cx5_Autospeed), 15=Cxf_Fehler (CM_STRG1_Geschwindigkeitsvorgabe_Cxf_Fehler)}, range raw 0..15, transfer-property=PENDING  # Vorgabe der Geschwindigkeit, Steuerungsbotschaft für Aktuatoren
            signal STRG1_Soll_Position_Aktuator_XIX_EVe_01_Control_XIX_Klima_LIN2: start 24, 16 bit, little-endian, data-type-policy=OVERRIDE, i-signal-type=PRIMITIVE, base-type=BT_STRG1_Soll_Position_Aktuator, invalid-value=Invalid_STRG1_Soll_Position_Aktuator_XIX_EVe_01_Control_XIX_Klima_LIN2:65535, compu {phys=raw for raw 0..65534, 65535=Cxffff_Fehler (CM_STRG1_Soll_Position_Aktuator_Cxffff_Fehler); unit Unit_None}, range phys 0..65534 Unit_None, raw 0..65535, unit=Unit_None, transfer-property=PENDING  # Vorgabe der Sollposition, Steuerungsbotschaft für die Aktuatoren
            signal STRG1_Notlauffreigabe_XIX_EVe_01_Control_XIX_Klima_LIN2: start 56, 2 bit, little-endian, data-type-policy=OVERRIDE, i-signal-type=PRIMITIVE, base-type=BT_STRG1_Notlauffreigabe, invalid-value=Invalid_STRG1_Notlauffreigabe_XIX_EVe_01_Control_XIX_Klima_LIN2:3, compu {0=Cx0_Notlauf_aus (CM_STRG1_Notlauffreigabe_Cx0_Notlauf_aus), 1=Cx1_Notlauf_ein (CM_STRG1_Notlauffreigabe_Cx1_Notlauf_ein), 2=Cx2_reserviert (CM_STRG1_Notlauffreigabe_Cx2_reserviert), 3=Cx3_Fehler (CM_STRG1_Notlauffreigabe_Cx3_Fehler)}, range raw 0..3, transfer-property=PENDING  # Freigabe der Notlaufeigenschaft, Steuerungsbotschaft für Aktuatoren
        frame EXV1s_01_XIX_Klima_LIN2: id 0x18, to Klima, frame-length=8, lin-checksum=ENHANCED
          pdu EXV1s_01_XIX_Klima_LIN2: length=8, unused-bit-pattern=0
            signal EXV1_Ist_Position_Aktuator_XIX_EXV1s_01_XIX_Klima_LIN2: start 0, 16 bit, little-endian, data-type-policy=OVERRIDE, i-signal-type=PRIMITIVE, init-value=65534, base-type=BT_EXV1_Ist_Position_Aktuator, invalid-value=Invalid_EXV1_Ist_Position_Aktuator_XIX_EXV1s_01_XIX_Klima_LIN2:65535, compu {phys=raw for raw 0..65533, 65534=Cxfffe_Init (CM_EXV1_Ist_Position_Aktuator_Cxfffe_Init), 65535=Cxffff_Fehler (CM_EXV1_Ist_Position_Aktuator_Cxffff_Fehler); unit Unit_None}, range phys 0..65533 Unit_None, raw 0..65535, unit=Unit_None, transfer-property=PENDING, to Klima(timeout 3.5 s)  # Statusbotschaft für die elektrischen Kältemittelexpansionsventile
            signal EXV1_Geschwindigkeitsstatus_XIX_EXV1s_01_XIX_Klima_LIN2: start 16, 4 bit, little-endian, data-type-policy=OVERRIDE, i-signal-type=PRIMITIVE, base-type=BT_EXV1_Geschwindigkeitsstatus, invalid-value=Invalid_EXV1_Geschwindigkeitsstatus_XIX_EXV1s_01_XIX_Klima_LIN2:15, compu {0=Cx0_Motor_steht (CM_EXV1_Geschwindigkeitsstatus_Cx0_Motor_steht), 1=Cx1_Geschwindigkeitsstufe_1 (CM_EXV1_Geschwindigkeitsstatus_Cx1_Geschwindigkeitsstufe_1), 2=Cx2_Geschwindigkeitsstufe_2 (CM_EXV1_Geschwindigkeitsstatus_Cx2_Geschwindigkeitsstufe_2), 3=Cx3_Geschwindigkeitsstufe_3 (CM_EXV1_Geschwindigkeitsstatus_Cx3_Geschwindigkeitsstufe_3), 4=Cx4_Geschwindigkeitsstufe_4 (CM_EXV1_Geschwindigkeitsstatus_Cx4_Geschwindigkeitsstufe_4), 5=Cx5_Autospeed (CM_EXV1_Geschwindigkeitsstatus_Cx5_Autospeed), 15=Cxf_Fehler (CM_EXV1_Geschwindigkeitsstatus_Cxf_Fehler)}, range raw 0..15, transfer-property=PENDING, to Klima(timeout 3.5 s)  # Statusbotschaft für die elektrischen Kältemittelexpansionsventile
            signal EXV1_Temp_Warning_XIX_EXV1s_01_XIX_Klima_LIN2: start 20, 1 bit, little-endian, data-type-policy=OVERRIDE, i-signal-type=PRIMITIVE, base-type=BT_EXV1_Temp_Warning, compu {0=Cx0_keine_Warnschwelle (CM_EXV1_Temp_Warning_Cx0_keine_Warnschwelle), 1=Cx1_Warnschwelle_erreicht (CM_EXV1_Temp_Warning_Cx1_Warnschwelle_erreicht)}, range raw 0..1, transfer-property=PENDING, to Klima(timeout 3.5 s)  # Statusbotschaft für die elektrischen Kältemittelexpansionsventile
            signal EXV1_Temp_XIX_EXV1s_01_XIX_Klima_LIN2: start 24, 8 bit, little-endian, data-type-policy=OVERRIDE, i-signal-type=PRIMITIVE, init-value=254, base-type=BT_EXV1_Temp, invalid-value=Invalid_EXV1_Temp_XIX_EXV1s_01_XIX_Klima_LIN2:255, compu {phys=raw-50 for raw 0..253, 254=Cxfe_Init (CM_EXV1_Temp_Cxfe_Init), 255=Cxff_Fehler (CM_EXV1_Temp_Cxff_Fehler); unit Unit_DegreCelsi}, range phys -50..203 Unit_DegreCelsi, raw 0..255, unit=Unit_DegreCelsi, transfer-property=PENDING, to Klima(timeout 3.5 s)  # Platinentemperatur, Statusbotschaft für die elektrischen Kältemittelexpansionsventile
            signal EXV1_Spulenbestromung_XIX_EXV1s_01_XIX_Klima_LIN2: start 32, 2 bit, little-endian, data-type-policy=OVERRIDE, i-signal-type=PRIMITIVE, base-type=BT_EXV1_Spulenbestromung, invalid-value=Invalid_EXV1_Spulenbestromung_XIX_EXV1s_01_XIX_Klima_LIN2:3, compu {0=Cx0_Motorspulen_unbestromt (CM_EXV1_Spulenbestromung_Cx0_Motorspulen_unbestromt), 1=Cx1_Motorspulen_bestromt (CM_EXV1_Spulenbestromung_Cx1_Motorspulen_bestromt), 2=Cx2_reserviert (CM_EXV1_Spulenbestromung_Cx2_reserviert), 3=Cx3_Fehler (CM_EXV1_Spulenbestromung_Cx3_Fehler)}, range raw 0..3, transfer-property=PENDING, to Klima(timeout 3.5 s)  # Statusbotschaft für die elektrischen Kältemittelexpansionsventile
            signal EXV1_ErrMem_State_XIX_EXV1s_01_XIX_Klima_LIN2: start 38, 2 bit, little-endian, data-type-policy=OVERRIDE, i-signal-type=PRIMITIVE, init-value=2, base-type=BT_EXV1_ErrMem_State, compu {0=Cx0_Init_Default (CM_EXV1_ErrMem_State_Cx0_Init_Default), 1=Cx1_ErrMem_Active_State (CM_EXV1_ErrMem_State_Cx1_ErrMem_Active_State), 2=Cx2_ErrMem_InitProgress (CM_EXV1_ErrMem_State_Cx2_ErrMem_InitProgress), 3=Cx3_ErrMem_Init_done (CM_EXV1_ErrMem_State_Cx3_ErrMem_Init_done)}, range raw 0..3, transfer-property=PENDING, to Klima(timeout 3.5 s)  # OBD Signal, Statusbotschaft für die elektrischen Kältemittelexpansionsventile
            signal EXV1_ResponseError_XIX_EXV1s_01_XIX_Klima_LIN2: start 40, 1 bit, little-endian, data-type-policy=OVERRIDE, i-signal-type=PRIMITIVE, init-value=0, base-type=BT_EXV1_ResponseError, invalid-value=Invalid_EXV1_ResponseError_XIX_EXV1s_01_XIX_Klima_LIN2:1, compu {0=Cx0_normal (CM_EXV1_ResponseError_Cx0_normal), 1=Cx1_Fehler (CM_EXV1_ResponseError_Cx1_Fehler)}, range raw 0..1, transfer-property=PENDING, to Klima(timeout 3.5 s)  # siehe LIN2.0-Specification (Darf nicht über ein Fehlergueltigkeitsbit abgesichtert werden!)
            signal EXV1_ResponseError_TNCTOC_XIX_EXV1s_01_XIX_Klima_LIN2: start 41, 1 bit, little-endian, data-type-policy=OVERRIDE, i-signal-type=PRIMITIVE, init-value=1, base-type=BT_EXV1_ResponseError_TNCTOC, compu {0=Cx0_DTC_test_completed_this_operation_cylce (CM_EXV1_ResponseError_TNCTOC_Cx0_DTC_test_completed_this_operation_cylce), 1=Cx1_DTC_test_not_completed_this_operation_cylce (CM_EXV1_ResponseError_TNCTOC_Cx1_DTC_test_not_completed_this_operation_cylce)}, range raw 0..1, transfer-property=PENDING, to Klima(timeout 3.5 s)  # OBD TestFailed Flag, Statusbotschaft für die elektrischen Kältemittelexpansionsventile
            signal EXV1_Err_EDefekt_MoKomp_TF_XIX_EXV1s_01_XIX_Klima_LIN2: start 42, 1 bit, little-endian, data-type-policy=OVERRIDE, i-signal-type=PRIMITIVE, base-type=BT_EXV1_Err_EDefekt_MoKomp_TF, compu {0=Cx0_passive (CM_EXV1_Err_EDefekt_MoKomp_TF_Cx0_passive), 1=Cx1_active (CM_EXV1_Err_EDefekt_MoKomp_TF_Cx1_active)}, range raw 0..1, transfer-property=PENDING, to Klima(timeout 3.5 s)  # OBD TestFailed Flag, Statusbotschaft für die elektrischen Kältemittelexpansionsventile
            signal EXV1_Err_EDefekt_MoKomp_TNCTOC_XIX_EXV1s_01_XIX_Klima_LIN2: start 43, 1 bit, little-endian, data-type-policy=OVERRIDE, i-signal-type=PRIMITIVE, init-value=1, base-type=BT_EXV1_Err_EDefekt_MoKomp_TNCTOC, compu {0=Cx0_DTC_test_completed_this_operation_cylce (CM_EXV1_Err_EDefekt_MoKomp_TNCTOC_Cx0_DTC_test_completed_this_operation_cylce), 1=Cx1_DTC_test_not_completed_this_operation_cylce (CM_EXV1_Err_EDefekt_MoKomp_TNCTOC_Cx1_DTC_test_not_completed_this_operation_cylce)}, range raw 0..1, transfer-property=PENDING, to Klima(timeout 3.5 s)  # OBD TestFailed Flag, Statusbotschaft für die elektrischen Kältemittelexpansionsventile
            signal EXV1_Err_EDefekt_TSens_TF_XIX_EXV1s_01_XIX_Klima_LIN2: start 44, 1 bit, little-endian, data-type-policy=OVERRIDE, i-signal-type=PRIMITIVE, base-type=BT_EXV1_Err_EDefekt_TSens_TF, compu {0=Cx0_passive (CM_EXV1_Err_EDefekt_TSens_TF_Cx0_passive), 1=Cx1_active (CM_EXV1_Err_EDefekt_TSens_TF_Cx1_active)}, range raw 0..1, transfer-property=PENDING, to Klima(timeout 3.5 s)  # OBD TestFailed Flag, Statusbotschaft für die elektrischen Kältemittelexpansionsventile Fehlermeldung für Temperatursensor
            signal EXV1_Err_EDefekt_TSens_TNCTOC_XIX_EXV1s_01_XIX_Klima_LIN2: start 45, 1 bit, little-endian, data-type-policy=OVERRIDE, i-signal-type=PRIMITIVE, init-value=1, base-type=BT_EXV1_Err_EDefekt_TSens_TNCTOC, compu {0=Cx0_DTC_test_completed_this_operation_cylce (CM_EXV1_Err_EDefekt_TSens_TNCTOC_Cx0_DTC_test_completed_this_operation_cylce), 1=Cx1_DTC_test_not_completed_this_operation_cylce (CM_EXV1_Err_EDefekt_TSens_TNCTOC_Cx1_DTC_test_not_completed_this_operation_cylce)}, range raw 0..1, transfer-property=PENDING, to Klima(timeout 3.5 s)  # OBD TestFailed Flag, Statusbotschaft für die elektrischen Kältemittelexpansionsventile
            signal EXV1_Err_Uebertemperatur_TF_XIX_EXV1s_01_XIX_Klima_LIN2: start 46, 1 bit, little-endian, data-type-policy=OVERRIDE, i-signal-type=PRIMITIVE, base-type=BT_EXV1_Err_Uebertemperatur_TF, compu {0=Cx0_passive (CM_EXV1_Err_Uebertemperatur_TF_Cx0_passive), 1=Cx1_active (CM_EXV1_Err_Uebertemperatur_TF_Cx1_active)}, range raw 0..1, transfer-property=PENDING, to Klima(timeout 3.5 s)  # OBD TestFailed Flag, Statusbotschaft für die elektrischen Kältemittelexpansionsventile
            signal EXV1_Err_Uebertemperatur_TNCTOC_XIX_EXV1s_01_XIX_Klima_LIN2: start 47, 1 bit, little-endian, data-type-policy=OVERRIDE, i-signal-type=PRIMITIVE, init-value=1, base-type=BT_EXV1_Err_Uebertemperatur_TNCTOC, compu {0=Cx0_DTC_test_completed_this_operation_cylce (CM_EXV1_Err_Uebertemperatur_TNCTOC_Cx0_DTC_test_completed_this_operation_cylce), 1=Cx1_DTC_test_not_completed_this_operation_cylce (CM_EXV1_Err_Uebertemperatur_TNCTOC_Cx1_DTC_test_not_completed_this_operation_cylce)}, range raw 0..1, transfer-property=PENDING, to Klima(timeout 3.5 s)  # OBD TestFailed Flag, Statusbotschaft für die elektrischen Kältemittelexpansionsventile
            signal EXV1_Err_Ueberspannung_TF_XIX_EXV1s_01_XIX_Klima_LIN2: start 48, 1 bit, little-endian, data-type-policy=OVERRIDE, i-signal-type=PRIMITIVE, base-type=BT_EXV1_Err_Ueberspannung_TF, compu {0=Cx0_passive (CM_EXV1_Err_Ueberspannung_TF_Cx0_passive), 1=Cx1_active (CM_EXV1_Err_Ueberspannung_TF_Cx1_active)}, range raw 0..1, transfer-property=PENDING, to Klima(timeout 3.5 s)  # OBD TestFailed Flag, Statusbotschaft für die elektrischen Kältemittelexpansionsventile Fehlermeldung für Ueberspannung
            signal EXV1_Err_Ueberspannung_TNCTOC_XIX_EXV1s_01_XIX_Klima_LIN2: start 49, 1 bit, little-endian, data-type-policy=OVERRIDE, i-signal-type=PRIMITIVE, init-value=1, base-type=BT_EXV1_Err_Ueberspannung_TNCTOC, compu {0=Cx0_DTC_test_completed_this_operation_cylce (CM_EXV1_Err_Ueberspannung_TNCTOC_Cx0_DTC_test_completed_this_operation_cylce), 1=Cx1_DTC_test_not_completed_this_operation_cylce (CM_EXV1_Err_Ueberspannung_TNCTOC_Cx1_DTC_test_not_completed_this_operation_cylce)}, range raw 0..1, transfer-property=PENDING, to Klima(timeout 3.5 s)  # OBD TestFailed Flag, Statusbotschaft für die elektrischen Kältemittelexpansionsventile
            signal EXV1_Err_Unterspannung_TF_XIX_EXV1s_01_XIX_Klima_LIN2: start 50, 1 bit, little-endian, data-type-policy=OVERRIDE, i-signal-type=PRIMITIVE, base-type=BT_EXV1_Err_Unterspannung_TF, compu {0=Cx0_passive (CM_EXV1_Err_Unterspannung_TF_Cx0_passive), 1=Cx1_active (CM_EXV1_Err_Unterspannung_TF_Cx1_active)}, range raw 0..1, transfer-property=PENDING, to Klima(timeout 3.5 s)  # OBD TestFailed Flag, Statusbotschaft für die elektrischen Kältemittelexpansionsventile Fehlermeldung für Unterspannung
            signal EXV1_Err_Unterspannung_TNCTOC_XIX_EXV1s_01_XIX_Klima_LIN2: start 51, 1 bit, little-endian, data-type-policy=OVERRIDE, i-signal-type=PRIMITIVE, init-value=1, base-type=BT_EXV1_Err_Unterspannung_TNCTOC, compu {0=Cx0_DTC_test_completed_this_operation_cylce (CM_EXV1_Err_Unterspannung_TNCTOC_Cx0_DTC_test_completed_this_operation_cylce), 1=Cx1_DTC_test_not_completed_this_operation_cylce (CM_EXV1_Err_Unterspannung_TNCTOC_Cx1_DTC_test_not_completed_this_operation_cylce)}, range raw 0..1, transfer-property=PENDING, to Klima(timeout 3.5 s)  # OBD TestFailed Flag, Statusbotschaft für die elektrischen Kältemittelexpansionsventile
            signal EXV1_Err_Blockierung_TF_XIX_EXV1s_01_XIX_Klima_LIN2: start 52, 1 bit, little-endian, data-type-policy=OVERRIDE, i-signal-type=PRIMITIVE, base-type=BT_EXV1_Err_Blockierung_TF, compu {0=Cx0_passive (CM_EXV1_Err_Blockierung_TF_Cx0_passive), 1=Cx1_active (CM_EXV1_Err_Blockierung_TF_Cx1_active)}, range raw 0..1, transfer-property=PENDING, to Klima(timeout 3.5 s)  # OBD TestFailed Flag, Statusbotschaft für die elektrischen Kältemittelexpansionsventile
            signal EXV1_Err_Blockierung_TNCTOC_XIX_EXV1s_01_XIX_Klima_LIN2: start 53, 1 bit, little-endian, data-type-policy=OVERRIDE, i-signal-type=PRIMITIVE, init-value=1, base-type=BT_EXV1_Err_Blockierung_TNCTOC, compu {0=Cx0_DTC_test_completed_this_operation_cylce (CM_EXV1_Err_Blockierung_TNCTOC_Cx0_DTC_test_completed_this_operation_cylce), 1=Cx1_DTC_test_not_completed_this_operation_cylce (CM_EXV1_Err_Blockierung_TNCTOC_Cx1_DTC_test_not_completed_this_operation_cylce)}, range raw 0..1, transfer-property=PENDING, to Klima(timeout 3.5 s)  # OBD TestFailed Flag, Statusbotschaft für die elektrischen Kältemittelexpansionsventile
            signal EXV1_Err_RAMROMNADChange_TF_XIX_EXV1s_01_XIX_Klima_LIN2: start 54, 1 bit, little-endian, data-type-policy=OVERRIDE, i-signal-type=PRIMITIVE, base-type=BT_EXV1_Err_RAMROMNADChange_TF, compu {0=Cx0_passive (CM_EXV1_Err_RAMROMNADChange_TF_Cx0_passive), 1=Cx1_active (CM_EXV1_Err_RAMROMNADChange_TF_Cx1_active)}, range raw 0..1, transfer-property=PENDING, to Klima(timeout 3.5 s)  # OBD TestFailed Flag, Statusbotschaft für die elektrischen Kältemittelexpansionsventile
            signal EXV1_Err_RAMROMNADChange_TNCTOC_XIX_EXV1s_01_XIX_Klima_LIN2: start 55, 1 bit, little-endian, data-type-policy=OVERRIDE, i-signal-type=PRIMITIVE, init-value=1, base-type=BT_EXV1_Err_RAMROMNADChange_TNCTOC, compu {0=Cx0_DTC_test_completed_this_operation_cylce (CM_EXV1_Err_RAMROMNADChange_TNCTOC_Cx0_DTC_test_completed_this_operation_cylce), 1=Cx1_DTC_test_not_completed_this_operation_cylce (CM_EXV1_Err_RAMROMNADChange_TNCTOC_Cx1_DTC_test_not_completed_this_operation_cylce)}, range raw 0..1, transfer-property=PENDING, to Klima(timeout 3.5 s)  # OBD TestFailed Flag, Statusbotschaft für die elektrischen Kältemittelexpansionsventile
            signal EXV1_Err_Notlaufpos_TF_XIX_EXV1s_01_XIX_Klima_LIN2: start 56, 1 bit, little-endian, data-type-policy=OVERRIDE, i-signal-type=PRIMITIVE, base-type=BT_EXV1_Err_Notlaufpos_TF, compu {0=Cx0_passive (CM_EXV1_Err_Notlaufpos_TF_Cx0_passive), 1=Cx1_active (CM_EXV1_Err_Notlaufpos_TF_Cx1_active)}, range raw 0..1, transfer-property=PENDING, to Klima(timeout 3.5 s)  # OBD TestFailed Flag, Statusbotschaft für die elektrischen Kältemittelexpansionsventile
            signal EXV1_Err_Notlaufpos_TNCTOC_XIX_EXV1s_01_XIX_Klima_LIN2: start 57, 1 bit, little-endian, data-type-policy=OVERRIDE, i-signal-type=PRIMITIVE, init-value=1, base-type=BT_EXV1_Err_Notlaufpos_TNCTOC, compu {0=Cx0_DTC_test_completed_this_operation_cylce (CM_EXV1_Err_Notlaufpos_TNCTOC_Cx0_DTC_test_completed_this_operation_cylce), 1=Cx1_DTC_test_not_completed_this_operation_cylce (CM_EXV1_Err_Notlaufpos_TNCTOC_Cx1_DTC_test_not_completed_this_operation_cylce)}, range raw 0..1, transfer-property=PENDING, to Klima(timeout 3.5 s)  # OBD TestFailed Flag, Statusbotschaft für die elektrischen Kältemittelexpansionsventile
        frame EXV2s_01_XIX_Klima_LIN2: id 0x19, to Klima, frame-length=8, lin-checksum=ENHANCED
          pdu EXV2s_01_XIX_Klima_LIN2: length=8, unused-bit-pattern=0
            signal EXV2_Ist_Position_Aktuator_XIX_EXV2s_01_XIX_Klima_LIN2: start 0, 16 bit, little-endian, data-type-policy=OVERRIDE, i-signal-type=PRIMITIVE, init-value=65534, base-type=BT_EXV2_Ist_Position_Aktuator, invalid-value=Invalid_EXV2_Ist_Position_Aktuator_XIX_EXV2s_01_XIX_Klima_LIN2:65535, compu {phys=raw for raw 0..65533, 65534=Cxfffe_Init (CM_EXV2_Ist_Position_Aktuator_Cxfffe_Init), 65535=Cxffff_Fehler (CM_EXV2_Ist_Position_Aktuator_Cxffff_Fehler); unit Unit_None}, range phys 0..65533 Unit_None, raw 0..65535, unit=Unit_None, transfer-property=PENDING, to Klima(timeout 3.5 s)  # Statusbotschaft für die elektrischen Kältemittelexpansionsventile
            signal EXV2_Geschwindigkeitsstatus_XIX_EXV2s_01_XIX_Klima_LIN2: start 16, 4 bit, little-endian, data-type-policy=OVERRIDE, i-signal-type=PRIMITIVE, base-type=BT_EXV2_Geschwindigkeitsstatus, invalid-value=Invalid_EXV2_Geschwindigkeitsstatus_XIX_EXV2s_01_XIX_Klima_LIN2:15, compu {0=Cx0_Motor_steht (CM_EXV2_Geschwindigkeitsstatus_Cx0_Motor_steht), 1=Cx1_Geschwindigkeitsstufe_1 (CM_EXV2_Geschwindigkeitsstatus_Cx1_Geschwindigkeitsstufe_1), 2=Cx2_Geschwindigkeitsstufe_2 (CM_EXV2_Geschwindigkeitsstatus_Cx2_Geschwindigkeitsstufe_2), 3=Cx3_Geschwindigkeitsstufe_3 (CM_EXV2_Geschwindigkeitsstatus_Cx3_Geschwindigkeitsstufe_3), 4=Cx4_Geschwindigkeitsstufe_4 (CM_EXV2_Geschwindigkeitsstatus_Cx4_Geschwindigkeitsstufe_4), 5=Cx5_Autospeed (CM_EXV2_Geschwindigkeitsstatus_Cx5_Autospeed), 15=Cxf_Fehler (CM_EXV2_Geschwindigkeitsstatus_Cxf_Fehler)}, range raw 0..15, transfer-property=PENDING, to Klima(timeout 3.5 s)  # Statusbotschaft für die elektrischen Kältemittelexpansionsventile
            signal EXV2_Temp_Warning_XIX_EXV2s_01_XIX_Klima_LIN2: start 20, 1 bit, little-endian, data-type-policy=OVERRIDE, i-signal-type=PRIMITIVE, base-type=BT_EXV2_Temp_Warning, compu {0=Cx0_keine_Warnschwelle (CM_EXV2_Temp_Warning_Cx0_keine_Warnschwelle), 1=Cx1_Warnschwelle_erreicht (CM_EXV2_Temp_Warning_Cx1_Warnschwelle_erreicht)}, range raw 0..1, transfer-property=PENDING, to Klima(timeout 3.5 s)  # Statusbotschaft für die elektrischen Kältemittelexpansionsventile
            signal EXV2_Temp_XIX_EXV2s_01_XIX_Klima_LIN2: start 24, 8 bit, little-endian, data-type-policy=OVERRIDE, i-signal-type=PRIMITIVE, init-value=254, base-type=BT_EXV2_Temp, invalid-value=Invalid_EXV2_Temp_XIX_EXV2s_01_XIX_Klima_LIN2:255, compu {phys=raw-50 for raw 0..253, 254=Cxfe_Init (CM_EXV2_Temp_Cxfe_Init), 255=Cxff_Fehler (CM_EXV2_Temp_Cxff_Fehler); unit Unit_DegreCelsi}, range phys -50..203 Unit_DegreCelsi, raw 0..255, unit=Unit_DegreCelsi, transfer-property=PENDING, to Klima(timeout 3.5 s)  # Platinentemperatur, Statusbotschaft für die elektrischen Kältemittelexpansionsventile
            signal EXV2_Spulenbestromung_XIX_EXV2s_01_XIX_Klima_LIN2: start 32, 2 bit, little-endian, data-type-policy=OVERRIDE, i-signal-type=PRIMITIVE, base-type=BT_EXV2_Spulenbestromung, invalid-value=Invalid_EXV2_Spulenbestromung_XIX_EXV2s_01_XIX_Klima_LIN2:3, compu {0=Cx0_Motorspulen_unbestromt (CM_EXV2_Spulenbestromung_Cx0_Motorspulen_unbestromt), 1=Cx1_Motorspulen_bestromt (CM_EXV2_Spulenbestromung_Cx1_Motorspulen_bestromt), 2=Cx2_reserviert (CM_EXV2_Spulenbestromung_Cx2_reserviert), 3=Cx3_Fehler (CM_EXV2_Spulenbestromung_Cx3_Fehler)}, range raw 0..3, transfer-property=PENDING, to Klima(timeout 3.5 s)  # Statusbotschaft für die elektrischen Kältemittelexpansionsventile
            signal EXV2_ErrMem_State_XIX_EXV2s_01_XIX_Klima_LIN2: start 38, 2 bit, little-endian, data-type-policy=OVERRIDE, i-signal-type=PRIMITIVE, init-value=2, base-type=BT_EXV2_ErrMem_State, compu {1=Cx1_ErrMem_Active (CM_EXV2_ErrMem_State_Cx1_ErrMem_Active), 2=Cx2_ErrMem_Init_Progress (CM_EXV2_ErrMem_State_Cx2_ErrMem_Init_Progress), 3=Cx3_ErrMem_Init_Done (CM_EXV2_ErrMem_State_Cx3_ErrMem_Init_Done)}, range raw 1..3, transfer-property=PENDING, to Klima(timeout 3.5 s)  # Error Memory State
            signal EXV2_ResponseError_XIX_EXV2s_01_XIX_Klima_LIN2: start 40, 1 bit, little-endian, data-type-policy=OVERRIDE, i-signal-type=PRIMITIVE, init-value=0, base-type=BT_EXV2_ResponseError, invalid-value=Invalid_EXV2_ResponseError_XIX_EXV2s_01_XIX_Klima_LIN2:1, compu {0=Cx0_normal (CM_EXV2_ResponseError_Cx0_normal), 1=Cx1_Fehler (CM_EXV2_ResponseError_Cx1_Fehler)}, range raw 0..1, transfer-property=PENDING, to Klima(timeout 3.5 s)  # siehe LIN2.0-Specification (Darf nicht über ein Fehlergueltigkeitsbit abgesichtert werden!)
            signal EXV2_ResponseError_TNCTOC_XIX_EXV2s_01_XIX_Klima_LIN2: start 41, 1 bit, little-endian, data-type-policy=OVERRIDE, i-signal-type=PRIMITIVE, init-value=1, base-type=BT_EXV2_ResponseError_TNCTOC, compu {0=Cx0_DTC_test_completed_this_operation_cylce (CM_EXV2_ResponseError_TNCTOC_Cx0_DTC_test_completed_this_operation_cylce), 1=Cx1_DTC_test_not_completed_this_operation_cylce (CM_EXV2_ResponseError_TNCTOC_Cx1_DTC_test_not_completed_this_operation_cylce)}, range raw 0..1, transfer-property=PENDING, to Klima(timeout 3.5 s)  # OBD TestFailed Flag, Statusbotschaft für die elektrischen Kältemittelexpansionsventile
            signal EXV2_Err_EDefekt_MoKomp_TF_XIX_EXV2s_01_XIX_Klima_LIN2: start 42, 1 bit, little-endian, data-type-policy=OVERRIDE, i-signal-type=PRIMITIVE, base-type=BT_EXV2_Err_EDefekt_MoKomp_TF, compu {0=Cx0_passive (CM_EXV2_Err_EDefekt_MoKomp_TF_Cx0_passive), 1=Cx1_active (CM_EXV2_Err_EDefekt_MoKomp_TF_Cx1_active)}, range raw 0..1, transfer-property=PENDING, to Klima(timeout 3.5 s)  # OBD TestFailed Flag, Statusbotschaft für die elektrischen Kältemittelexpansionsventile
            signal EXV2_Err_EDefekt_MoKomp_TNCTOC_XIX_EXV2s_01_XIX_Klima_LIN2: start 43, 1 bit, little-endian, data-type-policy=OVERRIDE, i-signal-type=PRIMITIVE, init-value=1, base-type=BT_EXV2_Err_EDefekt_MoKomp_TNCTOC, compu {0=Cx0_DTC_test_completed_this_operation_cylce (CM_EXV2_Err_EDefekt_MoKomp_TNCTOC_Cx0_DTC_test_completed_this_operation_cylce), 1=Cx1_DTC_test_not_completed_this_operation_cylce (CM_EXV2_Err_EDefekt_MoKomp_TNCTOC_Cx1_DTC_test_not_completed_this_operation_cylce)}, range raw 0..1, transfer-property=PENDING, to Klima(timeout 3.5 s)  # OBD TestFailed Flag, Statusbotschaft für die elektrischen Kältemittelexpansionsventile
            signal EXV2_Err_EDefekt_TSens_TF_XIX_EXV2s_01_XIX_Klima_LIN2: start 44, 1 bit, little-endian, data-type-policy=OVERRIDE, i-signal-type=PRIMITIVE, base-type=BT_EXV2_Err_EDefekt_TSens_TF, compu {0=Cx0_passive (CM_EXV2_Err_EDefekt_TSens_TF_Cx0_passive), 1=Cx1_active (CM_EXV2_Err_EDefekt_TSens_TF_Cx1_active)}, range raw 0..1, transfer-property=PENDING, to Klima(timeout 3.5 s)  # OBD TestFailed Flag, Statusbotschaft für die elektrischen Kältemittelexpansionsventile
            signal EXV2_Err_EDefekt_TSens_TNCTOC_XIX_EXV2s_01_XIX_Klima_LIN2: start 45, 1 bit, little-endian, data-type-policy=OVERRIDE, i-signal-type=PRIMITIVE, init-value=1, base-type=BT_EXV2_Err_EDefekt_TSens_TNCTOC, compu {0=Cx0_DTC_test_completed_this_operation_cylce (CM_EXV2_Err_EDefekt_TSens_TNCTOC_Cx0_DTC_test_completed_this_operation_cylce), 1=Cx1_DTC_test_not_completed_this_operation_cylce (CM_EXV2_Err_EDefekt_TSens_TNCTOC_Cx1_DTC_test_not_completed_this_operation_cylce)}, range raw 0..1, transfer-property=PENDING, to Klima(timeout 3.5 s)  # OBD TestFailed Flag, Statusbotschaft für die elektrischen Kältemittelexpansionsventile
            signal EXV2_Err_Uebertemperatur_TF_XIX_EXV2s_01_XIX_Klima_LIN2: start 46, 1 bit, little-endian, data-type-policy=OVERRIDE, i-signal-type=PRIMITIVE, base-type=BT_EXV2_Err_Uebertemperatur_TF, compu {0=Cx0_passive (CM_EXV2_Err_Uebertemperatur_TF_Cx0_passive), 1=Cx1_active (CM_EXV2_Err_Uebertemperatur_TF_Cx1_active)}, range raw 0..1, transfer-property=PENDING, to Klima(timeout 3.5 s)  # OBD TestFailed Flag, Statusbotschaft für die elektrischen Kältemittelexpansionsventile
            signal EXV2_Err_Uebertemperatur_TNCTOC_XIX_EXV2s_01_XIX_Klima_LIN2: start 47, 1 bit, little-endian, data-type-policy=OVERRIDE, i-signal-type=PRIMITIVE, init-value=1, base-type=BT_EXV2_Err_Uebertemperatur_TNCTOC, compu {0=Cx0_DTC_test_completed_this_operation_cylce (CM_EXV2_Err_Uebertemperatur_TNCTOC_Cx0_DTC_test_completed_this_operation_cylce), 1=Cx1_DTC_test_not_completed_this_operation_cylce (CM_EXV2_Err_Uebertemperatur_TNCTOC_Cx1_DTC_test_not_completed_this_operation_cylce)}, range raw 0..1, transfer-property=PENDING, to Klima(timeout 3.5 s)  # OBD TestFailed Flag, Statusbotschaft für die elektrischen Kältemittelexpansionsventile
            signal EXV2_Err_Ueberspannung_TF_XIX_EXV2s_01_XIX_Klima_LIN2: start 48, 1 bit, little-endian, data-type-policy=OVERRIDE, i-signal-type=PRIMITIVE, base-type=BT_EXV2_Err_Ueberspannung_TF, compu {0=Cx0_passive (CM_EXV2_Err_Ueberspannung_TF_Cx0_passive), 1=Cx1_active (CM_EXV2_Err_Ueberspannung_TF_Cx1_active)}, range raw 0..1, transfer-property=PENDING, to Klima(timeout 3.5 s)  # OBD TestFailed Flag, Statusbotschaft für die elektrischen Kältemittelexpansionsventile
            signal EXV2_Err_Ueberspannung_TNCTOC_XIX_EXV2s_01_XIX_Klima_LIN2: start 49, 1 bit, little-endian, data-type-policy=OVERRIDE, i-signal-type=PRIMITIVE, init-value=1, base-type=BT_EXV2_Err_Ueberspannung_TNCTOC, compu {0=Cx0_DTC_test_completed_this_operation_cylce (CM_EXV2_Err_Ueberspannung_TNCTOC_Cx0_DTC_test_completed_this_operation_cylce), 1=Cx1_DTC_test_not_completed_this_operation_cylce (CM_EXV2_Err_Ueberspannung_TNCTOC_Cx1_DTC_test_not_completed_this_operation_cylce)}, range raw 0..1, transfer-property=PENDING, to Klima(timeout 3.5 s)  # OBD TestFailed Flag, Statusbotschaft für die elektrischen Kältemittelexpansionsventile
            signal EXV2_Err_Unterspannung_TF_XIX_EXV2s_01_XIX_Klima_LIN2: start 50, 1 bit, little-endian, data-type-policy=OVERRIDE, i-signal-type=PRIMITIVE, base-type=BT_EXV2_Err_Unterspannung_TF, compu {0=Cx0_passive (CM_EXV2_Err_Unterspannung_TF_Cx0_passive), 1=Cx1_active (CM_EXV2_Err_Unterspannung_TF_Cx1_active)}, range raw 0..1, transfer-property=PENDING, to Klima(timeout 3.5 s)  # OBD TestFailed Flag, Statusbotschaft für die elektrischen Kältemittelexpansionsventile
            signal EXV2_Err_Unterspannung_TNCTOC_XIX_EXV2s_01_XIX_Klima_LIN2: start 51, 1 bit, little-endian, data-type-policy=OVERRIDE, i-signal-type=PRIMITIVE, init-value=1, base-type=BT_EXV2_Err_Unterspannung_TNCTOC, compu {0=Cx0_DTC_test_completed_this_operation_cylce (CM_EXV2_Err_Unterspannung_TNCTOC_Cx0_DTC_test_completed_this_operation_cylce), 1=Cx1_DTC_test_not_completed_this_operation_cylce (CM_EXV2_Err_Unterspannung_TNCTOC_Cx1_DTC_test_not_completed_this_operation_cylce)}, range raw 0..1, transfer-property=PENDING, to Klima(timeout 3.5 s)  # OBD TestFailed Flag, Statusbotschaft für die elektrischen Kältemittelexpansionsventile
            signal EXV2_Err_Blockierung_TF_XIX_EXV2s_01_XIX_Klima_LIN2: start 52, 1 bit, little-endian, data-type-policy=OVERRIDE, i-signal-type=PRIMITIVE, base-type=BT_EXV2_Err_Blockierung_TF, compu {0=Cx0_passive (CM_EXV2_Err_Blockierung_TF_Cx0_passive), 1=Cx1_active (CM_EXV2_Err_Blockierung_TF_Cx1_active)}, range raw 0..1, transfer-property=PENDING, to Klima(timeout 3.5 s)  # OBD TestFailed Flag, Statusbotschaft für die elektrischen Kältemittelexpansionsventile
            signal EXV2_Err_Blockierung_TNCTOC_XIX_EXV2s_01_XIX_Klima_LIN2: start 53, 1 bit, little-endian, data-type-policy=OVERRIDE, i-signal-type=PRIMITIVE, init-value=1, base-type=BT_EXV2_Err_Blockierung_TNCTOC, compu {0=Cx0_DTC_test_completed_this_operation_cylce (CM_EXV2_Err_Blockierung_TNCTOC_Cx0_DTC_test_completed_this_operation_cylce), 1=Cx1_DTC_test_not_completed_this_operation_cylce (CM_EXV2_Err_Blockierung_TNCTOC_Cx1_DTC_test_not_completed_this_operation_cylce)}, range raw 0..1, transfer-property=PENDING, to Klima(timeout 3.5 s)  # OBD TestFailed Flag, Statusbotschaft für die elektrischen Kältemittelexpansionsventile
            signal EXV2_Err_RAMROMNADChange_TF_XIX_EXV2s_01_XIX_Klima_LIN2: start 54, 1 bit, little-endian, data-type-policy=OVERRIDE, i-signal-type=PRIMITIVE, base-type=BT_EXV2_Err_RAMROMNADChange_TF, compu {0=Cx0_passive (CM_EXV2_Err_RAMROMNADChange_TF_Cx0_passive), 1=Cx1_active (CM_EXV2_Err_RAMROMNADChange_TF_Cx1_active)}, range raw 0..1, transfer-property=PENDING, to Klima(timeout 3.5 s)  # OBD TestFailed Flag, Statusbotschaft für die elektrischen Kältemittelexpansionsventile
            signal EXV2_Err_RAMROMNADChange_TNCTOC_XIX_EXV2s_01_XIX_Klima_LIN2: start 55, 1 bit, little-endian, data-type-policy=OVERRIDE, i-signal-type=PRIMITIVE, init-value=1, base-type=BT_EXV2_Err_RAMROMNADChange_TNCTOC, compu {0=Cx0_DTC_test_completed_this_operation_cylce (CM_EXV2_Err_RAMROMNADChange_TNCTOC_Cx0_DTC_test_completed_this_operation_cylce), 1=Cx1_DTC_test_not_completed_this_operation_cylce (CM_EXV2_Err_RAMROMNADChange_TNCTOC_Cx1_DTC_test_not_completed_this_operation_cylce)}, range raw 0..1, transfer-property=PENDING, to Klima(timeout 3.5 s)  # OBD TestFailed Flag, Statusbotschaft für die elektrischen Kältemittelexpansionsventile
            signal EXV2_Err_Notlaufpos_TF_XIX_EXV2s_01_XIX_Klima_LIN2: start 56, 1 bit, little-endian, data-type-policy=OVERRIDE, i-signal-type=PRIMITIVE, base-type=BT_EXV2_Err_Notlaufpos_TF, compu {0=Cx0_passive (CM_EXV2_Err_Notlaufpos_TF_Cx0_passive), 1=Cx1_active (CM_EXV2_Err_Notlaufpos_TF_Cx1_active)}, range raw 0..1, transfer-property=PENDING, to Klima(timeout 3.5 s)  # OBD TestFailed Flag, Statusbotschaft für die elektrischen Kältemittelexpansionsventile
            signal EXV2_Err_Notlaufpos_TNCTOC_XIX_EXV2s_01_XIX_Klima_LIN2: start 57, 1 bit, little-endian, data-type-policy=OVERRIDE, i-signal-type=PRIMITIVE, init-value=1, base-type=BT_EXV2_Err_Notlaufpos_TNCTOC, compu {0=Cx0_DTC_test_completed_this_operation_cylce (CM_EXV2_Err_Notlaufpos_TNCTOC_Cx0_DTC_test_completed_this_operation_cylce), 1=Cx1_DTC_test_not_completed_this_operation_cylce (CM_EXV2_Err_Notlaufpos_TNCTOC_Cx1_DTC_test_not_completed_this_operation_cylce)}, range raw 0..1, transfer-property=PENDING, to Klima(timeout 3.5 s)  # OBD TestFailed Flag, Statusbotschaft für die elektrischen Kältemittelexpansionsventile
        frame EXV3s_01_XIX_Klima_LIN2: id 0x2F, to Klima, frame-length=8, lin-checksum=ENHANCED
          pdu EXV3s_01_XIX_Klima_LIN2: length=8, unused-bit-pattern=0
            signal EXV3_Ist_Position_Aktuator_XIX_EXV3s_01_XIX_Klima_LIN2: start 0, 16 bit, little-endian, data-type-policy=OVERRIDE, i-signal-type=PRIMITIVE, init-value=65534, base-type=BT_EXV3_Ist_Position_Aktuator, invalid-value=Invalid_EXV3_Ist_Position_Aktuator_XIX_EXV3s_01_XIX_Klima_LIN2:65535, compu {phys=raw for raw 0..65533, 65534=Cxfffe_Init (CM_EXV3_Ist_Position_Aktuator_Cxfffe_Init), 65535=Cxffff_Fehler (CM_EXV3_Ist_Position_Aktuator_Cxffff_Fehler); unit Unit_None}, range phys 0..65533 Unit_None, raw 0..65535, unit=Unit_None, transfer-property=PENDING, to Klima(timeout 3.5 s)  # Statusbotschaft für die elektrischen Kältemittelexpansionsventile
            signal EXV3_Geschwindigkeitsstatus_XIX_EXV3s_01_XIX_Klima_LIN2: start 16, 4 bit, little-endian, data-type-policy=OVERRIDE, i-signal-type=PRIMITIVE, base-type=BT_EXV3_Geschwindigkeitsstatus, invalid-value=Invalid_EXV3_Geschwindigkeitsstatus_XIX_EXV3s_01_XIX_Klima_LIN2:15, compu {0=Cx0_Motor_steht (CM_EXV3_Geschwindigkeitsstatus_Cx0_Motor_steht), 1=Cx1_Geschwindigkeitsstufe_1 (CM_EXV3_Geschwindigkeitsstatus_Cx1_Geschwindigkeitsstufe_1), 2=Cx2_Geschwindigkeitsstufe_2 (CM_EXV3_Geschwindigkeitsstatus_Cx2_Geschwindigkeitsstufe_2), 3=Cx3_Geschwindigkeitsstufe_3 (CM_EXV3_Geschwindigkeitsstatus_Cx3_Geschwindigkeitsstufe_3), 4=Cx4_Geschwindigkeitsstufe_4 (CM_EXV3_Geschwindigkeitsstatus_Cx4_Geschwindigkeitsstufe_4), 5=Cx5_Autospeed (CM_EXV3_Geschwindigkeitsstatus_Cx5_Autospeed), 15=Cxf_Fehler (CM_EXV3_Geschwindigkeitsstatus_Cxf_Fehler)}, range raw 0..15, transfer-property=PENDING, to Klima(timeout 3.5 s)  # Statusbotschaft für die elektrischen Kältemittelexpansionsventile
            signal EXV3_Temp_Warning_XIX_EXV3s_01_XIX_Klima_LIN2: start 20, 1 bit, little-endian, data-type-policy=OVERRIDE, i-signal-type=PRIMITIVE, base-type=BT_EXV3_Temp_Warning, compu {0=Cx0_keine_Warnschwelle (CM_EXV3_Temp_Warning_Cx0_keine_Warnschwelle), 1=Cx1_Warnschwelle_erreicht (CM_EXV3_Temp_Warning_Cx1_Warnschwelle_erreicht)}, range raw 0..1, transfer-property=PENDING, to Klima(timeout 3.5 s)  # Statusbotschaft für die elektrischen Kältemittelexpansionsventile
            signal EXV3_Temp_XIX_EXV3s_01_XIX_Klima_LIN2: start 24, 8 bit, little-endian, data-type-policy=OVERRIDE, i-signal-type=PRIMITIVE, init-value=254, base-type=BT_EXV3_Temp, invalid-value=Invalid_EXV3_Temp_XIX_EXV3s_01_XIX_Klima_LIN2:255, compu {phys=raw-50 for raw 0..253, 254=Cxfe_Init (CM_EXV3_Temp_Cxfe_Init), 255=Cxff_Fehler (CM_EXV3_Temp_Cxff_Fehler); unit Unit_DegreCelsi}, range phys -50..203 Unit_DegreCelsi, raw 0..255, unit=Unit_DegreCelsi, transfer-property=PENDING, to Klima(timeout 3.5 s)  # Platinentemperatur, Statusbotschaft für die elektrischen Kältemittelexpansionsventile
            signal EXV3_Spulenbestromung_XIX_EXV3s_01_XIX_Klima_LIN2: start 32, 2 bit, little-endian, data-type-policy=OVERRIDE, i-signal-type=PRIMITIVE, base-type=BT_EXV3_Spulenbestromung, invalid-value=Invalid_EXV3_Spulenbestromung_XIX_EXV3s_01_XIX_Klima_LIN2:3, compu {0=Cx0_Motorspulen_unbestromt (CM_EXV3_Spulenbestromung_Cx0_Motorspulen_unbestromt), 1=Cx1_Motorspulen_bestromt (CM_EXV3_Spulenbestromung_Cx1_Motorspulen_bestromt), 2=Cx2_reserviert (CM_EXV3_Spulenbestromung_Cx2_reserviert), 3=Cx3_Fehler (CM_EXV3_Spulenbestromung_Cx3_Fehler)}, range raw 0..3, transfer-property=PENDING, to Klima(timeout 3.5 s)  # Statusbotschaft für die elektrischen Kältemittelexpansionsventile
            signal EXV3_ErrMem_State_XIX_EXV3s_01_XIX_Klima_LIN2: start 38, 2 bit, little-endian, data-type-policy=OVERRIDE, i-signal-type=PRIMITIVE, init-value=2, base-type=BT_EXV3_ErrMem_State, compu {1=Cx1_ErrMem_Active (CM_EXV3_ErrMem_State_Cx1_ErrMem_Active), 2=Cx2_ErrMem_Init_Progress (CM_EXV3_ErrMem_State_Cx2_ErrMem_Init_Progress), 3=Cx3_ErrMem_Init_Done (CM_EXV3_ErrMem_State_Cx3_ErrMem_Init_Done)}, range raw 1..3, transfer-property=PENDING, to Klima(timeout 3.5 s)  # Error Memory State
            signal EXV3_ResponseError_XIX_EXV3s_01_XIX_Klima_LIN2: start 40, 1 bit, little-endian, data-type-policy=OVERRIDE, i-signal-type=PRIMITIVE, init-value=0, base-type=BT_EXV3_ResponseError, invalid-value=Invalid_EXV3_ResponseError_XIX_EXV3s_01_XIX_Klima_LIN2:1, compu {0=Cx0_normal (CM_EXV3_ResponseError_Cx0_normal), 1=Cx1_Fehler (CM_EXV3_ResponseError_Cx1_Fehler)}, range raw 0..1, transfer-property=PENDING, to Klima(timeout 3.5 s)  # siehe LIN2.0-Specification (Darf nicht über ein Fehlergueltigkeitsbit abgesichtert werden!)
            signal EXV3_ResponseError_TNCTOC_XIX_EXV3s_01_XIX_Klima_LIN2: start 41, 1 bit, little-endian, data-type-policy=OVERRIDE, i-signal-type=PRIMITIVE, init-value=1, base-type=BT_EXV3_ResponseError_TNCTOC, compu {0=Cx0_DTC_test_completed_this_operation_cylce (CM_EXV3_ResponseError_TNCTOC_Cx0_DTC_test_completed_this_operation_cylce), 1=Cx1_DTC_test_not_completed_this_operation_cylce (CM_EXV3_ResponseError_TNCTOC_Cx1_DTC_test_not_completed_this_operation_cylce)}, range raw 0..1, transfer-property=PENDING, to Klima(timeout 3.5 s)  # OBD TestFailed Flag, Statusbotschaft für die elektrischen Kältemittelexpansionsventile
            signal EXV3_Err_EDefekt_MoKomp_TF_XIX_EXV3s_01_XIX_Klima_LIN2: start 42, 1 bit, little-endian, data-type-policy=OVERRIDE, i-signal-type=PRIMITIVE, base-type=BT_EXV3_Err_EDefekt_MoKomp_TF, compu {0=Cx0_passive (CM_EXV3_Err_EDefekt_MoKomp_TF_Cx0_passive), 1=Cx1_active (CM_EXV3_Err_EDefekt_MoKomp_TF_Cx1_active)}, range raw 0..1, transfer-property=PENDING, to Klima(timeout 3.5 s)  # OBD TestFailed Flag, Statusbotschaft für die elektrischen Kältemittelexpansionsventile
            signal EXV3_Err_EDefekt_MoKomp_TNCTOC_XIX_EXV3s_01_XIX_Klima_LIN2: start 43, 1 bit, little-endian, data-type-policy=OVERRIDE, i-signal-type=PRIMITIVE, init-value=1, base-type=BT_EXV3_Err_EDefekt_MoKomp_TNCTOC, compu {0=Cx0_DTC_test_completed_this_operation_cylce (CM_EXV3_Err_EDefekt_MoKomp_TNCTOC_Cx0_DTC_test_completed_this_operation_cylce), 1=Cx1_DTC_test_not_completed_this_operation_cylce (CM_EXV3_Err_EDefekt_MoKomp_TNCTOC_Cx1_DTC_test_not_completed_this_operation_cylce)}, range raw 0..1, transfer-property=PENDING, to Klima(timeout 3.5 s)  # OBD TestFailed Flag, Statusbotschaft für die elektrischen Kältemittelexpansionsventile
            signal EXV3_Err_EDefekt_TSens_TF_XIX_EXV3s_01_XIX_Klima_LIN2: start 44, 1 bit, little-endian, data-type-policy=OVERRIDE, i-signal-type=PRIMITIVE, base-type=BT_EXV3_Err_EDefekt_TSens_TF, compu {0=Cx0_passive (CM_EXV3_Err_EDefekt_TSens_TF_Cx0_passive), 1=Cx1_active (CM_EXV3_Err_EDefekt_TSens_TF_Cx1_active)}, range raw 0..1, transfer-property=PENDING, to Klima(timeout 3.5 s)  # OBD TestFailed Flag, Statusbotschaft für die elektrischen Kältemittelexpansionsventile
            signal EXV3_Err_EDefekt_TSens_TNCTOC_XIX_EXV3s_01_XIX_Klima_LIN2: start 45, 1 bit, little-endian, data-type-policy=OVERRIDE, i-signal-type=PRIMITIVE, init-value=1, base-type=BT_EXV3_Err_EDefekt_TSens_TNCTOC, compu {0=Cx0_DTC_test_completed_this_operation_cylce (CM_EXV3_Err_EDefekt_TSens_TNCTOC_Cx0_DTC_test_completed_this_operation_cylce), 1=Cx1_DTC_test_not_completed_this_operation_cylce (CM_EXV3_Err_EDefekt_TSens_TNCTOC_Cx1_DTC_test_not_completed_this_operation_cylce)}, range raw 0..1, transfer-property=PENDING, to Klima(timeout 3.5 s)  # OBD TestFailed Flag, Statusbotschaft für die elektrischen Kältemittelexpansionsventile
            signal EXV3_Err_Uebertemperatur_TF_XIX_EXV3s_01_XIX_Klima_LIN2: start 46, 1 bit, little-endian, data-type-policy=OVERRIDE, i-signal-type=PRIMITIVE, base-type=BT_EXV3_Err_Uebertemperatur_TF, compu {0=Cx0_passive (CM_EXV3_Err_Uebertemperatur_TF_Cx0_passive), 1=Cx1_active (CM_EXV3_Err_Uebertemperatur_TF_Cx1_active)}, range raw 0..1, transfer-property=PENDING, to Klima(timeout 3.5 s)  # OBD TestFailed Flag, Statusbotschaft für die elektrischen Kältemittelexpansionsventile
            signal EXV3_Err_Uebertemperatur_TNCTOC_XIX_EXV3s_01_XIX_Klima_LIN2: start 47, 1 bit, little-endian, data-type-policy=OVERRIDE, i-signal-type=PRIMITIVE, init-value=1, base-type=BT_EXV3_Err_Uebertemperatur_TNCTOC, compu {0=Cx0_DTC_test_completed_this_operation_cylce (CM_EXV3_Err_Uebertemperatur_TNCTOC_Cx0_DTC_test_completed_this_operation_cylce), 1=Cx1_DTC_test_not_completed_this_operation_cylce (CM_EXV3_Err_Uebertemperatur_TNCTOC_Cx1_DTC_test_not_completed_this_operation_cylce)}, range raw 0..1, transfer-property=PENDING, to Klima(timeout 3.5 s)  # OBD TestFailed Flag, Statusbotschaft für die elektrischen Kältemittelexpansionsventile
            signal EXV3_Err_Ueberspannung_TF_XIX_EXV3s_01_XIX_Klima_LIN2: start 48, 1 bit, little-endian, data-type-policy=OVERRIDE, i-signal-type=PRIMITIVE, base-type=BT_EXV3_Err_Ueberspannung_TF, compu {0=Cx0_passive (CM_EXV3_Err_Ueberspannung_TF_Cx0_passive), 1=Cx1_active (CM_EXV3_Err_Ueberspannung_TF_Cx1_active)}, range raw 0..1, transfer-property=PENDING, to Klima(timeout 3.5 s)  # OBD TestFailed Flag, Statusbotschaft für die elektrischen Kältemittelexpansionsventile
            signal EXV3_Err_Ueberspannung_TNCTOC_XIX_EXV3s_01_XIX_Klima_LIN2: start 49, 1 bit, little-endian, data-type-policy=OVERRIDE, i-signal-type=PRIMITIVE, init-value=1, base-type=BT_EXV3_Err_Ueberspannung_TNCTOC, compu {0=Cx0_DTC_test_completed_this_operation_cylce (CM_EXV3_Err_Ueberspannung_TNCTOC_Cx0_DTC_test_completed_this_operation_cylce), 1=Cx1_DTC_test_not_completed_this_operation_cylce (CM_EXV3_Err_Ueberspannung_TNCTOC_Cx1_DTC_test_not_completed_this_operation_cylce)}, range raw 0..1, transfer-property=PENDING, to Klima(timeout 3.5 s)  # OBD TestFailed Flag, Statusbotschaft für die elektrischen Kältemittelexpansionsventile
            signal EXV3_Err_Unterspannung_TF_XIX_EXV3s_01_XIX_Klima_LIN2: start 50, 1 bit, little-endian, data-type-policy=OVERRIDE, i-signal-type=PRIMITIVE, base-type=BT_EXV3_Err_Unterspannung_TF, compu {0=Cx0_passive (CM_EXV3_Err_Unterspannung_TF_Cx0_passive), 1=Cx1_active (CM_EXV3_Err_Unterspannung_TF_Cx1_active)}, range raw 0..1, transfer-property=PENDING, to Klima(timeout 3.5 s)  # OBD TestFailed Flag, Statusbotschaft für die elektrischen Kältemittelexpansionsventile
            signal EXV3_Err_Unterspannung_TNCTOC_XIX_EXV3s_01_XIX_Klima_LIN2: start 51, 1 bit, little-endian, data-type-policy=OVERRIDE, i-signal-type=PRIMITIVE, init-value=1, base-type=BT_EXV3_Err_Unterspannung_TNCTOC, compu {0=Cx0_DTC_test_completed_this_operation_cylce (CM_EXV3_Err_Unterspannung_TNCTOC_Cx0_DTC_test_completed_this_operation_cylce), 1=Cx1_DTC_test_not_completed_this_operation_cylce (CM_EXV3_Err_Unterspannung_TNCTOC_Cx1_DTC_test_not_completed_this_operation_cylce)}, range raw 0..1, transfer-property=PENDING, to Klima(timeout 3.5 s)  # OBD TestFailed Flag, Statusbotschaft für die elektrischen Kältemittelexpansionsventile
            signal EXV3_Err_Blockierung_TF_XIX_EXV3s_01_XIX_Klima_LIN2: start 52, 1 bit, little-endian, data-type-policy=OVERRIDE, i-signal-type=PRIMITIVE, base-type=BT_EXV3_Err_Blockierung_TF, compu {0=Cx0_passive (CM_EXV3_Err_Blockierung_TF_Cx0_passive), 1=Cx1_active (CM_EXV3_Err_Blockierung_TF_Cx1_active)}, range raw 0..1, transfer-property=PENDING, to Klima(timeout 3.5 s)  # OBD TestFailed Flag, Statusbotschaft für die elektrischen Kältemittelexpansionsventile
            signal EXV3_Err_Blockierung_TNCTOC_XIX_EXV3s_01_XIX_Klima_LIN2: start 53, 1 bit, little-endian, data-type-policy=OVERRIDE, i-signal-type=PRIMITIVE, init-value=1, base-type=BT_EXV3_Err_Blockierung_TNCTOC, compu {0=Cx0_DTC_test_completed_this_operation_cylce (CM_EXV3_Err_Blockierung_TNCTOC_Cx0_DTC_test_completed_this_operation_cylce), 1=Cx1_DTC_test_not_completed_this_operation_cylce (CM_EXV3_Err_Blockierung_TNCTOC_Cx1_DTC_test_not_completed_this_operation_cylce)}, range raw 0..1, transfer-property=PENDING, to Klima(timeout 3.5 s)  # OBD TestFailed Flag, Statusbotschaft für die elektrischen Kältemittelexpansionsventile
            signal EXV3_Err_RAMROMNADChange_TF_XIX_EXV3s_01_XIX_Klima_LIN2: start 54, 1 bit, little-endian, data-type-policy=OVERRIDE, i-signal-type=PRIMITIVE, base-type=BT_EXV3_Err_RAMROMNADChange_TF, compu {0=Cx0_passive (CM_EXV3_Err_RAMROMNADChange_TF_Cx0_passive), 1=Cx1_active (CM_EXV3_Err_RAMROMNADChange_TF_Cx1_active)}, range raw 0..1, transfer-property=PENDING, to Klima(timeout 3.5 s)  # OBD TestFailed Flag, Statusbotschaft für die elektrischen Kältemittelexpansionsventile
            signal EXV3_Err_RAMROMNADChange_TNCTOC_XIX_EXV3s_01_XIX_Klima_LIN2: start 55, 1 bit, little-endian, data-type-policy=OVERRIDE, i-signal-type=PRIMITIVE, init-value=1, base-type=BT_EXV3_Err_RAMROMNADChange_TNCTOC, compu {0=Cx0_DTC_test_completed_this_operation_cylce (CM_EXV3_Err_RAMROMNADChange_TNCTOC_Cx0_DTC_test_completed_this_operation_cylce), 1=Cx1_DTC_test_not_completed_this_operation_cylce (CM_EXV3_Err_RAMROMNADChange_TNCTOC_Cx1_DTC_test_not_completed_this_operation_cylce)}, range raw 0..1, transfer-property=PENDING, to Klima(timeout 3.5 s)  # OBD TestFailed Flag, Statusbotschaft für die elektrischen Kältemittelexpansionsventile
            signal EXV3_Err_Notlaufpos_TF_XIX_EXV3s_01_XIX_Klima_LIN2: start 56, 1 bit, little-endian, data-type-policy=OVERRIDE, i-signal-type=PRIMITIVE, base-type=BT_EXV3_Err_Notlaufpos_TF, compu {0=Cx0_passive (CM_EXV3_Err_Notlaufpos_TF_Cx0_passive), 1=Cx1_active (CM_EXV3_Err_Notlaufpos_TF_Cx1_active)}, range raw 0..1, transfer-property=PENDING, to Klima(timeout 3.5 s)  # OBD TestFailed Flag, Statusbotschaft für die elektrischen Kältemittelexpansionsventile
            signal EXV3_Err_Notlaufpos_TNCTOC_XIX_EXV3s_01_XIX_Klima_LIN2: start 57, 1 bit, little-endian, data-type-policy=OVERRIDE, i-signal-type=PRIMITIVE, init-value=1, base-type=BT_EXV3_Err_Notlaufpos_TNCTOC, compu {0=Cx0_DTC_test_completed_this_operation_cylce (CM_EXV3_Err_Notlaufpos_TNCTOC_Cx0_DTC_test_completed_this_operation_cylce), 1=Cx1_DTC_test_not_completed_this_operation_cylce (CM_EXV3_Err_Notlaufpos_TNCTOC_Cx1_DTC_test_not_completed_this_operation_cylce)}, range raw 0..1, transfer-property=PENDING, to Klima(timeout 3.5 s)  # OBD TestFailed Flag, Statusbotschaft für die elektrischen Kältemittelexpansionsventile
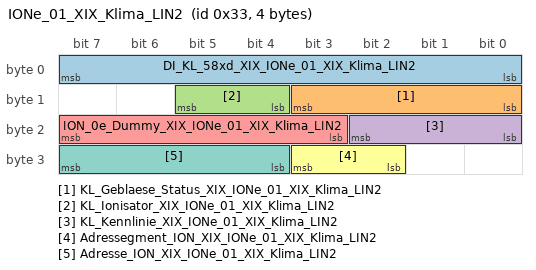
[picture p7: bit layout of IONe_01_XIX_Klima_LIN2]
        frame IONe_01_XIX_Klima_LIN2: id 0x33, from Klima, frame-length=4, lin-checksum=ENHANCED
          pdu IONe_01_XIX_Klima_LIN2: length=4, unused-bit-pattern=0
            signal DI_KL_58xd_XIX_IONe_01_XIX_Klima_LIN2: start 0, 8 bit, little-endian, data-type-policy=OVERRIDE, i-signal-type=PRIMITIVE, init-value=254, base-type=BT_DI_KL_58xd, invalid-value=Invalid_DI_KL_58xd_XIX_IONe_01_XIX_Klima_LIN2:255, compu {phys=raw for raw 0..253, 254=Cxfe_Init (CM_DI_KL_58xd_Cxfe_Init), 255=Cxff_Fehler (CM_DI_KL_58xd_Cxff_Fehler)}, range phys 0..253, raw 0..255, transfer-property=PENDING  # Klemme 58xd Display- und Funktionsbeleuchtung Mit der Klemme 58xd wird die Helligkeit der Display- und der Funktionsbeleuchtungen der Schalter gesteuert. Im Detail beschrieben im 'Funktionslastenheft Dimmung MQB'.
            signal KL_Geblaese_Status_XIX_IONe_01_XIX_Klima_LIN2: start 8, 4 bit, little-endian, data-type-policy=OVERRIDE, i-signal-type=PRIMITIVE, init-value=14, base-type=BT_KL_Geblaese_Status, invalid-value=Invalid_KL_Geblaese_Status_XIX_IONe_01_XIX_Klima_LIN2:15, compu {0=Cx0_Geblaese_aus (CM_KL_Geblaese_Status_Cx0_Geblaese_aus), 1=Cx1_Geblaesestufe_10 (CM_KL_Geblaese_Status_Cx1_Geblaesestufe_10), 2=Cx2_Geblaesestufe_20 (CM_KL_Geblaese_Status_Cx2_Geblaesestufe_20), 3=Cx3_Geblaesestufe_30 (CM_KL_Geblaese_Status_Cx3_Geblaesestufe_30), 4=Cx4_Geblaesestufe_40 (CM_KL_Geblaese_Status_Cx4_Geblaesestufe_40), 5=Cx5_Geblaesestufe_50 (CM_KL_Geblaese_Status_Cx5_Geblaesestufe_50), 6=Cx6_Geblaesestufe_60 (CM_KL_Geblaese_Status_Cx6_Geblaesestufe_60), 7=Cx7_Geblaesestufe_70 (CM_KL_Geblaese_Status_Cx7_Geblaesestufe_70), 8=Cx8_Geblaesestufe_80 (CM_KL_Geblaese_Status_Cx8_Geblaesestufe_80), 9=Cx9_Geblaesestufe_90 (CM_KL_Geblaese_Status_Cx9_Geblaesestufe_90), 10=Cxa_Geblaesestufe_100 (CM_KL_Geblaese_Status_Cxa_Geblaesestufe_100), 14=Cxe_Init (CM_KL_Geblaese_Status_Cxe_Init), 15=Cxf_Fehler (CM_KL_Geblaese_Status_Cxf_Fehler)}, range raw 0..15, transfer-property=PENDING  # Status Geblaese
            signal KL_Ionisator_XIX_IONe_01_XIX_Klima_LIN2: start 12, 2 bit, little-endian, data-type-policy=OVERRIDE, i-signal-type=PRIMITIVE, init-value=2, base-type=BT_KL_Ionisator, compu {0=Cx0_Ionisator_Startzustand_aus (CM_KL_Ionisator_Cx0_Ionisator_Startzustand_aus), 1=Cx1_Ionisator_Startzustand_ein (CM_KL_Ionisator_Cx1_Ionisator_Startzustand_ein), 2=Cx2_Init (CM_KL_Ionisator_Cx2_Init)}, range raw 0..2, transfer-property=PENDING  # Wunsch Betriebsart nach KL 15 ein 0 = Ionsiator ist als Startzustand ausgeschaltet 1 = Ionsiator ist als Startzustand eingeschaltet 2 = Init
            signal KL_Kennlinie_XIX_IONe_01_XIX_Klima_LIN2: start 16, 3 bit, little-endian, data-type-policy=OVERRIDE, i-signal-type=PRIMITIVE, init-value=0, base-type=BT_KL_Kennlinie, compu {0=Cx0_Ionisator_Kennlinie_0 (CM_KL_Kennlinie_Cx0_Ionisator_Kennlinie_0), 1=Cx1_Ionisator_Kennlinie_1 (CM_KL_Kennlinie_Cx1_Ionisator_Kennlinie_1), 2=Cx2_Ionisator_Kennlinie_2 (CM_KL_Kennlinie_Cx2_Ionisator_Kennlinie_2), 3=Cx3_Ionisator_Kennlinie_3 (CM_KL_Kennlinie_Cx3_Ionisator_Kennlinie_3)}, range raw 0..3, transfer-property=PENDING  # Vorhalt zur Steuerung von Ionisator-Kennlinien
            signal ION_0e_Dummy_XIX_IONe_01_XIX_Klima_LIN2: start 19, 5 bit, little-endian, data-type-policy=OVERRIDE, i-signal-type=PRIMITIVE, init-value=0, base-type=BT_ION_0e_Dummy, transfer-property=PENDING  # Intialsierung mt 0 damit später eine Erweiterung um 1-Bit-Signale möglich ist
            signal Adressegment_ION_XIX_IONe_01_XIX_Klima_LIN2: start 26, 2 bit, little-endian, data-type-policy=OVERRIDE, i-signal-type=PRIMITIVE, init-value=3, base-type=BT_Adressegment_ION, compu {phys=raw for raw 0..3; unit Unit_None}, range phys 0..3 Unit_None, raw 0..3, unit=Unit_None, transfer-property=PENDING  # LIN Speicher lesen
            signal Adresse_ION_XIX_IONe_01_XIX_Klima_LIN2: start 28, 4 bit, little-endian, data-type-policy=OVERRIDE, i-signal-type=PRIMITIVE, init-value=15, base-type=BT_Adresse_ION, compu {phys=raw for raw 0..15; unit Unit_None}, range phys 0..15 Unit_None, raw 0..15, unit=Unit_None, transfer-property=PENDING  # LIN Speicher lesen
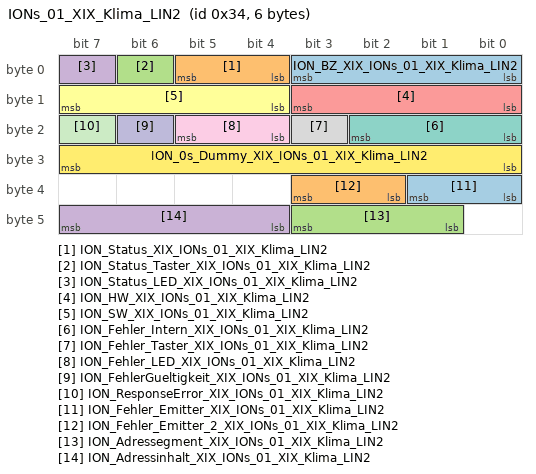
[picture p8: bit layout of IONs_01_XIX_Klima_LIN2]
        frame IONs_01_XIX_Klima_LIN2: id 0x34, to Klima, frame-length=6, lin-checksum=ENHANCED
          pdu IONs_01_XIX_Klima_LIN2: length=6, unused-bit-pattern=0
            signal ION_BZ_XIX_IONs_01_XIX_Klima_LIN2: start 0, 4 bit, little-endian, data-type-policy=OVERRIDE, i-signal-type=PRIMITIVE, base-type=BT_ION_BZ, compu {phys=raw for raw 0..15}, range phys 0..15, raw 0..15, transfer-property=PENDING, to Klima(timeout 3.5 s)  # 4bit-Botschaftszaehler, wird in jeder Sendebotschaft inkrementiert
            signal ION_Status_XIX_IONs_01_XIX_Klima_LIN2: start 4, 2 bit, little-endian, data-type-policy=OVERRIDE, i-signal-type=PRIMITIVE, init-value=2, base-type=BT_ION_Status, compu {0=Cx0_Hochspannung_ausgeschaltet (CM_ION_Status_Cx0_Hochspannung_ausgeschaltet), 1=Cx1_Hochspannung_eingeschaltet (CM_ION_Status_Cx1_Hochspannung_eingeschaltet), 2=Cx2_Init (CM_ION_Status_Cx2_Init)}, range raw 0..2, transfer-property=PENDING, to Klima(timeout 3.5 s)  # Status Hochspannung Ionisator
            signal ION_Status_Taster_XIX_IONs_01_XIX_Klima_LIN2: start 6, 1 bit, little-endian, data-type-policy=OVERRIDE, i-signal-type=PRIMITIVE, init-value=0, base-type=BT_ION_Status_Taster, compu {0=Cx0_nicht_betaetigt (CM_ION_Status_Taster_Cx0_nicht_betaetigt), 1=Cx1_betaetigt (CM_ION_Status_Taster_Cx1_betaetigt)}, range raw 0..1, transfer-property=PENDING, to Klima(timeout 3.5 s)  # Status Kundenwunsch (Bedientaster) Ionisator
            signal ION_Status_LED_XIX_IONs_01_XIX_Klima_LIN2: start 7, 1 bit, little-endian, data-type-policy=OVERRIDE, i-signal-type=PRIMITIVE, init-value=0, base-type=BT_ION_Status_LED, compu {0=Cx0_Aus (CM_ION_Status_LED_Cx0_Aus), 1=Cx1_Ein (CM_ION_Status_LED_Cx1_Ein)}, range raw 0..1, transfer-property=PENDING, to Klima(timeout 3.5 s)  # Status Funktions LED
            signal ION_HW_XIX_IONs_01_XIX_Klima_LIN2: start 8, 4 bit, little-endian, data-type-policy=OVERRIDE, i-signal-type=PRIMITIVE, init-value=0, base-type=BT_ION_HW, compu {phys=raw for raw 0..15}, range phys 0..15, raw 0..15, transfer-property=PENDING, to Klima(timeout 3.5 s)  # Hardwarestand
            signal ION_SW_XIX_IONs_01_XIX_Klima_LIN2: start 12, 4 bit, little-endian, data-type-policy=OVERRIDE, i-signal-type=PRIMITIVE, init-value=0, base-type=BT_ION_SW, compu {phys=raw for raw 0..15}, range phys 0..15, raw 0..15, transfer-property=PENDING, to Klima(timeout 3.5 s)  # Softwarestand
            signal ION_Fehler_Intern_XIX_IONs_01_XIX_Klima_LIN2: start 16, 3 bit, little-endian, data-type-policy=OVERRIDE, i-signal-type=PRIMITIVE, init-value=0, base-type=BT_ION_Fehler_Intern, compu {0=Cx0_kein_Fehler (CM_ION_Fehler_Intern_Cx0_kein_Fehler), 1=Cx1_RAM_ROM_Check_Fehler (CM_ION_Fehler_Intern_Cx1_RAM_ROM_Check_Fehler) (RAM/ROM Check Fehler), 2=Cx2_Fehler_in_Hochspannungserzeugung (CM_ION_Fehler_Intern_Cx2_Fehler_in_Hochspannungserzeugung), 4=Cx4_Watchdog_Reset (CM_ION_Fehler_Intern_Cx4_Watchdog_Reset)}, range raw 0..4, transfer-property=PENDING, to Klima(timeout 3.5 s)  # Ionisator interner Fehler (Mehrfachfehler möglich)
            signal ION_Fehler_Taster_XIX_IONs_01_XIX_Klima_LIN2: start 19, 1 bit, little-endian, data-type-policy=OVERRIDE, i-signal-type=PRIMITIVE, init-value=0, base-type=BT_ION_Fehler_Taster, compu {0=Cx0_kein_Fehler (CM_ION_Fehler_Taster_Cx0_kein_Fehler), 1=Cx1_Fehler (CM_ION_Fehler_Taster_Cx1_Fehler)}, range raw 0..1, transfer-property=PENDING, to Klima(timeout 3.5 s)  # Bedientasterfehler (z.B. Tastenklemmer)
            signal ION_Fehler_LED_XIX_IONs_01_XIX_Klima_LIN2: start 20, 2 bit, little-endian, data-type-policy=OVERRIDE, i-signal-type=PRIMITIVE, init-value=0, base-type=BT_ION_Fehler_LED, compu {0=Cx0_kein_Fehler (CM_ION_Fehler_LED_Cx0_kein_Fehler), 1=Cx1_Leitungsbruch (CM_ION_Fehler_LED_Cx1_Leitungsbruch), 2=Cx2_Kurzschluss (CM_ION_Fehler_LED_Cx2_Kurzschluss)}, range raw 0..2, transfer-property=PENDING, to Klima(timeout 3.5 s)
            signal ION_FehlerGueltigkeit_XIX_IONs_01_XIX_Klima_LIN2: start 22, 1 bit, little-endian, data-type-policy=OVERRIDE, i-signal-type=PRIMITIVE, init-value=0, base-type=BT_ION_FehlerGueltigkeit, compu {0=Cx0_Fehler_passiv_Fehlerpfad_nicht_durchlaufen (CM_ION_FehlerGueltigkeit_Cx0_Fehler_passiv_Fehlerpfad_nicht_durchlaufen) (Fehler_passiv__Fehlerpfad_nicht_durchlaufen), 1=Cx1_Fehler_gueltig_Fehlerpfad_durchlaufen (CM_ION_FehlerGueltigkeit_Cx1_Fehler_gueltig_Fehlerpfad_durchlaufen) (Fehler_gueltig__Fehlerpfad_durchlaufen)}, range raw 0..1, transfer-property=PENDING, to Klima(timeout 3.5 s)  # Gültigkeitsbit für - ION_Fehler_Intern - ION_Fehler_Taster - ION_Fehler_LED
            signal ION_ResponseError_XIX_IONs_01_XIX_Klima_LIN2: start 23, 1 bit, little-endian, data-type-policy=OVERRIDE, i-signal-type=PRIMITIVE, init-value=0, base-type=BT_ION_ResponseError, invalid-value=Invalid_ION_ResponseError_XIX_IONs_01_XIX_Klima_LIN2:1, compu {0=Cx0_normal (CM_ION_ResponseError_Cx0_normal), 1=Cx1_Fehler (CM_ION_ResponseError_Cx1_Fehler)}, range raw 0..1, transfer-property=PENDING, to Klima(timeout 3.5 s)  # siehe LIN2.0-Specification (Darf nicht über ein Fehlergueltigkeitsbit abgesichtert werden!)
            signal ION_0s_Dummy_XIX_IONs_01_XIX_Klima_LIN2: start 24, 8 bit, little-endian, data-type-policy=OVERRIDE, i-signal-type=PRIMITIVE, init-value=0, base-type=BT_ION_0s_Dummy, compu {0=Cx0_Init (CM_ION_0s_Dummy_Cx0_Init)}, range raw 0, transfer-property=PENDING, to Klima(timeout 3.5 s)  # Intialsierung mt 0 damit später eine Erweiterung um 1-Bit-Signale möglich ist
            signal ION_Fehler_Emitter_XIX_IONs_01_XIX_Klima_LIN2: start 32, 2 bit, little-endian, data-type-policy=OVERRIDE, i-signal-type=PRIMITIVE, init-value=0, base-type=BT_ION_Fehler_Emitter, compu {0=Cx0_kein_Fehler (CM_ION_Fehler_Emitter_Cx0_kein_Fehler), 1=Cx1_Emitter_niederohmig (CM_ION_Fehler_Emitter_Cx1_Emitter_niederohmig), 2=Cx2_Emitter_hochohmig (CM_ION_Fehler_Emitter_Cx2_Emitter_hochohmig)}, range raw 0..2, transfer-property=PENDING, to Klima(timeout 3.5 s)  # Fehlerstatus Emitter
            signal ION_Fehler_Emitter_2_XIX_IONs_01_XIX_Klima_LIN2: start 34, 2 bit, little-endian, data-type-policy=OVERRIDE, i-signal-type=PRIMITIVE, init-value=0, base-type=BT_ION_Fehler_Emitter_2, compu {0=Cx0_Init_kein_Fehler_Emitter (CM_ION_Fehler_Emitter_2_Cx0_Init_kein_Fehler_Emitter), 1=Cx1_Emitter_niederohmig (CM_ION_Fehler_Emitter_2_Cx1_Emitter_niederohmig), 2=Cx2_Emitter_hochohmig (CM_ION_Fehler_Emitter_2_Cx2_Emitter_hochohmig)}, range raw 0..2, transfer-property=PENDING, to Klima(timeout 3.5 s)  # Statusinformation AQI Emitter 2
            signal ION_Adressegment_XIX_IONs_01_XIX_Klima_LIN2: start 41, 3 bit, little-endian, data-type-policy=OVERRIDE, i-signal-type=PRIMITIVE, init-value=7, base-type=BT_ION_Adressegment, compu {7=Cx7_Init (CM_ION_Adressegment_Cx7_Init)}, range raw 7, transfer-property=PENDING, to Klima(timeout 3.5 s)  # LIN Speicher lesen
            signal ION_Adressinhalt_XIX_IONs_01_XIX_Klima_LIN2: start 44, 4 bit, little-endian, data-type-policy=OVERRIDE, i-signal-type=PRIMITIVE, init-value=15, base-type=BT_ION_Adressinhalt, compu {15=Cxf_Init (CM_ION_Adressinhalt_Cxf_Init)}, range raw 15, transfer-property=PENDING, to Klima(timeout 3.5 s)  # LIN Speicher lesen
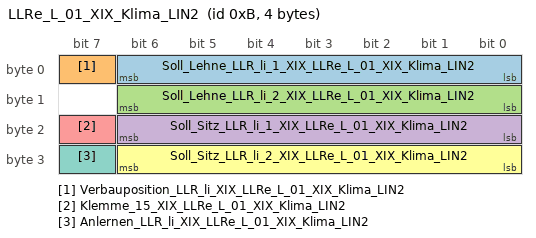
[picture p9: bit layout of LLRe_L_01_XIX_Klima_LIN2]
        frame LLRe_L_01_XIX_Klima_LIN2: id 0xB, from Klima, frame-length=4, lin-checksum=ENHANCED
          pdu LLRe_L_01_XIX_Klima_LIN2: length=4, unused-bit-pattern=0
            signal Soll_Lehne_LLR_li_1_XIX_LLRe_L_01_XIX_Klima_LIN2: start 0, 7 bit, little-endian, data-type-policy=OVERRIDE, i-signal-type=PRIMITIVE, init-value=0, base-type=BT_Soll_Lehne_LLR_li_1, compu {phys=raw for raw 0..100; unit Unit_PerCent}, range phys 0..100 Unit_PerCent, raw 0..100, unit=Unit_PerCent, transfer-property=PENDING  # Ansteuerung Sitzluefter PWM in %
            signal Verbauposition_LLR_li_XIX_LLRe_L_01_XIX_Klima_LIN2: start 7, 1 bit, little-endian, data-type-policy=OVERRIDE, i-signal-type=PRIMITIVE, base-type=BT_Verbauposition_LLR_li, compu {0=Cx0_vorne (CM_Verbauposition_LLR_li_Cx0_vorne), 1=Cx1_hinten (CM_Verbauposition_LLR_li_Cx1_hinten)}, range raw 0..1, transfer-property=PENDING  # Verbauposition vorne/hinten für eindeutige Diagnose/Identifikation. Signal für hinten ist immer 0x1, Signal für vorne ist immer 0x0.
            signal Soll_Lehne_LLR_li_2_XIX_LLRe_L_01_XIX_Klima_LIN2: start 8, 7 bit, little-endian, data-type-policy=OVERRIDE, i-signal-type=PRIMITIVE, init-value=0, base-type=BT_Soll_Lehne_LLR_li_2, compu {phys=raw for raw 0..100; unit Unit_PerCent}, range phys 0..100 Unit_PerCent, raw 0..100, unit=Unit_PerCent, transfer-property=PENDING  # Ansteuerung Sitzluefter PWM in %
            signal Soll_Sitz_LLR_li_1_XIX_LLRe_L_01_XIX_Klima_LIN2: start 16, 7 bit, little-endian, data-type-policy=OVERRIDE, i-signal-type=PRIMITIVE, init-value=0, base-type=BT_Soll_Sitz_LLR_li_1, compu {phys=raw for raw 0..100; unit Unit_PerCent}, range phys 0..100 Unit_PerCent, raw 0..100, unit=Unit_PerCent, transfer-property=PENDING  # Ansteuerung Sitzluefter PWM in %
            signal Klemme_15_XIX_LLRe_L_01_XIX_Klima_LIN2: start 23, 1 bit, little-endian, data-type-policy=OVERRIDE, i-signal-type=PRIMITIVE, init-value=0, base-type=BT_Klemme_15, compu {0=Cx0_Aus (CM_Klemme_15_Cx0_Aus), 1=Cx1_Ein (CM_Klemme_15_Cx1_Ein)}, range raw 0..1, transfer-property=PENDING
            signal Soll_Sitz_LLR_li_2_XIX_LLRe_L_01_XIX_Klima_LIN2: start 24, 7 bit, little-endian, data-type-policy=OVERRIDE, i-signal-type=PRIMITIVE, init-value=0, base-type=BT_Soll_Sitz_LLR_li_2, compu {phys=raw for raw 0..100; unit Unit_PerCent}, range phys 0..100 Unit_PerCent, raw 0..100, unit=Unit_PerCent, transfer-property=PENDING  # Ansteuerung Sitzluefter PWM in %
            signal Anlernen_LLR_li_XIX_LLRe_L_01_XIX_Klima_LIN2: start 31, 1 bit, little-endian, data-type-policy=OVERRIDE, i-signal-type=PRIMITIVE, init-value=0, base-type=BT_Anlernen_LLR_li, compu {0=Cx0_Init (CM_Anlernen_LLR_li_Cx0_Init), 1=Cx1_Adresse_lernen (CM_Anlernen_LLR_li_Cx1_Adresse_lernen)}, range raw 0..1, transfer-property=PENDING  # Triggersignale zum Anlernen der Slave SG abhängig vom CodierPin
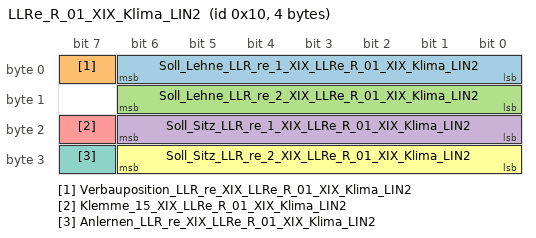
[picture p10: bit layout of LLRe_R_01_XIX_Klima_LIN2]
        frame LLRe_R_01_XIX_Klima_LIN2: id 0x10, from Klima, frame-length=4, lin-checksum=ENHANCED
          pdu LLRe_R_01_XIX_Klima_LIN2: length=4, unused-bit-pattern=0
            signal Soll_Lehne_LLR_re_1_XIX_LLRe_R_01_XIX_Klima_LIN2: start 0, 7 bit, little-endian, data-type-policy=OVERRIDE, i-signal-type=PRIMITIVE, init-value=0, base-type=BT_Soll_Lehne_LLR_re_1, compu {phys=raw for raw 0..100; unit Unit_PerCent}, range phys 0..100 Unit_PerCent, raw 0..100, unit=Unit_PerCent, transfer-property=PENDING  # Ansteuerung Sitzluefter PWM in %
            signal Verbauposition_LLR_re_XIX_LLRe_R_01_XIX_Klima_LIN2: start 7, 1 bit, little-endian, data-type-policy=OVERRIDE, i-signal-type=PRIMITIVE, base-type=BT_Verbauposition_LLR_re, compu {0=Cx0_vorne (CM_Verbauposition_LLR_re_Cx0_vorne), 1=Cx1_hinten (CM_Verbauposition_LLR_re_Cx1_hinten)}, range raw 0..1, transfer-property=PENDING  # Verbauposition vorne/hinten für eindeutige Diagnose/Identifikation. Signal für hinten ist immer 0x1, Signal für vorne ist immer 0x0.
            signal Soll_Lehne_LLR_re_2_XIX_LLRe_R_01_XIX_Klima_LIN2: start 8, 7 bit, little-endian, data-type-policy=OVERRIDE, i-signal-type=PRIMITIVE, init-value=0, base-type=BT_Soll_Lehne_LLR_re_2, compu {phys=raw for raw 0..100; unit Unit_PerCent}, range phys 0..100 Unit_PerCent, raw 0..100, unit=Unit_PerCent, transfer-property=PENDING  # Ansteuerung Sitzluefter PWM in %
            signal Soll_Sitz_LLR_re_1_XIX_LLRe_R_01_XIX_Klima_LIN2: start 16, 7 bit, little-endian, data-type-policy=OVERRIDE, i-signal-type=PRIMITIVE, init-value=0, base-type=BT_Soll_Sitz_LLR_re_1, compu {phys=raw for raw 0..100; unit Unit_PerCent}, range phys 0..100 Unit_PerCent, raw 0..100, unit=Unit_PerCent, transfer-property=PENDING  # Ansteuerung Sitzluefter PWM in %
            signal Klemme_15_XIX_LLRe_R_01_XIX_Klima_LIN2: start 23, 1 bit, little-endian, data-type-policy=OVERRIDE, i-signal-type=PRIMITIVE, init-value=0, base-type=BT_Klemme_15, compu {0=Cx0_Aus (CM_Klemme_15_Cx0_Aus), 1=Cx1_Ein (CM_Klemme_15_Cx1_Ein)}, range raw 0..1, transfer-property=PENDING
            signal Soll_Sitz_LLR_re_2_XIX_LLRe_R_01_XIX_Klima_LIN2: start 24, 7 bit, little-endian, data-type-policy=OVERRIDE, i-signal-type=PRIMITIVE, init-value=0, base-type=BT_Soll_Sitz_LLR_re_2, compu {phys=raw for raw 0..100; unit Unit_PerCent}, range phys 0..100 Unit_PerCent, raw 0..100, unit=Unit_PerCent, transfer-property=PENDING  # Ansteuerung Sitzluefter PWM in %
            signal Anlernen_LLR_re_XIX_LLRe_R_01_XIX_Klima_LIN2: start 31, 1 bit, little-endian, data-type-policy=OVERRIDE, i-signal-type=PRIMITIVE, init-value=0, base-type=BT_Anlernen_LLR_re, compu {0=Cx0_Init (CM_Anlernen_LLR_re_Cx0_Init), 1=Cx1_Adresse_lernen (CM_Anlernen_LLR_re_Cx1_Adresse_lernen)}, range raw 0..1, transfer-property=PENDING  # Triggersignale zum Anlernen der Slave SG abhängig vom CodierPin
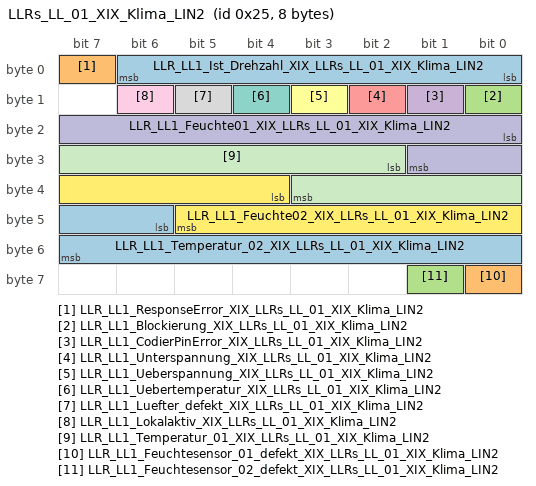
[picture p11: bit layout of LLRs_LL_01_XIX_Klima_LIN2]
        frame LLRs_LL_01_XIX_Klima_LIN2: id 0x25, to Klima, frame-length=8, lin-checksum=ENHANCED
          pdu LLRs_LL_01_XIX_Klima_LIN2: length=8, unused-bit-pattern=0
            signal LLR_LL1_Ist_Drehzahl_XIX_LLRs_LL_01_XIX_Klima_LIN2: start 0, 7 bit, little-endian, data-type-policy=OVERRIDE, i-signal-type=PRIMITIVE, init-value=0, base-type=BT_LLR_LL1_Ist_Drehzahl, compu {phys=raw for raw 0..100; unit Unit_PerCent}, range phys 0..100 Unit_PerCent, raw 0..100, unit=Unit_PerCent, transfer-property=PENDING, to Klima(timeout 3.5 s)  # Fehlende Beschreibung (Import)
            signal LLR_LL1_ResponseError_XIX_LLRs_LL_01_XIX_Klima_LIN2: start 7, 1 bit, little-endian, data-type-policy=OVERRIDE, i-signal-type=PRIMITIVE, init-value=0, base-type=BT_LLR_LL1_ResponseError, invalid-value=Invalid_LLR_LL1_ResponseError_XIX_LLRs_LL_01_XIX_Klima_LIN2:1, compu {0=Cx0_normal (CM_LLR_LL1_ResponseError_Cx0_normal), 1=Cx1_Fehler (CM_LLR_LL1_ResponseError_Cx1_Fehler)}, range raw 0..1, transfer-property=PENDING, to Klima(timeout 3.5 s)  # siehe LIN2.0-Specification (Darf nicht über ein Fehlergueltigkeitsbit abgesichtert werden!)
            signal LLR_LL1_Blockierung_XIX_LLRs_LL_01_XIX_Klima_LIN2: start 8, 1 bit, little-endian, data-type-policy=OVERRIDE, i-signal-type=PRIMITIVE, init-value=0, base-type=BT_LLR_LL1_Blockierung, compu {0=Cx0_kein_Fehler (CM_LLR_LL1_Blockierung_Cx0_kein_Fehler), 1=Cx1_Blockierung_Kompressor_Fehler (CM_LLR_LL1_Blockierung_Cx1_Blockierung_Kompressor_Fehler)}, range raw 0..1, transfer-property=PENDING, to Klima(timeout 3.5 s)  # Blockierung des Lüfters erkannt Geforderte Solldrehzahl kann nicht erreicht werden
            signal LLR_LL1_CodierPinError_XIX_LLRs_LL_01_XIX_Klima_LIN2: start 9, 1 bit, little-endian, data-type-policy=OVERRIDE, i-signal-type=PRIMITIVE, init-value=0, base-type=BT_LLR_LL1_CodierPinError, compu {0=Cx0_kein_Fehler (CM_LLR_LL1_CodierPinError_Cx0_kein_Fehler), 1=Cx1_HW_Codierung_Fehler (CM_LLR_LL1_CodierPinError_Cx1_HW_Codierung_Fehler)}, range raw 0..1, transfer-property=PENDING, to Klima(timeout 3.5 s)  # Fehlende Beschreibung (Import)
            signal LLR_LL1_Unterspannung_XIX_LLRs_LL_01_XIX_Klima_LIN2: start 10, 1 bit, little-endian, data-type-policy=OVERRIDE, i-signal-type=PRIMITIVE, init-value=0, base-type=BT_LLR_LL1_Unterspannung, invalid-value=Invalid_LLR_LL1_Unterspannung_XIX_LLRs_LL_01_XIX_Klima_LIN2:1, compu {0=Cx0_normal (CM_LLR_LL1_Unterspannung_Cx0_normal), 1=Cx1_Fehler (CM_LLR_LL1_Unterspannung_Cx1_Fehler)}, range raw 0..1, transfer-property=PENDING, to Klima(timeout 3.5 s)  # Fehlende Beschreibung (Import)
            signal LLR_LL1_Ueberspannung_XIX_LLRs_LL_01_XIX_Klima_LIN2: start 11, 1 bit, little-endian, data-type-policy=OVERRIDE, i-signal-type=PRIMITIVE, init-value=0, base-type=BT_LLR_LL1_Ueberspannung, invalid-value=Invalid_LLR_LL1_Ueberspannung_XIX_LLRs_LL_01_XIX_Klima_LIN2:1, compu {0=Cx0_normal (CM_LLR_LL1_Ueberspannung_Cx0_normal), 1=Cx1_Fehler (CM_LLR_LL1_Ueberspannung_Cx1_Fehler)}, range raw 0..1, transfer-property=PENDING, to Klima(timeout 3.5 s)  # Fehlende Beschreibung (Import)
            signal LLR_LL1_Uebertemperatur_XIX_LLRs_LL_01_XIX_Klima_LIN2: start 12, 1 bit, little-endian, data-type-policy=OVERRIDE, i-signal-type=PRIMITIVE, init-value=0, base-type=BT_LLR_LL1_Uebertemperatur, invalid-value=Invalid_LLR_LL1_Uebertemperatur_XIX_LLRs_LL_01_XIX_Klima_LIN2:1, compu {0=Cx0_normal (CM_LLR_LL1_Uebertemperatur_Cx0_normal), 1=Cx1_Fehler (CM_LLR_LL1_Uebertemperatur_Cx1_Fehler)}, range raw 0..1, transfer-property=PENDING, to Klima(timeout 3.5 s)  # Fehlende Beschreibung (Import)
            signal LLR_LL1_Luefter_defekt_XIX_LLRs_LL_01_XIX_Klima_LIN2: start 13, 1 bit, little-endian, data-type-policy=OVERRIDE, i-signal-type=PRIMITIVE, init-value=0, base-type=BT_LLR_LL1_Luefter_defekt, compu {0=Cx0_Luefter_iO (CM_LLR_LL1_Luefter_defekt_Cx0_Luefter_iO), 1=Cx1_Luefter_defekt (CM_LLR_LL1_Luefter_defekt_Cx1_Luefter_defekt)}, range raw 0..1, transfer-property=PENDING, to Klima(timeout 3.5 s)  # interner Lüfterdefekt erkannt der zu einem Tausch der BG swingt
            signal LLR_LL1_Lokalaktiv_XIX_LLRs_LL_01_XIX_Klima_LIN2: start 14, 1 bit, little-endian, data-type-policy=OVERRIDE, i-signal-type=PRIMITIVE, init-value=0, base-type=BT_LLR_LL1_Lokalaktiv, compu {0=Cx0_war_nicht_lokal_aktiv (CM_LLR_LL1_Lokalaktiv_Cx0_war_nicht_lokal_aktiv), 1=Cx1_war_lokal_aktiv (CM_LLR_LL1_Lokalaktiv_Cx1_war_lokal_aktiv)}, range raw 0..1, transfer-property=PENDING, to Klima(timeout 3.5 s)  # Lüfter war im letzten Sleepmodus lokal aktiv (Nachtlauffunktion)
            signal LLR_LL1_Feuchte01_XIX_LLRs_LL_01_XIX_Klima_LIN2: start 16, 10 bit, little-endian, data-type-policy=OVERRIDE, i-signal-type=PRIMITIVE, init-value=1022, base-type=BT_LLR_LL1_Feuchte01, invalid-value=Invalid_LLR_LL1_Feuchte01_XIX_LLRs_LL_01_XIX_Klima_LIN2:1023, compu {phys=raw*0.1000000015 for raw 0..1021, 1022=Cx3fe_Init (CM_LLR_LL1_Feuchte01_Cx3fe_Init), 1023=Cx3ff_Fehler (CM_LLR_LL1_Feuchte01_Cx3ff_Fehler); unit Unit_PerCent}, range phys 0..102.10000152140856 Unit_PerCent, raw 0..1023, unit=Unit_PerCent, transfer-property=PENDING, to Klima(timeout 3.5 s)  # Vom Sensor01 gemessene relative Feuchte
            signal LLR_LL1_Temperatur_01_XIX_LLRs_LL_01_XIX_Klima_LIN2: start 26, 10 bit, little-endian, data-type-policy=OVERRIDE, i-signal-type=PRIMITIVE, init-value=1022, base-type=BT_LLR_LL1_Temperatur_01, invalid-value=Invalid_LLR_LL1_Temperatur_01_XIX_LLRs_LL_01_XIX_Klima_LIN2:1023, compu {phys=raw*0.1000000015-40 for raw 0..1019, 1020=Cx3fc_Temperatur_unter_40_C (CM_LLR_LL1_Temperatur_01_Cx3fc_Temperatur_unter_40_C) (Temperatur_unter_-40°C), 1021=Cx3fd_Temperatur_ueber_60_C (CM_LLR_LL1_Temperatur_01_Cx3fd_Temperatur_ueber_60_C) (Temperatur_über_+60°C), 1022=Cx3fe_Init (CM_LLR_LL1_Temperatur_01_Cx3fe_Init), 1023=Cx3ff_Fehler (CM_LLR_LL1_Temperatur_01_Cx3ff_Fehler); unit Unit_DegreCelsi}, range phys -40..61.900001518428326 Unit_DegreCelsi, raw 0..1023, unit=Unit_DegreCelsi, transfer-property=PENDING, to Klima(timeout 3.5 s)  # Vom Sensor01 gemessene Temperatur
            signal LLR_LL1_Feuchte02_XIX_LLRs_LL_01_XIX_Klima_LIN2: start 36, 10 bit, little-endian, data-type-policy=OVERRIDE, i-signal-type=PRIMITIVE, init-value=1022, base-type=BT_LLR_LL1_Feuchte02, invalid-value=Invalid_LLR_LL1_Feuchte02_XIX_LLRs_LL_01_XIX_Klima_LIN2:1023, compu {phys=raw*0.1000000015 for raw 0..1021, 1022=Cx3fe_Init (CM_LLR_LL1_Feuchte02_Cx3fe_Init), 1023=Cx3ff_Fehler (CM_LLR_LL1_Feuchte02_Cx3ff_Fehler); unit Unit_PerCent}, range phys 0..102.10000152140856 Unit_PerCent, raw 0..1023, unit=Unit_PerCent, transfer-property=PENDING, to Klima(timeout 3.5 s)  # Vom Sensor02 gemessene relative Feuchte
            signal LLR_LL1_Temperatur_02_XIX_LLRs_LL_01_XIX_Klima_LIN2: start 46, 10 bit, little-endian, data-type-policy=OVERRIDE, i-signal-type=PRIMITIVE, init-value=1022, base-type=BT_LLR_LL1_Temperatur_02, invalid-value=Invalid_LLR_LL1_Temperatur_02_XIX_LLRs_LL_01_XIX_Klima_LIN2:1023, compu {phys=raw*0.1000000015-40 for raw 0..1019, 1020=Cx3fc_Temperatur_unter_40_C (CM_LLR_LL1_Temperatur_02_Cx3fc_Temperatur_unter_40_C) (Temperatur_unter_-40°C), 1021=Cx3fd_Temperatur_ueber_60_C (CM_LLR_LL1_Temperatur_02_Cx3fd_Temperatur_ueber_60_C) (Temperatur_über_+60°C), 1022=Cx3fe_Init (CM_LLR_LL1_Temperatur_02_Cx3fe_Init), 1023=Cx3ff_Fehler (CM_LLR_LL1_Temperatur_02_Cx3ff_Fehler); unit Unit_DegreCelsi}, range phys -40..61.900001518428326 Unit_DegreCelsi, raw 0..1023, unit=Unit_DegreCelsi, transfer-property=PENDING, to Klima(timeout 3.5 s)  # Vom Sensor02 gemessene Temperatur
            signal LLR_LL1_Feuchtesensor_01_defekt_XIX_LLRs_LL_01_XIX_Klima_LIN2: start 56, 1 bit, little-endian, data-type-policy=OVERRIDE, i-signal-type=PRIMITIVE, init-value=0, base-type=BT_LLR_LL1_Feuchtesensor_01_defekt, compu {0=Cx0_Sensor_iO (CM_LLR_LL1_Feuchtesensor_01_defekt_Cx0_Sensor_iO), 1=Cx1_Sensor_defekt (CM_LLR_LL1_Feuchtesensor_01_defekt_Cx1_Sensor_defekt)}, range raw 0..1, transfer-property=PENDING, to Klima(timeout 3.5 s)  # Fehlfunktion des angeschlossenen externen Feuchtesensors 01 erkannt
            signal LLR_LL1_Feuchtesensor_02_defekt_XIX_LLRs_LL_01_XIX_Klima_LIN2: start 57, 1 bit, little-endian, data-type-policy=OVERRIDE, i-signal-type=PRIMITIVE, init-value=0, base-type=BT_LLR_LL1_Feuchtesensor_02_defekt, compu {0=Cx0_Sensor_iO (CM_LLR_LL1_Feuchtesensor_02_defekt_Cx0_Sensor_iO), 1=Cx1_Sensor_defekt (CM_LLR_LL1_Feuchtesensor_02_defekt_Cx1_Sensor_defekt)}, range raw 0..1, transfer-property=PENDING, to Klima(timeout 3.5 s)  # (Description too short)
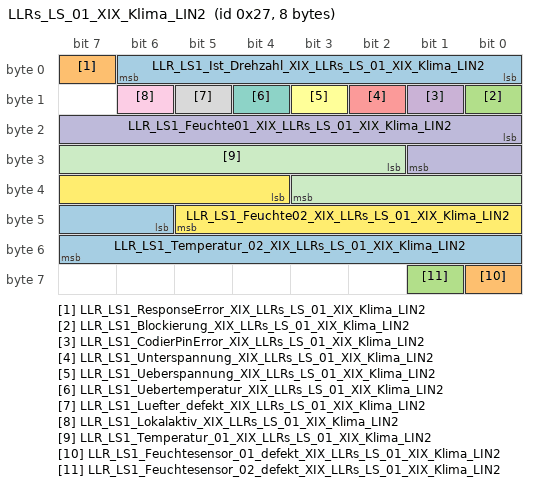
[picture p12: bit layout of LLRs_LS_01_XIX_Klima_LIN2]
        frame LLRs_LS_01_XIX_Klima_LIN2: id 0x27, to Klima, frame-length=8, lin-checksum=ENHANCED
          pdu LLRs_LS_01_XIX_Klima_LIN2: length=8, unused-bit-pattern=0
            signal LLR_LS1_Ist_Drehzahl_XIX_LLRs_LS_01_XIX_Klima_LIN2: start 0, 7 bit, little-endian, data-type-policy=OVERRIDE, i-signal-type=PRIMITIVE, init-value=0, base-type=BT_LLR_LS1_Ist_Drehzahl, compu {phys=raw for raw 0..100; unit Unit_PerCent}, range phys 0..100 Unit_PerCent, raw 0..100, unit=Unit_PerCent, transfer-property=PENDING, to Klima(timeout 3.5 s)  # Aktuelle Istdrehzahl [%] in Bezug auf Maximalwert
            signal LLR_LS1_ResponseError_XIX_LLRs_LS_01_XIX_Klima_LIN2: start 7, 1 bit, little-endian, data-type-policy=OVERRIDE, i-signal-type=PRIMITIVE, init-value=0, base-type=BT_LLR_LS1_ResponseError, invalid-value=Invalid_LLR_LS1_ResponseError_XIX_LLRs_LS_01_XIX_Klima_LIN2:1, compu {0=Cx0_normal (CM_LLR_LS1_ResponseError_Cx0_normal), 1=Cx1_Fehler (CM_LLR_LS1_ResponseError_Cx1_Fehler)}, range raw 0..1, transfer-property=PENDING, to Klima(timeout 3.5 s)  # siehe LIN2.0-Specification (Darf nicht über ein Fehlergueltigkeitsbit abgesichtert werden!)
            signal LLR_LS1_Blockierung_XIX_LLRs_LS_01_XIX_Klima_LIN2: start 8, 1 bit, little-endian, data-type-policy=OVERRIDE, i-signal-type=PRIMITIVE, init-value=0, base-type=BT_LLR_LS1_Blockierung, compu {0=Cx0_kein_Fehler (CM_LLR_LS1_Blockierung_Cx0_kein_Fehler), 1=Cx1_Blockierung_Kompressor_Fehler (CM_LLR_LS1_Blockierung_Cx1_Blockierung_Kompressor_Fehler)}, range raw 0..1, transfer-property=PENDING, to Klima(timeout 3.5 s)  # Fehlende Beschreibung (Import)
            signal LLR_LS1_CodierPinError_XIX_LLRs_LS_01_XIX_Klima_LIN2: start 9, 1 bit, little-endian, data-type-policy=OVERRIDE, i-signal-type=PRIMITIVE, init-value=0, base-type=BT_LLR_LS1_CodierPinError, compu {0=Cx0_kein_Fehler (CM_LLR_LS1_CodierPinError_Cx0_kein_Fehler), 1=Cx1_HW_Codierung_Fehler (CM_LLR_LS1_CodierPinError_Cx1_HW_Codierung_Fehler)}, range raw 0..1, transfer-property=PENDING, to Klima(timeout 3.5 s)  # Fehlende Beschreibung (Import)
            signal LLR_LS1_Unterspannung_XIX_LLRs_LS_01_XIX_Klima_LIN2: start 10, 1 bit, little-endian, data-type-policy=OVERRIDE, i-signal-type=PRIMITIVE, init-value=0, base-type=BT_LLR_LS1_Unterspannung, invalid-value=Invalid_LLR_LS1_Unterspannung_XIX_LLRs_LS_01_XIX_Klima_LIN2:1, compu {0=Cx0_normal (CM_LLR_LS1_Unterspannung_Cx0_normal), 1=Cx1_Fehler (CM_LLR_LS1_Unterspannung_Cx1_Fehler)}, range raw 0..1, transfer-property=PENDING, to Klima(timeout 3.5 s)  # lokal Unterspannung erkannt
            signal LLR_LS1_Ueberspannung_XIX_LLRs_LS_01_XIX_Klima_LIN2: start 11, 1 bit, little-endian, data-type-policy=OVERRIDE, i-signal-type=PRIMITIVE, init-value=0, base-type=BT_LLR_LS1_Ueberspannung, invalid-value=Invalid_LLR_LS1_Ueberspannung_XIX_LLRs_LS_01_XIX_Klima_LIN2:1, compu {0=Cx0_normal (CM_LLR_LS1_Ueberspannung_Cx0_normal), 1=Cx1_Fehler (CM_LLR_LS1_Ueberspannung_Cx1_Fehler)}, range raw 0..1, transfer-property=PENDING, to Klima(timeout 3.5 s)  # Fehlende Beschreibung (Import)
            signal LLR_LS1_Uebertemperatur_XIX_LLRs_LS_01_XIX_Klima_LIN2: start 12, 1 bit, little-endian, data-type-policy=OVERRIDE, i-signal-type=PRIMITIVE, init-value=0, base-type=BT_LLR_LS1_Uebertemperatur, invalid-value=Invalid_LLR_LS1_Uebertemperatur_XIX_LLRs_LS_01_XIX_Klima_LIN2:1, compu {0=Cx0_normal (CM_LLR_LS1_Uebertemperatur_Cx0_normal), 1=Cx1_Fehler (CM_LLR_LS1_Uebertemperatur_Cx1_Fehler)}, range raw 0..1, transfer-property=PENDING, to Klima(timeout 3.5 s)  # intern gemessene Baugruppentemperatur liegt ausserhalb des zulässigen Bereichs
            signal LLR_LS1_Luefter_defekt_XIX_LLRs_LS_01_XIX_Klima_LIN2: start 13, 1 bit, little-endian, data-type-policy=OVERRIDE, i-signal-type=PRIMITIVE, init-value=0, base-type=BT_LLR_LS1_Luefter_defekt, compu {0=Cx0_Luefter_iO (CM_LLR_LS1_Luefter_defekt_Cx0_Luefter_iO), 1=Cx1_Luefter_defekt (CM_LLR_LS1_Luefter_defekt_Cx1_Luefter_defekt)}, range raw 0..1, transfer-property=PENDING, to Klima(timeout 3.5 s)  # interner Lüfterdefekt erkannt der zu einem Tausch der BG swingt
            signal LLR_LS1_Lokalaktiv_XIX_LLRs_LS_01_XIX_Klima_LIN2: start 14, 1 bit, little-endian, data-type-policy=OVERRIDE, i-signal-type=PRIMITIVE, init-value=0, base-type=BT_LLR_LS1_Lokalaktiv, compu {0=Cx0_war_nicht_lokal_aktiv (CM_LLR_LS1_Lokalaktiv_Cx0_war_nicht_lokal_aktiv), 1=Cx1_war_lokal_aktiv (CM_LLR_LS1_Lokalaktiv_Cx1_war_lokal_aktiv)}, range raw 0..1, transfer-property=PENDING, to Klima(timeout 3.5 s)  # Lüfter war im letzten Sleepmodus lokal aktiv (Nachtlauffunktion)
            signal LLR_LS1_Feuchte01_XIX_LLRs_LS_01_XIX_Klima_LIN2: start 16, 10 bit, little-endian, data-type-policy=OVERRIDE, i-signal-type=PRIMITIVE, init-value=1022, base-type=BT_LLR_LS1_Feuchte01, invalid-value=Invalid_LLR_LS1_Feuchte01_XIX_LLRs_LS_01_XIX_Klima_LIN2:1023, compu {phys=raw*0.1000000015 for raw 0..1021, 1022=Cx3fe_Init (CM_LLR_LS1_Feuchte01_Cx3fe_Init), 1023=Cx3ff_Fehler (CM_LLR_LS1_Feuchte01_Cx3ff_Fehler); unit Unit_PerCent}, range phys 0..102.10000152140856 Unit_PerCent, raw 0..1023, unit=Unit_PerCent, transfer-property=PENDING, to Klima(timeout 3.5 s)  # Vom Sensor01 gemessene relative Feuchte
            signal LLR_LS1_Temperatur_01_XIX_LLRs_LS_01_XIX_Klima_LIN2: start 26, 10 bit, little-endian, data-type-policy=OVERRIDE, i-signal-type=PRIMITIVE, init-value=1022, base-type=BT_LLR_LS1_Temperatur_01, invalid-value=Invalid_LLR_LS1_Temperatur_01_XIX_LLRs_LS_01_XIX_Klima_LIN2:1023, compu {phys=raw*0.1000000015-40 for raw 0..1019, 1020=Cx3fc_Temperatur_unter_40_C (CM_LLR_LS1_Temperatur_01_Cx3fc_Temperatur_unter_40_C) (Temperatur_unter_-40°C), 1021=Cx3fd_Temperatur_ueber_60_C (CM_LLR_LS1_Temperatur_01_Cx3fd_Temperatur_ueber_60_C) (Temperatur_über_+60°C), 1022=Cx3fe_Init (CM_LLR_LS1_Temperatur_01_Cx3fe_Init), 1023=Cx3ff_Fehler (CM_LLR_LS1_Temperatur_01_Cx3ff_Fehler); unit Unit_DegreCelsi}, range phys -40..61.900001518428326 Unit_DegreCelsi, raw 0..1023, unit=Unit_DegreCelsi, transfer-property=PENDING, to Klima(timeout 3.5 s)  # Vom Sensor01 gemessene Temperatur
            signal LLR_LS1_Feuchte02_XIX_LLRs_LS_01_XIX_Klima_LIN2: start 36, 10 bit, little-endian, data-type-policy=OVERRIDE, i-signal-type=PRIMITIVE, init-value=1022, base-type=BT_LLR_LS1_Feuchte02, invalid-value=Invalid_LLR_LS1_Feuchte02_XIX_LLRs_LS_01_XIX_Klima_LIN2:1023, compu {phys=raw*0.1000000015 for raw 0..1021, 1022=Cx3fe_Init (CM_LLR_LS1_Feuchte02_Cx3fe_Init), 1023=Cx3ff_Fehler (CM_LLR_LS1_Feuchte02_Cx3ff_Fehler); unit Unit_PerCent}, range phys 0..102.10000152140856 Unit_PerCent, raw 0..1023, unit=Unit_PerCent, transfer-property=PENDING, to Klima(timeout 3.5 s)  # Vom Sensor02 gemessene relative Feuchte
            signal LLR_LS1_Temperatur_02_XIX_LLRs_LS_01_XIX_Klima_LIN2: start 46, 10 bit, little-endian, data-type-policy=OVERRIDE, i-signal-type=PRIMITIVE, init-value=1022, base-type=BT_LLR_LS1_Temperatur_02, invalid-value=Invalid_LLR_LS1_Temperatur_02_XIX_LLRs_LS_01_XIX_Klima_LIN2:1023, compu {phys=raw*0.1000000015-40 for raw 0..1019, 1020=Cx3fc_Temperatur_unter_40_C (CM_LLR_LS1_Temperatur_02_Cx3fc_Temperatur_unter_40_C) (Temperatur_unter_-40°C), 1021=Cx3fd_Temperatur_ueber_60_C (CM_LLR_LS1_Temperatur_02_Cx3fd_Temperatur_ueber_60_C) (Temperatur_über_+60°C), 1022=Cx3fe_Init (CM_LLR_LS1_Temperatur_02_Cx3fe_Init), 1023=Cx3ff_Fehler (CM_LLR_LS1_Temperatur_02_Cx3ff_Fehler); unit Unit_DegreCelsi}, range phys -40..61.900001518428326 Unit_DegreCelsi, raw 0..1023, unit=Unit_DegreCelsi, transfer-property=PENDING, to Klima(timeout 3.5 s)  # Vom Sensor02 gemessene Temperatur
            signal LLR_LS1_Feuchtesensor_01_defekt_XIX_LLRs_LS_01_XIX_Klima_LIN2: start 56, 1 bit, little-endian, data-type-policy=OVERRIDE, i-signal-type=PRIMITIVE, init-value=0, base-type=BT_LLR_LS1_Feuchtesensor_01_defekt, compu {0=Cx0_Sensor_iO (CM_LLR_LS1_Feuchtesensor_01_defekt_Cx0_Sensor_iO), 1=Cx1_Sensor_defekt (CM_LLR_LS1_Feuchtesensor_01_defekt_Cx1_Sensor_defekt)}, range raw 0..1, transfer-property=PENDING, to Klima(timeout 3.5 s)  # Fehlfunktion des angeschlossenen externen Feuchtesensors 01 erkannt
            signal LLR_LS1_Feuchtesensor_02_defekt_XIX_LLRs_LS_01_XIX_Klima_LIN2: start 57, 1 bit, little-endian, data-type-policy=OVERRIDE, i-signal-type=PRIMITIVE, init-value=0, base-type=BT_LLR_LS1_Feuchtesensor_02_defekt, compu {0=Cx0_Sensor_iO (CM_LLR_LS1_Feuchtesensor_02_defekt_Cx0_Sensor_iO), 1=Cx1_Sensor_defekt (CM_LLR_LS1_Feuchtesensor_02_defekt_Cx1_Sensor_defekt)}, range raw 0..1, transfer-property=PENDING, to Klima(timeout 3.5 s)  # Status Feuchtesensor02
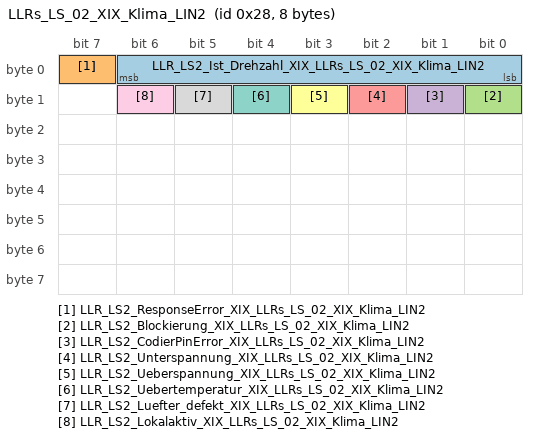
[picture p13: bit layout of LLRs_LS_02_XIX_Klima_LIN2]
        frame LLRs_LS_02_XIX_Klima_LIN2: id 0x28, to Klima, frame-length=8, lin-checksum=ENHANCED
          pdu LLRs_LS_02_XIX_Klima_LIN2: length=8, unused-bit-pattern=0
            signal LLR_LS2_Ist_Drehzahl_XIX_LLRs_LS_02_XIX_Klima_LIN2: start 0, 7 bit, little-endian, data-type-policy=OVERRIDE, i-signal-type=PRIMITIVE, init-value=0, base-type=BT_LLR_LS2_Ist_Drehzahl, compu {phys=raw for raw 0..100; unit Unit_PerCent}, range phys 0..100 Unit_PerCent, raw 0..100, unit=Unit_PerCent, transfer-property=PENDING, to Klima(timeout 3.5 s)  # Aktuelle Istdrehzahl [%] in Bezug auf Maximalwert
            signal LLR_LS2_ResponseError_XIX_LLRs_LS_02_XIX_Klima_LIN2: start 7, 1 bit, little-endian, data-type-policy=OVERRIDE, i-signal-type=PRIMITIVE, init-value=0, base-type=BT_LLR_LS2_ResponseError, invalid-value=Invalid_LLR_LS2_ResponseError_XIX_LLRs_LS_02_XIX_Klima_LIN2:1, compu {0=Cx0_normal (CM_LLR_LS2_ResponseError_Cx0_normal), 1=Cx1_Fehler (CM_LLR_LS2_ResponseError_Cx1_Fehler)}, range raw 0..1, transfer-property=PENDING, to Klima(timeout 3.5 s)  # siehe LIN2.0-Specification (Darf nicht über ein Fehlergueltigkeitsbit abgesichtert werden!)
            signal LLR_LS2_Blockierung_XIX_LLRs_LS_02_XIX_Klima_LIN2: start 8, 1 bit, little-endian, data-type-policy=OVERRIDE, i-signal-type=PRIMITIVE, init-value=0, base-type=BT_LLR_LS2_Blockierung, compu {0=Cx0_kein_Fehler (CM_LLR_LS2_Blockierung_Cx0_kein_Fehler), 1=Cx1_Blockierung_Kompressor_Fehler (CM_LLR_LS2_Blockierung_Cx1_Blockierung_Kompressor_Fehler)}, range raw 0..1, transfer-property=PENDING, to Klima(timeout 3.5 s)  # Blockierung des Lüfters erkannt Geforderte Solldrehzahl kann nicht erreicht werden
            signal LLR_LS2_CodierPinError_XIX_LLRs_LS_02_XIX_Klima_LIN2: start 9, 1 bit, little-endian, data-type-policy=OVERRIDE, i-signal-type=PRIMITIVE, init-value=0, base-type=BT_LLR_LS2_CodierPinError, compu {0=Cx0_kein_Fehler (CM_LLR_LS2_CodierPinError_Cx0_kein_Fehler), 1=Cx1_HW_Codierung_Fehler (CM_LLR_LS2_CodierPinError_Cx1_HW_Codierung_Fehler)}, range raw 0..1, transfer-property=PENDING, to Klima(timeout 3.5 s)  # Die eingelesene Leitungssatzkodierung entspricht nicht dem abgespeicherten Sollwert
            signal LLR_LS2_Unterspannung_XIX_LLRs_LS_02_XIX_Klima_LIN2: start 10, 1 bit, little-endian, data-type-policy=OVERRIDE, i-signal-type=PRIMITIVE, init-value=0, base-type=BT_LLR_LS2_Unterspannung, invalid-value=Invalid_LLR_LS2_Unterspannung_XIX_LLRs_LS_02_XIX_Klima_LIN2:1, compu {0=Cx0_normal (CM_LLR_LS2_Unterspannung_Cx0_normal), 1=Cx1_Fehler (CM_LLR_LS2_Unterspannung_Cx1_Fehler)}, range raw 0..1, transfer-property=PENDING, to Klima(timeout 3.5 s)  # lokal Unterspannung erkannt
            signal LLR_LS2_Ueberspannung_XIX_LLRs_LS_02_XIX_Klima_LIN2: start 11, 1 bit, little-endian, data-type-policy=OVERRIDE, i-signal-type=PRIMITIVE, init-value=0, base-type=BT_LLR_LS2_Ueberspannung, invalid-value=Invalid_LLR_LS2_Ueberspannung_XIX_LLRs_LS_02_XIX_Klima_LIN2:1, compu {0=Cx0_normal (CM_LLR_LS2_Ueberspannung_Cx0_normal), 1=Cx1_Fehler (CM_LLR_LS2_Ueberspannung_Cx1_Fehler)}, range raw 0..1, transfer-property=PENDING, to Klima(timeout 3.5 s)  # lokal Überspannung erkannt
            signal LLR_LS2_Uebertemperatur_XIX_LLRs_LS_02_XIX_Klima_LIN2: start 12, 1 bit, little-endian, data-type-policy=OVERRIDE, i-signal-type=PRIMITIVE, init-value=0, base-type=BT_LLR_LS2_Uebertemperatur, invalid-value=Invalid_LLR_LS2_Uebertemperatur_XIX_LLRs_LS_02_XIX_Klima_LIN2:1, compu {0=Cx0_normal (CM_LLR_LS2_Uebertemperatur_Cx0_normal), 1=Cx1_Fehler (CM_LLR_LS2_Uebertemperatur_Cx1_Fehler)}, range raw 0..1, transfer-property=PENDING, to Klima(timeout 3.5 s)  # intern gemessene Baugruppentemperatur liegt ausserhalb des zulässigen Bereichs
            signal LLR_LS2_Luefter_defekt_XIX_LLRs_LS_02_XIX_Klima_LIN2: start 13, 1 bit, little-endian, data-type-policy=OVERRIDE, i-signal-type=PRIMITIVE, init-value=0, base-type=BT_LLR_LS2_Luefter_defekt, compu {0=Cx0_Luefter_iO (CM_LLR_LS2_Luefter_defekt_Cx0_Luefter_iO), 1=Cx1_Luefter_defekt (CM_LLR_LS2_Luefter_defekt_Cx1_Luefter_defekt)}, range raw 0..1, transfer-property=PENDING, to Klima(timeout 3.5 s)  # interner Lüfterdefekt erkannt der zu einem Tausch der BG swingt
            signal LLR_LS2_Lokalaktiv_XIX_LLRs_LS_02_XIX_Klima_LIN2: start 14, 1 bit, little-endian, data-type-policy=OVERRIDE, i-signal-type=PRIMITIVE, init-value=0, base-type=BT_LLR_LS2_Lokalaktiv, compu {0=Cx0_war_nicht_lokal_aktiv (CM_LLR_LS2_Lokalaktiv_Cx0_war_nicht_lokal_aktiv), 1=Cx1_war_lokal_aktiv (CM_LLR_LS2_Lokalaktiv_Cx1_war_lokal_aktiv)}, range raw 0..1, transfer-property=PENDING, to Klima(timeout 3.5 s)  # Lüfter war im letzten Sleepmodus lokal aktiv (Nachtlauffunktion)
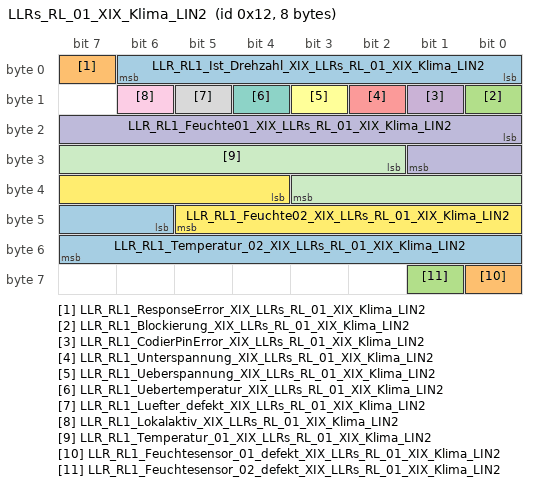
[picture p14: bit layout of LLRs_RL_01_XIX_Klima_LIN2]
        frame LLRs_RL_01_XIX_Klima_LIN2: id 0x12, to Klima, frame-length=8, lin-checksum=ENHANCED
          pdu LLRs_RL_01_XIX_Klima_LIN2: length=8, unused-bit-pattern=0
            signal LLR_RL1_Ist_Drehzahl_XIX_LLRs_RL_01_XIX_Klima_LIN2: start 0, 7 bit, little-endian, data-type-policy=OVERRIDE, i-signal-type=PRIMITIVE, init-value=0, base-type=BT_LLR_RL1_Ist_Drehzahl, compu {phys=raw for raw 0..100; unit Unit_PerCent}, range phys 0..100 Unit_PerCent, raw 0..100, unit=Unit_PerCent, transfer-property=PENDING, to Klima(timeout 3.5 s)  # Aktuelle Istdrehzahl [%] in Bezug auf Maximalwert
            signal LLR_RL1_ResponseError_XIX_LLRs_RL_01_XIX_Klima_LIN2: start 7, 1 bit, little-endian, data-type-policy=OVERRIDE, i-signal-type=PRIMITIVE, init-value=0, base-type=BT_LLR_RL1_ResponseError, invalid-value=Invalid_LLR_RL1_ResponseError_XIX_LLRs_RL_01_XIX_Klima_LIN2:1, compu {0=Cx0_normal (CM_LLR_RL1_ResponseError_Cx0_normal), 1=Cx1_Fehler (CM_LLR_RL1_ResponseError_Cx1_Fehler)}, range raw 0..1, transfer-property=PENDING, to Klima(timeout 3.5 s)  # siehe LIN2.0-Specification (Darf nicht über ein Fehlergueltigkeitsbit abgesichtert werden!)
            signal LLR_RL1_Blockierung_XIX_LLRs_RL_01_XIX_Klima_LIN2: start 8, 1 bit, little-endian, data-type-policy=OVERRIDE, i-signal-type=PRIMITIVE, init-value=0, base-type=BT_LLR_RL1_Blockierung, compu {0=Cx0_kein_Fehler (CM_LLR_RL1_Blockierung_Cx0_kein_Fehler), 1=Cx1_Blockierung_Kompressor_Fehler (CM_LLR_RL1_Blockierung_Cx1_Blockierung_Kompressor_Fehler)}, range raw 0..1, transfer-property=PENDING, to Klima(timeout 3.5 s)  # Blockierung des Lüfters erkannt Geforderte Solldrehzahl kann nicht erreicht werden
            signal LLR_RL1_CodierPinError_XIX_LLRs_RL_01_XIX_Klima_LIN2: start 9, 1 bit, little-endian, data-type-policy=OVERRIDE, i-signal-type=PRIMITIVE, init-value=0, base-type=BT_LLR_RL1_CodierPinError, compu {0=Cx0_kein_Fehler (CM_LLR_RL1_CodierPinError_Cx0_kein_Fehler), 1=Cx1_HW_Codierung_Fehler (CM_LLR_RL1_CodierPinError_Cx1_HW_Codierung_Fehler)}, range raw 0..1, transfer-property=PENDING, to Klima(timeout 3.5 s)  # Die eingelesene Leitungssatzkodierung entspricht nicht dem abgespeicherten Sollwert
            signal LLR_RL1_Unterspannung_XIX_LLRs_RL_01_XIX_Klima_LIN2: start 10, 1 bit, little-endian, data-type-policy=OVERRIDE, i-signal-type=PRIMITIVE, init-value=0, base-type=BT_LLR_RL1_Unterspannung, invalid-value=Invalid_LLR_RL1_Unterspannung_XIX_LLRs_RL_01_XIX_Klima_LIN2:1, compu {0=Cx0_normal (CM_LLR_RL1_Unterspannung_Cx0_normal), 1=Cx1_Fehler (CM_LLR_RL1_Unterspannung_Cx1_Fehler)}, range raw 0..1, transfer-property=PENDING, to Klima(timeout 3.5 s)  # Fehlende Beschreibung (Import)
            signal LLR_RL1_Ueberspannung_XIX_LLRs_RL_01_XIX_Klima_LIN2: start 11, 1 bit, little-endian, data-type-policy=OVERRIDE, i-signal-type=PRIMITIVE, init-value=0, base-type=BT_LLR_RL1_Ueberspannung, invalid-value=Invalid_LLR_RL1_Ueberspannung_XIX_LLRs_RL_01_XIX_Klima_LIN2:1, compu {0=Cx0_normal (CM_LLR_RL1_Ueberspannung_Cx0_normal), 1=Cx1_Fehler (CM_LLR_RL1_Ueberspannung_Cx1_Fehler)}, range raw 0..1, transfer-property=PENDING, to Klima(timeout 3.5 s)  # lokal Überspannung erkannt
            signal LLR_RL1_Uebertemperatur_XIX_LLRs_RL_01_XIX_Klima_LIN2: start 12, 1 bit, little-endian, data-type-policy=OVERRIDE, i-signal-type=PRIMITIVE, init-value=0, base-type=BT_LLR_RL1_Uebertemperatur, invalid-value=Invalid_LLR_RL1_Uebertemperatur_XIX_LLRs_RL_01_XIX_Klima_LIN2:1, compu {0=Cx0_normal (CM_LLR_RL1_Uebertemperatur_Cx0_normal), 1=Cx1_Fehler (CM_LLR_RL1_Uebertemperatur_Cx1_Fehler)}, range raw 0..1, transfer-property=PENDING, to Klima(timeout 3.5 s)  # intern gemessene Baugruppentemperatur liegt ausserhalb des zulässigen Bereichs
            signal LLR_RL1_Luefter_defekt_XIX_LLRs_RL_01_XIX_Klima_LIN2: start 13, 1 bit, little-endian, data-type-policy=OVERRIDE, i-signal-type=PRIMITIVE, init-value=0, base-type=BT_LLR_RL1_Luefter_defekt, compu {0=Cx0_Luefter_iO (CM_LLR_RL1_Luefter_defekt_Cx0_Luefter_iO), 1=Cx1_Luefter_defekt (CM_LLR_RL1_Luefter_defekt_Cx1_Luefter_defekt)}, range raw 0..1, transfer-property=PENDING, to Klima(timeout 3.5 s)  # interner Lüfterdefekt erkannt der zu einem Tausch der BG swingt
            signal LLR_RL1_Lokalaktiv_XIX_LLRs_RL_01_XIX_Klima_LIN2: start 14, 1 bit, little-endian, data-type-policy=OVERRIDE, i-signal-type=PRIMITIVE, init-value=0, base-type=BT_LLR_RL1_Lokalaktiv, compu {0=Cx0_war_nicht_lokal_aktiv (CM_LLR_RL1_Lokalaktiv_Cx0_war_nicht_lokal_aktiv), 1=Cx1_war_lokal_aktiv (CM_LLR_RL1_Lokalaktiv_Cx1_war_lokal_aktiv)}, range raw 0..1, transfer-property=PENDING, to Klima(timeout 3.5 s)  # Lüfter war im letzten Sleepmodus lokal aktiv (Nachtlauffunktion)
            signal LLR_RL1_Feuchte01_XIX_LLRs_RL_01_XIX_Klima_LIN2: start 16, 10 bit, little-endian, data-type-policy=OVERRIDE, i-signal-type=PRIMITIVE, init-value=1022, base-type=BT_LLR_RL1_Feuchte01, invalid-value=Invalid_LLR_RL1_Feuchte01_XIX_LLRs_RL_01_XIX_Klima_LIN2:1023, compu {phys=raw*0.1000000015 for raw 0..1021, 1022=Cx3fe_Init (CM_LLR_RL1_Feuchte01_Cx3fe_Init), 1023=Cx3ff_Fehler (CM_LLR_RL1_Feuchte01_Cx3ff_Fehler); unit Unit_PerCent}, range phys 0..102.10000152140856 Unit_PerCent, raw 0..1023, unit=Unit_PerCent, transfer-property=PENDING, to Klima(timeout 3.5 s)  # Vom Sensor01 gemessene relative Feuchte
            signal LLR_RL1_Temperatur_01_XIX_LLRs_RL_01_XIX_Klima_LIN2: start 26, 10 bit, little-endian, data-type-policy=OVERRIDE, i-signal-type=PRIMITIVE, init-value=1022, base-type=BT_LLR_RL1_Temperatur_01, invalid-value=Invalid_LLR_RL1_Temperatur_01_XIX_LLRs_RL_01_XIX_Klima_LIN2:1023, compu {phys=raw*0.1000000015-40 for raw 0..1019, 1020=Cx3fc_Temperatur_unter_40_C (CM_LLR_RL1_Temperatur_01_Cx3fc_Temperatur_unter_40_C) (Temperatur_unter_-40°C), 1021=Cx3fd_Temperatur_ueber_60_C (CM_LLR_RL1_Temperatur_01_Cx3fd_Temperatur_ueber_60_C) (Temperatur_über_+60°C), 1022=Cx3fe_Init (CM_LLR_RL1_Temperatur_01_Cx3fe_Init), 1023=Cx3ff_Fehler (CM_LLR_RL1_Temperatur_01_Cx3ff_Fehler); unit Unit_DegreCelsi}, range phys -40..61.900001518428326 Unit_DegreCelsi, raw 0..1023, unit=Unit_DegreCelsi, transfer-property=PENDING, to Klima(timeout 3.5 s)  # Vom Sensor01 gemessene Temperatur
            signal LLR_RL1_Feuchte02_XIX_LLRs_RL_01_XIX_Klima_LIN2: start 36, 10 bit, little-endian, data-type-policy=OVERRIDE, i-signal-type=PRIMITIVE, init-value=1022, base-type=BT_LLR_RL1_Feuchte02, invalid-value=Invalid_LLR_RL1_Feuchte02_XIX_LLRs_RL_01_XIX_Klima_LIN2:1023, compu {phys=raw*0.1000000015 for raw 0..1021, 1022=Cx3fe_Init (CM_LLR_RL1_Feuchte02_Cx3fe_Init), 1023=Cx3ff_Fehler (CM_LLR_RL1_Feuchte02_Cx3ff_Fehler); unit Unit_PerCent}, range phys 0..102.10000152140856 Unit_PerCent, raw 0..1023, unit=Unit_PerCent, transfer-property=PENDING, to Klima(timeout 3.5 s)  # Vom Sensor02 gemessene relative Feuchte
            signal LLR_RL1_Temperatur_02_XIX_LLRs_RL_01_XIX_Klima_LIN2: start 46, 10 bit, little-endian, data-type-policy=OVERRIDE, i-signal-type=PRIMITIVE, init-value=1022, base-type=BT_LLR_RL1_Temperatur_02, invalid-value=Invalid_LLR_RL1_Temperatur_02_XIX_LLRs_RL_01_XIX_Klima_LIN2:1023, compu {phys=raw*0.1000000015-40 for raw 0..1019, 1020=Cx3fc_Temperatur_unter_40_C (CM_LLR_RL1_Temperatur_02_Cx3fc_Temperatur_unter_40_C) (Temperatur_unter_-40°C), 1021=Cx3fd_Temperatur_ueber_60_C (CM_LLR_RL1_Temperatur_02_Cx3fd_Temperatur_ueber_60_C) (Temperatur_über_+60°C), 1022=Cx3fe_Init (CM_LLR_RL1_Temperatur_02_Cx3fe_Init), 1023=Cx3ff_Fehler (CM_LLR_RL1_Temperatur_02_Cx3ff_Fehler); unit Unit_DegreCelsi}, range phys -40..61.900001518428326 Unit_DegreCelsi, raw 0..1023, unit=Unit_DegreCelsi, transfer-property=PENDING, to Klima(timeout 3.5 s)  # Vom Sensor02 gemessene Temperatur
            signal LLR_RL1_Feuchtesensor_01_defekt_XIX_LLRs_RL_01_XIX_Klima_LIN2: start 56, 1 bit, little-endian, data-type-policy=OVERRIDE, i-signal-type=PRIMITIVE, init-value=0, base-type=BT_LLR_RL1_Feuchtesensor_01_defekt, compu {0=Cx0_Sensor_iO (CM_LLR_RL1_Feuchtesensor_01_defekt_Cx0_Sensor_iO), 1=Cx1_Sensor_defekt (CM_LLR_RL1_Feuchtesensor_01_defekt_Cx1_Sensor_defekt)}, range raw 0..1, transfer-property=PENDING, to Klima(timeout 3.5 s)  # Fehlfunktion des angeschlossenen externen Feuchtesensors 01 erkannt
            signal LLR_RL1_Feuchtesensor_02_defekt_XIX_LLRs_RL_01_XIX_Klima_LIN2: start 57, 1 bit, little-endian, data-type-policy=OVERRIDE, i-signal-type=PRIMITIVE, init-value=0, base-type=BT_LLR_RL1_Feuchtesensor_02_defekt, compu {0=Cx0_Sensor_iO (CM_LLR_RL1_Feuchtesensor_02_defekt_Cx0_Sensor_iO), 1=Cx1_Sensor_defekt (CM_LLR_RL1_Feuchtesensor_02_defekt_Cx1_Sensor_defekt)}, range raw 0..1, transfer-property=PENDING, to Klima(timeout 3.5 s)  # Status Feuchtesensor02
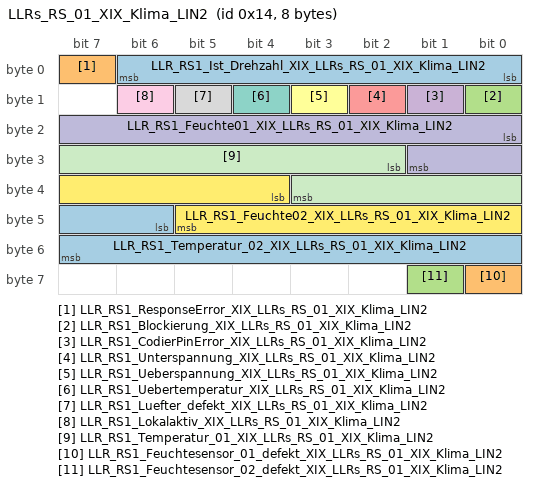
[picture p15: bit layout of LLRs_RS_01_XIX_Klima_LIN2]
        frame LLRs_RS_01_XIX_Klima_LIN2: id 0x14, to Klima, frame-length=8, lin-checksum=ENHANCED
          pdu LLRs_RS_01_XIX_Klima_LIN2: length=8, unused-bit-pattern=0
            signal LLR_RS1_Ist_Drehzahl_XIX_LLRs_RS_01_XIX_Klima_LIN2: start 0, 7 bit, little-endian, data-type-policy=OVERRIDE, i-signal-type=PRIMITIVE, init-value=0, base-type=BT_LLR_RS1_Ist_Drehzahl, compu {phys=raw for raw 0..100; unit Unit_PerCent}, range phys 0..100 Unit_PerCent, raw 0..100, unit=Unit_PerCent, transfer-property=PENDING, to Klima(timeout 3.5 s)  # Aktuelle Istdrehzahl [%] in Bezug auf Maximalwert
            signal LLR_RS1_ResponseError_XIX_LLRs_RS_01_XIX_Klima_LIN2: start 7, 1 bit, little-endian, data-type-policy=OVERRIDE, i-signal-type=PRIMITIVE, init-value=0, base-type=BT_LLR_RS1_ResponseError, invalid-value=Invalid_LLR_RS1_ResponseError_XIX_LLRs_RS_01_XIX_Klima_LIN2:1, compu {0=Cx0_normal (CM_LLR_RS1_ResponseError_Cx0_normal), 1=Cx1_Fehler (CM_LLR_RS1_ResponseError_Cx1_Fehler)}, range raw 0..1, transfer-property=PENDING, to Klima(timeout 3.5 s)  # siehe LIN2.0-Specification (Darf nicht über ein Fehlergueltigkeitsbit abgesichtert werden!)
            signal LLR_RS1_Blockierung_XIX_LLRs_RS_01_XIX_Klima_LIN2: start 8, 1 bit, little-endian, data-type-policy=OVERRIDE, i-signal-type=PRIMITIVE, init-value=0, base-type=BT_LLR_RS1_Blockierung, compu {0=Cx0_kein_Fehler (CM_LLR_RS1_Blockierung_Cx0_kein_Fehler), 1=Cx1_Blockierung_Kompressor_Fehler (CM_LLR_RS1_Blockierung_Cx1_Blockierung_Kompressor_Fehler)}, range raw 0..1, transfer-property=PENDING, to Klima(timeout 3.5 s)  # Blockierung des Lüfters erkannt Geforderte Solldrehzahl kann nicht erreicht werden
            signal LLR_RS1_CodierPinError_XIX_LLRs_RS_01_XIX_Klima_LIN2: start 9, 1 bit, little-endian, data-type-policy=OVERRIDE, i-signal-type=PRIMITIVE, init-value=0, base-type=BT_LLR_RS1_CodierPinError, compu {0=Cx0_kein_Fehler (CM_LLR_RS1_CodierPinError_Cx0_kein_Fehler), 1=Cx1_HW_Codierung_Fehler (CM_LLR_RS1_CodierPinError_Cx1_HW_Codierung_Fehler)}, range raw 0..1, transfer-property=PENDING, to Klima(timeout 3.5 s)  # Die eingelesene Leitungssatzkodierung entspricht nicht dem abgespeicherten Sollwert
            signal LLR_RS1_Unterspannung_XIX_LLRs_RS_01_XIX_Klima_LIN2: start 10, 1 bit, little-endian, data-type-policy=OVERRIDE, i-signal-type=PRIMITIVE, init-value=0, base-type=BT_LLR_RS1_Unterspannung, invalid-value=Invalid_LLR_RS1_Unterspannung_XIX_LLRs_RS_01_XIX_Klima_LIN2:1, compu {0=Cx0_normal (CM_LLR_RS1_Unterspannung_Cx0_normal), 1=Cx1_Fehler (CM_LLR_RS1_Unterspannung_Cx1_Fehler)}, range raw 0..1, transfer-property=PENDING, to Klima(timeout 3.5 s)  # lokal Unterspannung erkannt
            signal LLR_RS1_Ueberspannung_XIX_LLRs_RS_01_XIX_Klima_LIN2: start 11, 1 bit, little-endian, data-type-policy=OVERRIDE, i-signal-type=PRIMITIVE, init-value=0, base-type=BT_LLR_RS1_Ueberspannung, invalid-value=Invalid_LLR_RS1_Ueberspannung_XIX_LLRs_RS_01_XIX_Klima_LIN2:1, compu {0=Cx0_normal (CM_LLR_RS1_Ueberspannung_Cx0_normal), 1=Cx1_Fehler (CM_LLR_RS1_Ueberspannung_Cx1_Fehler)}, range raw 0..1, transfer-property=PENDING, to Klima(timeout 3.5 s)  # lokal Überspannung erkannt
            signal LLR_RS1_Uebertemperatur_XIX_LLRs_RS_01_XIX_Klima_LIN2: start 12, 1 bit, little-endian, data-type-policy=OVERRIDE, i-signal-type=PRIMITIVE, init-value=0, base-type=BT_LLR_RS1_Uebertemperatur, invalid-value=Invalid_LLR_RS1_Uebertemperatur_XIX_LLRs_RS_01_XIX_Klima_LIN2:1, compu {0=Cx0_normal (CM_LLR_RS1_Uebertemperatur_Cx0_normal), 1=Cx1_Fehler (CM_LLR_RS1_Uebertemperatur_Cx1_Fehler)}, range raw 0..1, transfer-property=PENDING, to Klima(timeout 3.5 s)  # intern gemessene Baugruppentemperatur liegt ausserhalb des zulässigen Bereichs
            signal LLR_RS1_Luefter_defekt_XIX_LLRs_RS_01_XIX_Klima_LIN2: start 13, 1 bit, little-endian, data-type-policy=OVERRIDE, i-signal-type=PRIMITIVE, init-value=0, base-type=BT_LLR_RS1_Luefter_defekt, compu {0=Cx0_Luefter_iO (CM_LLR_RS1_Luefter_defekt_Cx0_Luefter_iO), 1=Cx1_Luefter_defekt (CM_LLR_RS1_Luefter_defekt_Cx1_Luefter_defekt)}, range raw 0..1, transfer-property=PENDING, to Klima(timeout 3.5 s)  # interner Lüfterdefekt erkannt der zu einem Tausch der BG swingt
            signal LLR_RS1_Lokalaktiv_XIX_LLRs_RS_01_XIX_Klima_LIN2: start 14, 1 bit, little-endian, data-type-policy=OVERRIDE, i-signal-type=PRIMITIVE, init-value=0, base-type=BT_LLR_RS1_Lokalaktiv, compu {0=Cx0_war_nicht_lokal_aktiv (CM_LLR_RS1_Lokalaktiv_Cx0_war_nicht_lokal_aktiv), 1=Cx1_war_lokal_aktiv (CM_LLR_RS1_Lokalaktiv_Cx1_war_lokal_aktiv)}, range raw 0..1, transfer-property=PENDING, to Klima(timeout 3.5 s)  # Lüfter war im letzten Sleepmodus lokal aktiv (Nachtlauffunktion)
            signal LLR_RS1_Feuchte01_XIX_LLRs_RS_01_XIX_Klima_LIN2: start 16, 10 bit, little-endian, data-type-policy=OVERRIDE, i-signal-type=PRIMITIVE, init-value=1022, base-type=BT_LLR_RS1_Feuchte01, invalid-value=Invalid_LLR_RS1_Feuchte01_XIX_LLRs_RS_01_XIX_Klima_LIN2:1023, compu {phys=raw*0.1000000015 for raw 0..1021, 1022=Cx3fe_Init (CM_LLR_RS1_Feuchte01_Cx3fe_Init), 1023=Cx3ff_Fehler (CM_LLR_RS1_Feuchte01_Cx3ff_Fehler); unit Unit_PerCent}, range phys 0..102.10000152140856 Unit_PerCent, raw 0..1023, unit=Unit_PerCent, transfer-property=PENDING, to Klima(timeout 3.5 s)  # Vom Sensor01 gemessene relative Feuchte
            signal LLR_RS1_Temperatur_01_XIX_LLRs_RS_01_XIX_Klima_LIN2: start 26, 10 bit, little-endian, data-type-policy=OVERRIDE, i-signal-type=PRIMITIVE, init-value=1022, base-type=BT_LLR_RS1_Temperatur_01, invalid-value=Invalid_LLR_RS1_Temperatur_01_XIX_LLRs_RS_01_XIX_Klima_LIN2:1023, compu {phys=raw*0.1000000015-40 for raw 0..1019, 1020=Cx3fc_Temperatur_unter_40_C (CM_LLR_RS1_Temperatur_01_Cx3fc_Temperatur_unter_40_C) (Temperatur unter -40°C), 1021=Cx3fd_Temperatur_ueber_60_C (CM_LLR_RS1_Temperatur_01_Cx3fd_Temperatur_ueber_60_C) (Temperatur über +60°C), 1022=Cx3fe_Init (CM_LLR_RS1_Temperatur_01_Cx3fe_Init), 1023=Cx3ff_Fehler (CM_LLR_RS1_Temperatur_01_Cx3ff_Fehler); unit Unit_DegreCelsi}, range phys -40..61.900001518428326 Unit_DegreCelsi, raw 0..1023, unit=Unit_DegreCelsi, transfer-property=PENDING, to Klima(timeout 3.5 s)  # Vom Sensor01 gemessene Temperatur
            signal LLR_RS1_Feuchte02_XIX_LLRs_RS_01_XIX_Klima_LIN2: start 36, 10 bit, little-endian, data-type-policy=OVERRIDE, i-signal-type=PRIMITIVE, init-value=1022, base-type=BT_LLR_RS1_Feuchte02, invalid-value=Invalid_LLR_RS1_Feuchte02_XIX_LLRs_RS_01_XIX_Klima_LIN2:1023, compu {phys=raw*0.1000000015 for raw 0..1021, 1022=Cx3fe_Init (CM_LLR_RS1_Feuchte02_Cx3fe_Init), 1023=Cx3ff_Fehler (CM_LLR_RS1_Feuchte02_Cx3ff_Fehler); unit Unit_PerCent}, range phys 0..102.10000152140856 Unit_PerCent, raw 0..1023, unit=Unit_PerCent, transfer-property=PENDING, to Klima(timeout 3.5 s)  # Vom Sensor02 gemessene relative Feuchte
            signal LLR_RS1_Temperatur_02_XIX_LLRs_RS_01_XIX_Klima_LIN2: start 46, 10 bit, little-endian, data-type-policy=OVERRIDE, i-signal-type=PRIMITIVE, init-value=1022, base-type=BT_LLR_RS1_Temperatur_02, compu {phys=raw*0.1000000015-40 for raw 0..1019, 1020=Cx3fc_Temperatur_unter_minus_40_Grad_C (CM_LLR_RS1_Temperatur_02_Cx3fc_Temperatur_unter_minus_40_Grad_C), 1021=Cx3fd_Temperatur_ueber_plus_60_Grad_C (CM_LLR_RS1_Temperatur_02_Cx3fd_Temperatur_ueber_plus_60_Grad_C), 1022=Cx3fe_Init (CM_LLR_RS1_Temperatur_02_Cx3fe_Init); unit Unit_DegreCelsi}, range phys -40..61.900001518428326 Unit_DegreCelsi, raw 0..1022, unit=Unit_DegreCelsi, transfer-property=PENDING, to Klima(timeout 3.5 s)  # Vom Sensor02 gemessene Temperatur
            signal LLR_RS1_Feuchtesensor_01_defekt_XIX_LLRs_RS_01_XIX_Klima_LIN2: start 56, 1 bit, little-endian, data-type-policy=OVERRIDE, i-signal-type=PRIMITIVE, init-value=0, base-type=BT_LLR_RS1_Feuchtesensor_01_defekt, compu {0=Cx0_Sensor_iO (CM_LLR_RS1_Feuchtesensor_01_defekt_Cx0_Sensor_iO), 1=Cx1_Sensor_defekt (CM_LLR_RS1_Feuchtesensor_01_defekt_Cx1_Sensor_defekt)}, range raw 0..1, transfer-property=PENDING, to Klima(timeout 3.5 s)  # Status Feuchtesensor01
            signal LLR_RS1_Feuchtesensor_02_defekt_XIX_LLRs_RS_01_XIX_Klima_LIN2: start 57, 1 bit, little-endian, data-type-policy=OVERRIDE, i-signal-type=PRIMITIVE, init-value=0, base-type=BT_LLR_RS1_Feuchtesensor_02_defekt, compu {0=Cx0_Sensor_iO (CM_LLR_RS1_Feuchtesensor_02_defekt_Cx0_Sensor_iO), 1=Cx1_Sensor_defekt (CM_LLR_RS1_Feuchtesensor_02_defekt_Cx1_Sensor_defekt)}, range raw 0..1, transfer-property=PENDING, to Klima(timeout 3.5 s)  # Status Feuchtesensor02
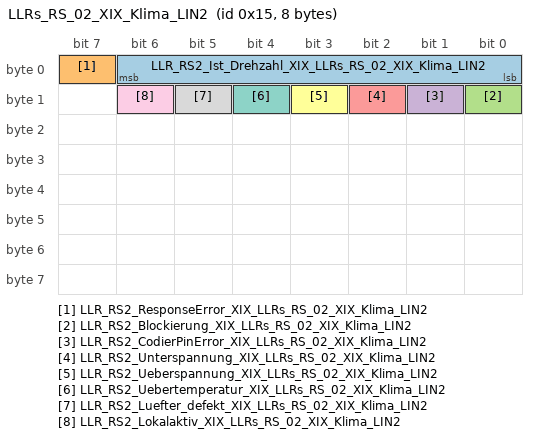
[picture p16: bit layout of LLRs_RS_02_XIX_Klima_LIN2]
        frame LLRs_RS_02_XIX_Klima_LIN2: id 0x15, to Klima, frame-length=8, lin-checksum=ENHANCED
          pdu LLRs_RS_02_XIX_Klima_LIN2: length=8, unused-bit-pattern=0
            signal LLR_RS2_Ist_Drehzahl_XIX_LLRs_RS_02_XIX_Klima_LIN2: start 0, 7 bit, little-endian, data-type-policy=OVERRIDE, i-signal-type=PRIMITIVE, init-value=0, base-type=BT_LLR_RS2_Ist_Drehzahl, compu {phys=raw for raw 0..100; unit Unit_PerCent}, range phys 0..100 Unit_PerCent, raw 0..100, unit=Unit_PerCent, transfer-property=PENDING, to Klima(timeout 3.5 s)  # Aktuelle Istdrehzahl [%] in Bezug auf Maximalwert
            signal LLR_RS2_ResponseError_XIX_LLRs_RS_02_XIX_Klima_LIN2: start 7, 1 bit, little-endian, data-type-policy=OVERRIDE, i-signal-type=PRIMITIVE, init-value=0, base-type=BT_LLR_RS2_ResponseError, invalid-value=Invalid_LLR_RS2_ResponseError_XIX_LLRs_RS_02_XIX_Klima_LIN2:1, compu {0=Cx0_normal (CM_LLR_RS2_ResponseError_Cx0_normal), 1=Cx1_Fehler (CM_LLR_RS2_ResponseError_Cx1_Fehler)}, range raw 0..1, transfer-property=PENDING, to Klima(timeout 3.5 s)  # siehe LIN2.0-Specification (Darf nicht über ein Fehlergueltigkeitsbit abgesichtert werden!)
            signal LLR_RS2_Blockierung_XIX_LLRs_RS_02_XIX_Klima_LIN2: start 8, 1 bit, little-endian, data-type-policy=OVERRIDE, i-signal-type=PRIMITIVE, init-value=0, base-type=BT_LLR_RS2_Blockierung, compu {0=Cx0_kein_Fehler (CM_LLR_RS2_Blockierung_Cx0_kein_Fehler), 1=Cx1_Blockierung_Kompressor_Fehler (CM_LLR_RS2_Blockierung_Cx1_Blockierung_Kompressor_Fehler)}, range raw 0..1, transfer-property=PENDING, to Klima(timeout 3.5 s)  # Blockierung des Lüfters erkannt Geforderte Solldrehzahl kann nicht erreicht werden
            signal LLR_RS2_CodierPinError_XIX_LLRs_RS_02_XIX_Klima_LIN2: start 9, 1 bit, little-endian, data-type-policy=OVERRIDE, i-signal-type=PRIMITIVE, init-value=0, base-type=BT_LLR_RS2_CodierPinError, compu {0=Cx0_kein_Fehler (CM_LLR_RS2_CodierPinError_Cx0_kein_Fehler), 1=Cx1_HW_Codierung_Fehler (CM_LLR_RS2_CodierPinError_Cx1_HW_Codierung_Fehler)}, range raw 0..1, transfer-property=PENDING, to Klima(timeout 3.5 s)  # Die eingelesene Leitungssatzkodierung entspricht nicht dem abgespeicherten Sollwert
            signal LLR_RS2_Unterspannung_XIX_LLRs_RS_02_XIX_Klima_LIN2: start 10, 1 bit, little-endian, data-type-policy=OVERRIDE, i-signal-type=PRIMITIVE, init-value=0, base-type=BT_LLR_RS2_Unterspannung, invalid-value=Invalid_LLR_RS2_Unterspannung_XIX_LLRs_RS_02_XIX_Klima_LIN2:1, compu {0=Cx0_normal (CM_LLR_RS2_Unterspannung_Cx0_normal), 1=Cx1_Fehler (CM_LLR_RS2_Unterspannung_Cx1_Fehler)}, range raw 0..1, transfer-property=PENDING, to Klima(timeout 3.5 s)  # lokal Unterspannung erkannt
            signal LLR_RS2_Ueberspannung_XIX_LLRs_RS_02_XIX_Klima_LIN2: start 11, 1 bit, little-endian, data-type-policy=OVERRIDE, i-signal-type=PRIMITIVE, init-value=0, base-type=BT_LLR_RS2_Ueberspannung, invalid-value=Invalid_LLR_RS2_Ueberspannung_XIX_LLRs_RS_02_XIX_Klima_LIN2:1, compu {0=Cx0_normal (CM_LLR_RS2_Ueberspannung_Cx0_normal), 1=Cx1_Fehler (CM_LLR_RS2_Ueberspannung_Cx1_Fehler)}, range raw 0..1, transfer-property=PENDING, to Klima(timeout 3.5 s)  # lokal Überspannung erkannt
            signal LLR_RS2_Uebertemperatur_XIX_LLRs_RS_02_XIX_Klima_LIN2: start 12, 1 bit, little-endian, data-type-policy=OVERRIDE, i-signal-type=PRIMITIVE, init-value=0, base-type=BT_LLR_RS2_Uebertemperatur, invalid-value=Invalid_LLR_RS2_Uebertemperatur_XIX_LLRs_RS_02_XIX_Klima_LIN2:1, compu {0=Cx0_normal (CM_LLR_RS2_Uebertemperatur_Cx0_normal), 1=Cx1_Fehler (CM_LLR_RS2_Uebertemperatur_Cx1_Fehler)}, range raw 0..1, transfer-property=PENDING, to Klima(timeout 3.5 s)  # intern gemessene Baugruppentemperatur liegt ausserhalb des zulässigen Bereichs
            signal LLR_RS2_Luefter_defekt_XIX_LLRs_RS_02_XIX_Klima_LIN2: start 13, 1 bit, little-endian, data-type-policy=OVERRIDE, i-signal-type=PRIMITIVE, init-value=0, base-type=BT_LLR_RS2_Luefter_defekt, compu {0=Cx0_Luefter_iO (CM_LLR_RS2_Luefter_defekt_Cx0_Luefter_iO), 1=Cx1_Luefter_defekt (CM_LLR_RS2_Luefter_defekt_Cx1_Luefter_defekt)}, range raw 0..1, transfer-property=PENDING, to Klima(timeout 3.5 s)  # interner Lüfterdefekt erkannt der zu einem Tausch der BG swingt
            signal LLR_RS2_Lokalaktiv_XIX_LLRs_RS_02_XIX_Klima_LIN2: start 14, 1 bit, little-endian, data-type-policy=OVERRIDE, i-signal-type=PRIMITIVE, init-value=0, base-type=BT_LLR_RS2_Lokalaktiv, compu {0=Cx0_war_nicht_lokal_aktiv (CM_LLR_RS2_Lokalaktiv_Cx0_war_nicht_lokal_aktiv), 1=Cx1_war_lokal_aktiv (CM_LLR_RS2_Lokalaktiv_Cx1_war_lokal_aktiv)}, range raw 0..1, transfer-property=PENDING, to Klima(timeout 3.5 s)  # Lüfter war im letzten Sleepmodus lokal aktiv (Nachtlauffunktion)
        frame MasterReq_XIX_Klima_LIN2: id 0x3C, from Klima, frame-length=8, lin-checksum=CLASSIC
          n pdu MasterReq_XIX_Klima_LIN2: length=8
        frame SlaveResp_XIX_Klima_LIN2: id 0x3D, to Klima, frame-length=8, lin-checksum=CLASSIC
          n pdu SlaveResp_XIX_Klima_LIN2: length=8
        pdu triggering PT_Klima_LIN2_XIX_TPCHType_LIN_Diagnose_XIX_0x0_XIX_0x10_XIX_Physical: pdu=DCM_Klima_LIN2_XIX_TPCHType_LIN_Diagnose_XIX_0x0_XIX_0x10_XIX_Physical, from Klima
        pdu triggering PT_Klima_LIN2_XIX_TPCHType_LIN_Diagnose_XIX_0x0_XIX_0x15_XIX_Physical: pdu=DCM_Klima_LIN2_XIX_TPCHType_LIN_Diagnose_XIX_0x0_XIX_0x15_XIX_Physical, from Klima
        pdu triggering PT_Klima_LIN2_XIX_TPCHType_LIN_Diagnose_XIX_0x0_XIX_0x{17..22}_XIX_Physical: pdu=DCM_Klima_LIN2_XIX_TPCHType_LIN_Diagnose_XIX_0x0_XIX_0x{17..22}_XIX_Physical, from Klima
        pdu triggering PT_Klima_LIN2_XIX_TPCHType_LIN_Diagnose_XIX_0x0_XIX_0x6D_XIX_Physical: pdu=DCM_Klima_LIN2_XIX_TPCHType_LIN_Diagnose_XIX_0x0_XIX_0x6D_XIX_Physical, from Klima
        pdu triggering PT_Klima_LIN2_XIX_TPCHType_LIN_Diagnose_XIX_0x0_XIX_0xD_XIX_Physical: pdu=DCM_Klima_LIN2_XIX_TPCHType_LIN_Diagnose_XIX_0x0_XIX_0xD_XIX_Physical, from Klima
        pdu triggering PT_Klima_LIN2_XIX_TPCHType_LIN_Diagnose_XIX_0x0_XIX_0xF_XIX_Physical: pdu=DCM_Klima_LIN2_XIX_TPCHType_LIN_Diagnose_XIX_0x0_XIX_0xF_XIX_Physical, from Klima
        pdu triggering PT_Klima_LIN2_XIX_TPCHType_LIN_Diagnose_XIX_0x10_XIX_0x0_XIX_Physical: pdu=DCM_Klima_LIN2_XIX_TPCHType_LIN_Diagnose_XIX_0x10_XIX_0x0_XIX_Physical, to Klima
        pdu triggering PT_Klima_LIN2_XIX_TPCHType_LIN_Diagnose_XIX_0x15_XIX_0x0_XIX_Physical: pdu=DCM_Klima_LIN2_XIX_TPCHType_LIN_Diagnose_XIX_0x15_XIX_0x0_XIX_Physical, to Klima
        pdu triggering PT_Klima_LIN2_XIX_TPCHType_LIN_Diagnose_XIX_0x{17..22}_XIX_0x0_XIX_Physical: pdu=DCM_Klima_LIN2_XIX_TPCHType_LIN_Diagnose_XIX_0x{17..22}_XIX_0x0_XIX_Physical, to Klima
        pdu triggering PT_Klima_LIN2_XIX_TPCHType_LIN_Diagnose_XIX_0x6D_XIX_0x0_XIX_Physical: pdu=DCM_Klima_LIN2_XIX_TPCHType_LIN_Diagnose_XIX_0x6D_XIX_0x0_XIX_Physical, to Klima
        pdu triggering PT_Klima_LIN2_XIX_TPCHType_LIN_Diagnose_XIX_0xD_XIX_0x0_XIX_Physical: pdu=DCM_Klima_LIN2_XIX_TPCHType_LIN_Diagnose_XIX_0xD_XIX_0x0_XIX_Physical, to Klima
        pdu triggering PT_Klima_LIN2_XIX_TPCHType_LIN_Diagnose_XIX_0xF_XIX_0x0_XIX_Physical: pdu=DCM_Klima_LIN2_XIX_TPCHType_LIN_Diagnose_XIX_0xF_XIX_0x0_XIX_Physical, to Klima
        5 x lin schedule table, all with resume-position=CONTINUE-AT-IT-POSITION:
          DiagRequest: run-mode=RUN-ONCE, application-entry{delay=0.01, position-in-table=0, frame-triggering=CHNL/FT_MasterReq}
          DiagResponse: run-mode=RUN-ONCE, application-entry{delay=0.01, position-in-table=0, frame-triggering=CHNL/FT_SlaveResp}
          st_main_1: run-mode=RUN-CONTINUOUS
            table-entrys:
              delay=0.04, position-in-table=0, frame-triggering=FT_DSs_01
              delay=0.06, position-in-table=1, frame-triggering=FT_IONe_01
              delay=0.04, position-in-table=2, frame-triggering=FT_DSs_01
              delay=0.06, position-in-table=3, frame-triggering=FT_IONs_01
          st_main_2: run-mode=RUN-CONTINUOUS
            table-entrys:
              delay=0.02, position-in-table=0, frame-triggering=CHNL/FT_LLRe_L_01
              delay=0.02, position-in-table=1, frame-triggering=FT_LLRs_LS_02
              delay=0.01, position-in-table=2, frame-triggering=CHNL/FT_LLRs_LL_01
              delay=0.03, position-in-table=3, frame-triggering=FT_DSs_01
              delay=0.01, position-in-table=4, frame-triggering=CHNL/FT_LLRs_LS_01
              delay=0.01, position-in-table=5, frame-triggering=FT_IONe_01
              delay=0.02, position-in-table=6, frame-triggering=CHNL/FT_LLRe_R_01
              delay=0.02, position-in-table=7, frame-triggering=FT_LLRs_RS_02
              delay=0.01, position-in-table=8, frame-triggering=CHNL/FT_LLRs_RL_01
              delay=0.03, position-in-table=9, frame-triggering=FT_DSs_01
              delay=0.01, position-in-table=10, frame-triggering=CHNL/FT_LLRs_RS_01
              delay=0.01, position-in-table=11, frame-triggering=FT_IONs_01
          st_main_3: run-mode=RUN-CONTINUOUS
            table-entrys:
              delay=0.01, position-in-table=0, frame-triggering=CHNL/FT_LLRe_L_01
              delay=0.01, position-in-table=1, frame-triggering=CHNL/FT_EVe_01_Control
              delay=0.01, position-in-table=2, frame-triggering=FT_LLRs_LS_02
              delay=0.01, position-in-table=3, frame-triggering=FT_DTS2bs_R744_01
              delay=0.02, position-in-table=4, frame-triggering=CHNL/FT_LLRs_LL_01
              delay=0.01, position-in-table=5, frame-triggering=CHNL/FT_EXV1s_01
              delay=0.01, position-in-table=6, frame-triggering=FT_DTS3bs_R744_01
              delay=0.01, position-in-table=7, frame-triggering=CHNL/FT_LLRs_LS_01
              delay=0.01, position-in-table=8, frame-triggering=FT_IONe_01
              delay=0.01, position-in-table=9, frame-triggering=CHNL/FT_LLRe_R_01
              delay=0.01, position-in-table=10, frame-triggering=FT_EXV2s_01
              delay=0.01, position-in-table=11, frame-triggering=FT_LLRs_RS_02
              delay=0.01, position-in-table=12, frame-triggering=FT_DTS2bs_R744_01
              delay=0.02, position-in-table=13, frame-triggering=CHNL/FT_LLRs_RL_01
              delay=0.01, position-in-table=14, frame-triggering=FT_EXV3s_01
              delay=0.01, position-in-table=15, frame-triggering=FT_DTS3bs_R744_01
              delay=0.01, position-in-table=16, frame-triggering=CHNL/FT_LLRs_RS_01
              delay=0.01, position-in-table=17, frame-triggering=FT_IONs_01
